VERSION "dbc-export 1 2025.20.8"

NS_ :

BS_:

BU_: ADSP APB APP APS APSB BB BMS CC CMP CMPD CP DAS DI DIF DIR DPB EPAS3P EPAS3S EPASTP EPASTS EPBL EPBR ESP EVSE FC GTW HCML HCMR HVP IBST ICR IDB LS OCS1P ODIN PARK PCS PLG PM PMF PMR PNCD PTC RADC RCM RCM2 RCM3 RCU SCCM SCM SCS SDCR TAS TCU TPMS TRCM UDS UI UIS UMC USM VC VCFRONT VCLEFT VCRIGHT VCSEC VEH

BO_ 2030 TRCM_alertMatrix: 8 TRCM
 SG_ TRCM_matrixIndex M : 0|4@1+ (1,0) [0|15] "" Vector__XXX
 SG_ TRCM_a003_SWAssertion m0 : 6|1@1+ (1,0) [0|1] "" Vector__XXX
 SG_ TRCM_a005_CANTXError m0 : 8|1@1+ (1,0) [0|1] "" Vector__XXX
 SG_ TRCM_a006_CANTX_cyclicError m0 : 9|1@1+ (1,0) [0|1] "" Vector__XXX
 SG_ TRCM_a007_chassisChecksumError m0 : 10|1@1+ (1,0) [0|1] "" Vector__XXX
 SG_ TRCM_a008_chassisCounterError m0 : 11|1@1+ (1,0) [0|1] "" Vector__XXX
 SG_ TRCM_a009_partyChecksumError m0 : 12|1@1+ (1,0) [0|1] "" Vector__XXX
 SG_ TRCM_a010_partyCounterError m0 : 13|1@1+ (1,0) [0|1] "" Vector__XXX
 SG_ TRCM_a012_asm5TemperatureOutside m0 : 15|1@1+ (1,0) [0|1] "" Vector__XXX
 SG_ TRCM_a013_AlertManagerFault m0 : 16|1@1+ (1,0) [0|1] "" Vector__XXX
 SG_ TRCM_a014_asm3TemperatureOutside m0 : 17|1@1+ (1,0) [0|1] "" Vector__XXX
 SG_ TRCM_a015_NVMMError m0 : 18|1@1+ (1,0) [0|1] "" Vector__XXX
 SG_ TRCM_a016_NVMMRecordError m0 : 19|1@1+ (1,0) [0|1] "" Vector__XXX
 SG_ TRCM_a017_asm5TemperatureOutside m0 : 20|1@1+ (1,0) [0|1] "" Vector__XXX
 SG_ TRCM_a018_asm3TemperatureOutside m0 : 21|1@1+ (1,0) [0|1] "" Vector__XXX
 SG_ TRCM_a019_Task500usError m0 : 22|1@1+ (1,0) [0|1] "" Vector__XXX
 SG_ TRCM_a020_asm3ComStatusError m0 : 23|1@1+ (1,0) [0|1] "" Vector__XXX
 SG_ TRCM_a021_TaskSchedulerError m0 : 24|1@1+ (1,0) [0|1] "" Vector__XXX
 SG_ TRCM_a022_TaskInitError m0 : 25|1@1+ (1,0) [0|1] "" Vector__XXX
 SG_ TRCM_a023_asm3ArsStatusXError m0 : 26|1@1+ (1,0) [0|1] "" Vector__XXX
 SG_ TRCM_a024_asm3AccStatusError m0 : 27|1@1+ (1,0) [0|1] "" Vector__XXX
 SG_ TRCM_a025_CHCANBusFaults m0 : 28|1@1+ (1,0) [0|1] "" Vector__XXX
 SG_ TRCM_a026_airbagAsicDiagnosticFa m0 : 29|1@1+ (1,0) [0|1] "" Vector__XXX
 SG_ TRCM_a027_airbagAsicDeploymentDi m0 : 30|1@1+ (1,0) [0|1] "" Vector__XXX
 SG_ TRCM_a030_ECULogUploadRequest m0 : 33|1@1+ (1,0) [0|1] "" Vector__XXX
 SG_ TRCM_a031_UDSActive m0 : 34|1@1+ (1,0) [0|1] "" Vector__XXX
 SG_ TRCM_a033_HercLogCreated m0 : 36|1@1+ (1,0) [0|1] "" Vector__XXX
 SG_ TRCM_a034_apClipTrigger m0 : 37|1@1+ (1,0) [0|1] "" Vector__XXX
 SG_ TRCM_a035_hvDisconnectCommanded m0 : 38|1@1+ (1,0) [0|1] "" Vector__XXX
 SG_ TRCM_a041_HighCPULoad m0 : 44|1@1+ (1,0) [0|1] "" Vector__XXX
 SG_ TRCM_a042_HighStackUsage m0 : 45|1@1+ (1,0) [0|1] "" Vector__XXX
 SG_ TRCM_a043_Task1msError m0 : 46|1@1+ (1,0) [0|1] "" Vector__XXX
 SG_ TRCM_a044_Task10msError m0 : 47|1@1+ (1,0) [0|1] "" Vector__XXX
 SG_ TRCM_a045_Task100msError m0 : 48|1@1+ (1,0) [0|1] "" Vector__XXX
 SG_ TRCM_a046_Task1000msError m0 : 49|1@1+ (1,0) [0|1] "" Vector__XXX
 SG_ TRCM_a057_HVP_MIA m0 : 60|1@1+ (1,0) [0|1] "" Vector__XXX
 SG_ TRCM_a058_inputRHighSyncDebug m0 : 61|1@1+ (1,0) [0|1] "" Vector__XXX
 SG_ TRCM_a059_inputResistanceHigh m0 : 62|1@1+ (1,0) [0|1] "" Vector__XXX
 SG_ TRCM_a060_engineeringBuild m0 : 63|1@1+ (1,0) [0|1] "" Vector__XXX
 SG_ TRCM_a061_XCPConnected m1 : 4|1@1+ (1,0) [0|1] "" Vector__XXX
 SG_ TRCM_a062_XCPWasConnected m1 : 5|1@1+ (1,0) [0|1] "" Vector__XXX
 SG_ TRCM_a063_SwitchFault m1 : 6|1@1+ (1,0) [0|1] "" Vector__XXX
 SG_ TRCM_a064_busSleepReqTimeout m1 : 7|1@1+ (1,0) [0|1] "" Vector__XXX
 SG_ TRCM_a065_vSafingFetUnderVoltage m1 : 8|1@1+ (1,0) [0|1] "" Vector__XXX
 SG_ TRCM_a066_vBusAUnderVoltage m1 : 9|1@1+ (1,0) [0|1] "" Vector__XXX
 SG_ TRCM_a067_vBusBUnderVoltage m1 : 10|1@1+ (1,0) [0|1] "" Vector__XXX
 SG_ TRCM_a068_vBusCUnderVoltage m1 : 11|1@1+ (1,0) [0|1] "" Vector__XXX
 SG_ TRCM_a069_swAppBoot m1 : 12|1@1+ (1,0) [0|1] "" Vector__XXX
 SG_ TRCM_a070_asm3StatusError m1 : 13|1@1+ (1,0) [0|1] "" Vector__XXX
 SG_ TRCM_a071_asm3DeviceFaulted m1 : 14|1@1+ (1,0) [0|1] "" Vector__XXX
 SG_ TRCM_a072_ais2120StatusError m1 : 15|1@1+ (1,0) [0|1] "" Vector__XXX
 SG_ TRCM_a073_ais2120DeviceFaulted m1 : 16|1@1+ (1,0) [0|1] "" Vector__XXX
 SG_ TRCM_a074_ais2120SelfTestXPositi m1 : 17|1@1+ (1,0) [0|1] "" Vector__XXX
 SG_ TRCM_a075_ais2120SelfTestXNegati m1 : 18|1@1+ (1,0) [0|1] "" Vector__XXX
 SG_ TRCM_a076_ais2120SelfTestYPositi m1 : 19|1@1+ (1,0) [0|1] "" Vector__XXX
 SG_ TRCM_a077_ais2120SelfTestYNegati m1 : 20|1@1+ (1,0) [0|1] "" Vector__XXX
 SG_ TRCM_a081_autarkyActive m1 : 24|1@1+ (1,0) [0|1] "" Vector__XXX
 SG_ TRCM_a082_VCRIGHT_IPC_MIA m1 : 25|1@1+ (1,0) [0|1] "" Vector__XXX
 SG_ TRCM_a083_VCLEFT_IPC_MIA m1 : 26|1@1+ (1,0) [0|1] "" Vector__XXX
 SG_ TRCM_a084_TPMS_MIA m1 : 27|1@1+ (1,0) [0|1] "" Vector__XXX
 SG_ TRCM_a085_CCCM_MIA m1 : 28|1@1+ (1,0) [0|1] "" Vector__XXX
 SG_ TRCM_a086_VCBATT_MIA m1 : 29|1@1+ (1,0) [0|1] "" Vector__XXX
 SG_ TRCM_a087_DIREL_MIA m1 : 30|1@1+ (1,0) [0|1] "" Vector__XXX
 SG_ TRCM_a088_DIRER_MIA m1 : 31|1@1+ (1,0) [0|1] "" Vector__XXX
 SG_ TRCM_a089_IBST_MIA m1 : 32|1@1+ (1,0) [0|1] "" Vector__XXX
 SG_ TRCM_a090_APS_MIA m1 : 33|1@1+ (1,0) [0|1] "" Vector__XXX
 SG_ TRCM_a091_CMPD_MIA m1 : 34|1@1+ (1,0) [0|1] "" Vector__XXX
 SG_ TRCM_a092_VCSEATD_MIA m1 : 35|1@1+ (1,0) [0|1] "" Vector__XXX
 SG_ TRCM_a093_VCSEATP_MIA m1 : 36|1@1+ (1,0) [0|1] "" Vector__XXX
 SG_ TRCM_a094_EPAS3P_MIA m1 : 37|1@1+ (1,0) [0|1] "" Vector__XXX
 SG_ TRCM_a095_CHG_MIA m1 : 38|1@1+ (1,0) [0|1] "" Vector__XXX
 SG_ TRCM_a096_OCS1P_MIA m1 : 39|1@1+ (1,0) [0|1] "" Vector__XXX
 SG_ TRCM_a097_CMP_MIA m1 : 40|1@1+ (1,0) [0|1] "" Vector__XXX
 SG_ TRCM_a098_DIR_MIA m1 : 41|1@1+ (1,0) [0|1] "" Vector__XXX
 SG_ TRCM_a099_PARK_MIA m1 : 42|1@1+ (1,0) [0|1] "" Vector__XXX
 SG_ TRCM_a100_CANbus_MIA m1 : 43|1@1+ (1,0) [0|1] "" Vector__XXX
 SG_ TRCM_a101_PM_MIA m1 : 44|1@1+ (1,0) [0|1] "" Vector__XXX
 SG_ TRCM_a102_PTC_MIA m1 : 45|1@1+ (1,0) [0|1] "" Vector__XXX
 SG_ TRCM_a103_CP_MIA m1 : 46|1@1+ (1,0) [0|1] "" Vector__XXX
 SG_ TRCM_a104_DAS_MIA m1 : 47|1@1+ (1,0) [0|1] "" Vector__XXX
 SG_ TRCM_a105_TAS_MIA m1 : 48|1@1+ (1,0) [0|1] "" Vector__XXX
 SG_ TRCM_a106_PCS_MIA m1 : 49|1@1+ (1,0) [0|1] "" Vector__XXX
 SG_ TRCM_a107_BMS_MIA m1 : 50|1@1+ (1,0) [0|1] "" Vector__XXX
 SG_ TRCM_a108_DIF_MIA m1 : 51|1@1+ (1,0) [0|1] "" Vector__XXX
 SG_ TRCM_a109_RCM_MIA m1 : 52|1@1+ (1,0) [0|1] "" Vector__XXX
 SG_ TRCM_a110_GTW_MIA m1 : 53|1@1+ (1,0) [0|1] "" Vector__XXX
 SG_ TRCM_a111_EPBR_MIA m1 : 54|1@1+ (1,0) [0|1] "" Vector__XXX
 SG_ TRCM_a112_EPBL_MIA m1 : 55|1@1+ (1,0) [0|1] "" Vector__XXX
 SG_ TRCM_a113_UI_MIA m1 : 56|1@1+ (1,0) [0|1] "" Vector__XXX
 SG_ TRCM_a114_ESP_MIA m1 : 57|1@1+ (1,0) [0|1] "" Vector__XXX
 SG_ TRCM_a115_VCSEC_MIA m1 : 58|1@1+ (1,0) [0|1] "" Vector__XXX
 SG_ TRCM_a116_VCRIGHT_MIA m1 : 59|1@1+ (1,0) [0|1] "" Vector__XXX
 SG_ TRCM_a117_VCLEFT_MIA m1 : 60|1@1+ (1,0) [0|1] "" Vector__XXX
 SG_ TRCM_a118_VCFRONT_MIA m1 : 61|1@1+ (1,0) [0|1] "" Vector__XXX
 SG_ TRCM_a119_SCCM_MIA m1 : 62|1@1+ (1,0) [0|1] "" Vector__XXX
 SG_ TRCM_a120_DI_DRIVE_MIA m1 : 63|1@1+ (1,0) [0|1] "" Vector__XXX
 SG_ TRCM_a121_glacierInitialStatusFa m2 : 4|1@1+ (1,0) [0|1] "" Vector__XXX
 SG_ TRCM_a122_glacierTraceabilityRea m2 : 5|1@1+ (1,0) [0|1] "" Vector__XXX
 SG_ TRCM_a123_glacierTraceabilityRea m2 : 6|1@1+ (1,0) [0|1] "" Vector__XXX
 SG_ TRCM_a124_glacierRegisterPattern m2 : 7|1@1+ (1,0) [0|1] "" Vector__XXX
 SG_ TRCM_a125_glacierFixedPatternSel m2 : 8|1@1+ (1,0) [0|1] "" Vector__XXX
 SG_ TRCM_a126_glacierSelfTestEFailur m2 : 9|1@1+ (1,0) [0|1] "" Vector__XXX
 SG_ TRCM_a127_glacierSelfTestFFailur m2 : 10|1@1+ (1,0) [0|1] "" Vector__XXX
 SG_ TRCM_a128_glacierAnalogSelfTestF m2 : 11|1@1+ (1,0) [0|1] "" Vector__XXX
 SG_ TRCM_a129_glacierOscillatorVerif m2 : 12|1@1+ (1,0) [0|1] "" Vector__XXX
 SG_ TRCM_a130_glacierFinalStatusFail m2 : 13|1@1+ (1,0) [0|1] "" Vector__XXX
 SG_ TRCM_a131_glacierOffsetVerificat m2 : 14|1@1+ (1,0) [0|1] "" Vector__XXX
 SG_ TRCM_a132_glacierNormalOperation m2 : 15|1@1+ (1,0) [0|1] "" Vector__XXX
 SG_ TRCM_a133_glacierDeviceReset m2 : 16|1@1+ (1,0) [0|1] "" Vector__XXX
 SG_ TRCM_a134_glacierDeviceFaulted m2 : 17|1@1+ (1,0) [0|1] "" Vector__XXX
 SG_ TRCM_a135_asm5StatusError m2 : 18|1@1+ (1,0) [0|1] "" Vector__XXX
 SG_ TRCM_a136_asm5DeviceFaulted m2 : 19|1@1+ (1,0) [0|1] "" Vector__XXX
 SG_ TRCM_a137_ext1AsicSnoopTestFaile m2 : 20|1@1+ (1,0) [0|1] "" Vector__XXX
 SG_ TRCM_a138_ext2AsicSnoopTestFaile m2 : 21|1@1+ (1,0) [0|1] "" Vector__XXX
 SG_ TRCM_a139_disarmed m2 : 22|1@1+ (1,0) [0|1] "" Vector__XXX
 SG_ TRCM_a140_frontRightAccelInitFai m2 : 23|1@1+ (1,0) [0|1] "" Vector__XXX
 SG_ TRCM_a141_frontRightAccelShortTo m2 : 24|1@1+ (1,0) [0|1] "" Vector__XXX
 SG_ TRCM_a142_frontRightAccelShortTo m2 : 25|1@1+ (1,0) [0|1] "" Vector__XXX
 SG_ TRCM_a143_frontRightAccelConfigE m2 : 26|1@1+ (1,0) [0|1] "" Vector__XXX
 SG_ TRCM_a144_frontRightAccelOpen m2 : 27|1@1+ (1,0) [0|1] "" Vector__XXX
 SG_ TRCM_a145_frontRightAccelCommErr m2 : 28|1@1+ (1,0) [0|1] "" Vector__XXX
 SG_ TRCM_a146_frontRightAccelSensorD m2 : 29|1@1+ (1,0) [0|1] "" Vector__XXX
 SG_ TRCM_a147_frontRightAccelSignalM m2 : 30|1@1+ (1,0) [0|1] "" Vector__XXX
 SG_ TRCM_a150_rightFrontDoorPressure m2 : 33|1@1+ (1,0) [0|1] "" Vector__XXX
 SG_ TRCM_a151_rightFrontDoorPressure m2 : 34|1@1+ (1,0) [0|1] "" Vector__XXX
 SG_ TRCM_a152_rightFrontDoorPressure m2 : 35|1@1+ (1,0) [0|1] "" Vector__XXX
 SG_ TRCM_a153_rightFrontDoorPressure m2 : 36|1@1+ (1,0) [0|1] "" Vector__XXX
 SG_ TRCM_a154_rightFrontDoorPressure m2 : 37|1@1+ (1,0) [0|1] "" Vector__XXX
 SG_ TRCM_a155_rightFrontDoorPressure m2 : 38|1@1+ (1,0) [0|1] "" Vector__XXX
 SG_ TRCM_a156_rightFrontDoorPressure m2 : 39|1@1+ (1,0) [0|1] "" Vector__XXX
 SG_ TRCM_a157_rightFrontDoorPressure m2 : 40|1@1+ (1,0) [0|1] "" Vector__XXX
 SG_ TRCM_a160_frontLeftAccelInitFail m2 : 43|1@1+ (1,0) [0|1] "" Vector__XXX
 SG_ TRCM_a161_frontLeftAccelShortToG m2 : 44|1@1+ (1,0) [0|1] "" Vector__XXX
 SG_ TRCM_a162_frontLeftAccelShortToB m2 : 45|1@1+ (1,0) [0|1] "" Vector__XXX
 SG_ TRCM_a163_frontLeftAccelConfigEr m2 : 46|1@1+ (1,0) [0|1] "" Vector__XXX
 SG_ TRCM_a164_frontLeftAccelOpen m2 : 47|1@1+ (1,0) [0|1] "" Vector__XXX
 SG_ TRCM_a165_frontLeftAccelCommErro m2 : 48|1@1+ (1,0) [0|1] "" Vector__XXX
 SG_ TRCM_a166_frontLeftAccelSensorDe m2 : 49|1@1+ (1,0) [0|1] "" Vector__XXX
 SG_ TRCM_a167_frontLeftAccelSignalMo m2 : 50|1@1+ (1,0) [0|1] "" Vector__XXX
 SG_ TRCM_a170_leftFrontDoorPressureI m2 : 53|1@1+ (1,0) [0|1] "" Vector__XXX
 SG_ TRCM_a171_leftFrontDoorPressureS m2 : 54|1@1+ (1,0) [0|1] "" Vector__XXX
 SG_ TRCM_a172_leftFrontDoorPressureS m2 : 55|1@1+ (1,0) [0|1] "" Vector__XXX
 SG_ TRCM_a173_leftFrontDoorPressureC m2 : 56|1@1+ (1,0) [0|1] "" Vector__XXX
 SG_ TRCM_a174_leftFrontDoorPressureO m2 : 57|1@1+ (1,0) [0|1] "" Vector__XXX
 SG_ TRCM_a175_leftFrontDoorPressureC m2 : 58|1@1+ (1,0) [0|1] "" Vector__XXX
 SG_ TRCM_a176_leftFrontDoorPressureS m2 : 59|1@1+ (1,0) [0|1] "" Vector__XXX
 SG_ TRCM_a177_leftFrontDoorPressureS m2 : 60|1@1+ (1,0) [0|1] "" Vector__XXX
 SG_ TRCM_a180_rightBPillarAccelInitF m2 : 63|1@1+ (1,0) [0|1] "" Vector__XXX
 SG_ TRCM_a181_rightBPillarAccelShort m3 : 4|1@1+ (1,0) [0|1] "" Vector__XXX
 SG_ TRCM_a182_rightBPillarAccelShort m3 : 5|1@1+ (1,0) [0|1] "" Vector__XXX
 SG_ TRCM_a183_rightBPillarAccelConfi m3 : 6|1@1+ (1,0) [0|1] "" Vector__XXX
 SG_ TRCM_a184_rightBPillarAccelOpen m3 : 7|1@1+ (1,0) [0|1] "" Vector__XXX
 SG_ TRCM_a185_rightBPillarAccelCommE m3 : 8|1@1+ (1,0) [0|1] "" Vector__XXX
 SG_ TRCM_a186_rightBPillarAccelSenso m3 : 9|1@1+ (1,0) [0|1] "" Vector__XXX
 SG_ TRCM_a187_rightBPillarAccelSigna m3 : 10|1@1+ (1,0) [0|1] "" Vector__XXX
 SG_ TRCM_a190_leftBPillarAccelInitFa m3 : 13|1@1+ (1,0) [0|1] "" Vector__XXX
 SG_ TRCM_a191_leftBPillarAccelShortT m3 : 14|1@1+ (1,0) [0|1] "" Vector__XXX
 SG_ TRCM_a192_leftBPillarAccelShortT m3 : 15|1@1+ (1,0) [0|1] "" Vector__XXX
 SG_ TRCM_a193_leftBPillarAccelConfig m3 : 16|1@1+ (1,0) [0|1] "" Vector__XXX
 SG_ TRCM_a194_leftBPillarAccelOpen m3 : 17|1@1+ (1,0) [0|1] "" Vector__XXX
 SG_ TRCM_a195_leftBPillarAccelCommEr m3 : 18|1@1+ (1,0) [0|1] "" Vector__XXX
 SG_ TRCM_a196_leftBPillarAccelSensor m3 : 19|1@1+ (1,0) [0|1] "" Vector__XXX
 SG_ TRCM_a197_leftBPillarAccelSignal m3 : 20|1@1+ (1,0) [0|1] "" Vector__XXX
 SG_ TRCM_a200_frontCenterAccelInitFa m3 : 23|1@1+ (1,0) [0|1] "" Vector__XXX
 SG_ TRCM_a201_frontCenterAccelShortT m3 : 24|1@1+ (1,0) [0|1] "" Vector__XXX
 SG_ TRCM_a202_frontCenterAccelShortT m3 : 25|1@1+ (1,0) [0|1] "" Vector__XXX
 SG_ TRCM_a203_frontCenterAccelConfig m3 : 26|1@1+ (1,0) [0|1] "" Vector__XXX
 SG_ TRCM_a204_frontCenterAccelOpen m3 : 27|1@1+ (1,0) [0|1] "" Vector__XXX
 SG_ TRCM_a205_frontCenterAccelCommEr m3 : 28|1@1+ (1,0) [0|1] "" Vector__XXX
 SG_ TRCM_a206_frontCenterAccelSensor m3 : 29|1@1+ (1,0) [0|1] "" Vector__XXX
 SG_ TRCM_a207_frontCenterAccelSignal m3 : 30|1@1+ (1,0) [0|1] "" Vector__XXX
 SG_ TRCM_a210_leftCPillarAccelInitFa m3 : 33|1@1+ (1,0) [0|1] "" Vector__XXX
 SG_ TRCM_a211_leftCPillarAccelShortT m3 : 34|1@1+ (1,0) [0|1] "" Vector__XXX
 SG_ TRCM_a212_leftCPillarAccelShortT m3 : 35|1@1+ (1,0) [0|1] "" Vector__XXX
 SG_ TRCM_a213_leftCPillarAccelConfig m3 : 36|1@1+ (1,0) [0|1] "" Vector__XXX
 SG_ TRCM_a214_leftCPillarAccelOpen m3 : 37|1@1+ (1,0) [0|1] "" Vector__XXX
 SG_ TRCM_a215_leftCPillarAccelCommEr m3 : 38|1@1+ (1,0) [0|1] "" Vector__XXX
 SG_ TRCM_a216_leftCPillarAccelSensor m3 : 39|1@1+ (1,0) [0|1] "" Vector__XXX
 SG_ TRCM_a217_leftCPillarAccelSignal m3 : 40|1@1+ (1,0) [0|1] "" Vector__XXX
 SG_ TRCM_a220_rightCPillarAccelInitF m3 : 43|1@1+ (1,0) [0|1] "" Vector__XXX
 SG_ TRCM_a221_rightCPillarAccelShort m3 : 44|1@1+ (1,0) [0|1] "" Vector__XXX
 SG_ TRCM_a222_rightCPillarAccelShort m3 : 45|1@1+ (1,0) [0|1] "" Vector__XXX
 SG_ TRCM_a223_rightCPillarAccelConfi m3 : 46|1@1+ (1,0) [0|1] "" Vector__XXX
 SG_ TRCM_a224_rightCPillarAccelOpen m3 : 47|1@1+ (1,0) [0|1] "" Vector__XXX
 SG_ TRCM_a225_rightCPillarAccelCommE m3 : 48|1@1+ (1,0) [0|1] "" Vector__XXX
 SG_ TRCM_a226_rightCPillarAccelSenso m3 : 49|1@1+ (1,0) [0|1] "" Vector__XXX
 SG_ TRCM_a227_rightCPillarAccelSigna m3 : 50|1@1+ (1,0) [0|1] "" Vector__XXX
 SG_ TRCM_a230_leftRearDoorPressureIn m3 : 53|1@1+ (1,0) [0|1] "" Vector__XXX
 SG_ TRCM_a231_leftRearDoorPressureSh m3 : 54|1@1+ (1,0) [0|1] "" Vector__XXX
 SG_ TRCM_a232_leftRearDoorPressureSh m3 : 55|1@1+ (1,0) [0|1] "" Vector__XXX
 SG_ TRCM_a233_leftRearDoorPressureCo m3 : 56|1@1+ (1,0) [0|1] "" Vector__XXX
 SG_ TRCM_a234_leftRearDoorPressureOp m3 : 57|1@1+ (1,0) [0|1] "" Vector__XXX
 SG_ TRCM_a235_leftRearDoorPressureCo m3 : 58|1@1+ (1,0) [0|1] "" Vector__XXX
 SG_ TRCM_a236_leftRearDoorPressureSe m3 : 59|1@1+ (1,0) [0|1] "" Vector__XXX
 SG_ TRCM_a237_leftRearDoorPressureSi m3 : 60|1@1+ (1,0) [0|1] "" Vector__XXX
 SG_ TRCM_a240_rightRearDoorPressureI m3 : 63|1@1+ (1,0) [0|1] "" Vector__XXX
 SG_ TRCM_a241_rightRearDoorPressureS m4 : 4|1@1+ (1,0) [0|1] "" Vector__XXX
 SG_ TRCM_a242_rightRearDoorPressureS m4 : 5|1@1+ (1,0) [0|1] "" Vector__XXX
 SG_ TRCM_a243_rightRearDoorPressureC m4 : 6|1@1+ (1,0) [0|1] "" Vector__XXX
 SG_ TRCM_a244_rightRearDoorPressureO m4 : 7|1@1+ (1,0) [0|1] "" Vector__XXX
 SG_ TRCM_a245_rightRearDoorPressureC m4 : 8|1@1+ (1,0) [0|1] "" Vector__XXX
 SG_ TRCM_a246_rightRearDoorPressureS m4 : 9|1@1+ (1,0) [0|1] "" Vector__XXX
 SG_ TRCM_a247_rightRearDoorPressureS m4 : 10|1@1+ (1,0) [0|1] "" Vector__XXX
 SG_ TRCM_a250_frontCenterAccelXInitF m4 : 13|1@1+ (1,0) [0|1] "" Vector__XXX
 SG_ TRCM_a251_frontCenterAccelXShort m4 : 14|1@1+ (1,0) [0|1] "" Vector__XXX
 SG_ TRCM_a252_frontCenterAccelXShort m4 : 15|1@1+ (1,0) [0|1] "" Vector__XXX
 SG_ TRCM_a253_frontCenterAccelXConfi m4 : 16|1@1+ (1,0) [0|1] "" Vector__XXX
 SG_ TRCM_a254_frontCenterAccelXOpen m4 : 17|1@1+ (1,0) [0|1] "" Vector__XXX
 SG_ TRCM_a255_frontCenterAccelXCommE m4 : 18|1@1+ (1,0) [0|1] "" Vector__XXX
 SG_ TRCM_a256_frontCenterAccelXSenso m4 : 19|1@1+ (1,0) [0|1] "" Vector__XXX
 SG_ TRCM_a257_frontCenterAccelXSigna m4 : 20|1@1+ (1,0) [0|1] "" Vector__XXX
 SG_ TRCM_a260_frontCenterAccelYInitF m4 : 23|1@1+ (1,0) [0|1] "" Vector__XXX
 SG_ TRCM_a261_frontCenterAccelYShort m4 : 24|1@1+ (1,0) [0|1] "" Vector__XXX
 SG_ TRCM_a262_frontCenterAccelYShort m4 : 25|1@1+ (1,0) [0|1] "" Vector__XXX
 SG_ TRCM_a263_frontCenterAccelYConfi m4 : 26|1@1+ (1,0) [0|1] "" Vector__XXX
 SG_ TRCM_a264_frontCenterAccelYOpen m4 : 27|1@1+ (1,0) [0|1] "" Vector__XXX
 SG_ TRCM_a265_frontCenterAccelYCommE m4 : 28|1@1+ (1,0) [0|1] "" Vector__XXX
 SG_ TRCM_a266_frontCenterAccelYSenso m4 : 29|1@1+ (1,0) [0|1] "" Vector__XXX
 SG_ TRCM_a267_frontCenterAccelYSigna m4 : 30|1@1+ (1,0) [0|1] "" Vector__XXX
 SG_ TRCM_a272_asm5ComStatusError m4 : 35|1@1+ (1,0) [0|1] "" Vector__XXX
 SG_ TRCM_a273_asm5ArsStatusXError m4 : 36|1@1+ (1,0) [0|1] "" Vector__XXX
 SG_ TRCM_a274_asm5ArsStatusZError m4 : 37|1@1+ (1,0) [0|1] "" Vector__XXX
 SG_ TRCM_a275_asm5AccStatusError m4 : 38|1@1+ (1,0) [0|1] "" Vector__XXX
 SG_ TRCM_a276_watchdogStatus m4 : 39|1@1+ (1,0) [0|1] "" Vector__XXX
 SG_ TRCM_a278_safingEngine0Armed m4 : 41|1@1+ (1,0) [0|1] "" Vector__XXX
 SG_ TRCM_a279_safingEngine1Armed m4 : 42|1@1+ (1,0) [0|1] "" Vector__XXX
 SG_ TRCM_a280_safingEngine2Armed m4 : 43|1@1+ (1,0) [0|1] "" Vector__XXX
 SG_ TRCM_a281_safingEngine3Armed m4 : 44|1@1+ (1,0) [0|1] "" Vector__XXX
 SG_ TRCM_a282_safingEngine4Armed m4 : 45|1@1+ (1,0) [0|1] "" Vector__XXX
 SG_ TRCM_a283_safingEngine5Armed m4 : 46|1@1+ (1,0) [0|1] "" Vector__XXX
 SG_ TRCM_a284_safingEngine6Armed m4 : 47|1@1+ (1,0) [0|1] "" Vector__XXX
 SG_ TRCM_a285_safingEngine7Armed m4 : 48|1@1+ (1,0) [0|1] "" Vector__XXX
 SG_ TRCM_a286_safingEngine8Armed m4 : 49|1@1+ (1,0) [0|1] "" Vector__XXX
 SG_ TRCM_a287_safingEngine9Armed m4 : 50|1@1+ (1,0) [0|1] "" Vector__XXX
 SG_ TRCM_a288_safingEngine10Armed m4 : 51|1@1+ (1,0) [0|1] "" Vector__XXX
 SG_ TRCM_a289_safingEngine11Armed m4 : 52|1@1+ (1,0) [0|1] "" Vector__XXX
 SG_ TRCM_a290_safingEngine12Armed m4 : 53|1@1+ (1,0) [0|1] "" Vector__XXX
 SG_ TRCM_a291_safingEngine13Armed m4 : 54|1@1+ (1,0) [0|1] "" Vector__XXX
 SG_ TRCM_a292_safingEngine14Armed m4 : 55|1@1+ (1,0) [0|1] "" Vector__XXX
 SG_ TRCM_a293_safingEngine15Armed m4 : 56|1@1+ (1,0) [0|1] "" Vector__XXX
 SG_ TRCM_a294_safingEngine16Armed m4 : 57|1@1+ (1,0) [0|1] "" Vector__XXX
 SG_ TRCM_a295_safingEngine17Armed m4 : 58|1@1+ (1,0) [0|1] "" Vector__XXX
 SG_ TRCM_a296_safingEngine18Armed m4 : 59|1@1+ (1,0) [0|1] "" Vector__XXX
 SG_ TRCM_a297_safingEngine19Armed m4 : 60|1@1+ (1,0) [0|1] "" Vector__XXX
 SG_ TRCM_a298_safingEngine20Armed m4 : 61|1@1+ (1,0) [0|1] "" Vector__XXX
 SG_ TRCM_a299_safingEngine21Armed m4 : 62|1@1+ (1,0) [0|1] "" Vector__XXX
 SG_ TRCM_a300_unarmedAB1FPDeployComm m4 : 63|1@1+ (1,0) [0|1] "" Vector__XXX
 SG_ TRCM_a301_unarmedAB1FDDeployComm m5 : 4|1@1+ (1,0) [0|1] "" Vector__XXX
 SG_ TRCM_a302_unarmedAV1FPDeployComm m5 : 5|1@1+ (1,0) [0|1] "" Vector__XXX
 SG_ TRCM_a303_unarmedFSABDeployComma m5 : 6|1@1+ (1,0) [0|1] "" Vector__XXX
 SG_ TRCM_a304_unarmedAB2FPDeployComm m5 : 7|1@1+ (1,0) [0|1] "" Vector__XXX
 SG_ TRCM_a305_unarmedAB2FDDeployComm m5 : 8|1@1+ (1,0) [0|1] "" Vector__XXX
 SG_ TRCM_a306_unarmedAV1FDDeployComm m5 : 9|1@1+ (1,0) [0|1] "" Vector__XXX
 SG_ TRCM_a307_unarmedLoop7DeployComm m5 : 10|1@1+ (1,0) [0|1] "" Vector__XXX
 SG_ TRCM_a308_unarmedKA1FPDeployComm m5 : 11|1@1+ (1,0) [0|1] "" Vector__XXX
 SG_ TRCM_a309_unarmedKA1FDDeployComm m5 : 12|1@1+ (1,0) [0|1] "" Vector__XXX
 SG_ TRCM_a310_unarmedALLFRDeployComm m5 : 13|1@1+ (1,0) [0|1] "" Vector__XXX
 SG_ TRCM_a311_unarmedALLFLDeployComm m5 : 14|1@1+ (1,0) [0|1] "" Vector__XXX
 SG_ TRCM_a312_unarmedBT2FRDeployComm m5 : 15|1@1+ (1,0) [0|1] "" Vector__XXX
 SG_ TRCM_a313_unarmedBT2FLDeployComm m5 : 16|1@1+ (1,0) [0|1] "" Vector__XXX
 SG_ TRCM_a314_unarmedSA1FLDeployComm m5 : 17|1@1+ (1,0) [0|1] "" Vector__XXX
 SG_ TRCM_a315_unarmedSA1FRDeployComm m5 : 18|1@1+ (1,0) [0|1] "" Vector__XXX
 SG_ TRCM_a316_unarmedBT1RRDeployComm m5 : 19|1@1+ (1,0) [0|1] "" Vector__XXX
 SG_ TRCM_a317_unarmedBT1RLDeployComm m5 : 20|1@1+ (1,0) [0|1] "" Vector__XXX
 SG_ TRCM_a318_unarmedBT1FRDeployComm m5 : 21|1@1+ (1,0) [0|1] "" Vector__XXX
 SG_ TRCM_a319_unarmedBT1FLDeployComm m5 : 22|1@1+ (1,0) [0|1] "" Vector__XXX
 SG_ TRCM_a320_unarmedLoop20DeployCom m5 : 23|1@1+ (1,0) [0|1] "" Vector__XXX
 SG_ TRCM_a321_unarmedLoop21DeployCom m5 : 24|1@1+ (1,0) [0|1] "" Vector__XXX
 SG_ TRCM_a322_unarmedIC1FRDeployComm m5 : 25|1@1+ (1,0) [0|1] "" Vector__XXX
 SG_ TRCM_a323_unarmedIC1FLDeployComm m5 : 26|1@1+ (1,0) [0|1] "" Vector__XXX
 SG_ TRCM_a324_unarmedLoop24DeployCom m5 : 27|1@1+ (1,0) [0|1] "" Vector__XXX
 SG_ TRCM_a325_unarmedLoop25DeployCom m5 : 28|1@1+ (1,0) [0|1] "" Vector__XXX
 SG_ TRCM_a326_unarmedLoop26DeployCom m5 : 29|1@1+ (1,0) [0|1] "" Vector__XXX
 SG_ TRCM_a327_unarmedLoop27DeployCom m5 : 30|1@1+ (1,0) [0|1] "" Vector__XXX
 SG_ TRCM_a328_unarmedLoop28DeployCom m5 : 31|1@1+ (1,0) [0|1] "" Vector__XXX
 SG_ TRCM_a329_unarmedLoop29DeployCom m5 : 32|1@1+ (1,0) [0|1] "" Vector__XXX
 SG_ TRCM_a330_unarmedLoop30DeployCom m5 : 33|1@1+ (1,0) [0|1] "" Vector__XXX
 SG_ TRCM_a331_unarmedLoop31DeployCom m5 : 34|1@1+ (1,0) [0|1] "" Vector__XXX
 SG_ TRCM_a332_AB1FPDeployment m5 : 35|1@1+ (1,0) [0|1] "" Vector__XXX
 SG_ TRCM_a333_AB1FDDeployment m5 : 36|1@1+ (1,0) [0|1] "" Vector__XXX
 SG_ TRCM_a334_AV1FPDeployment m5 : 37|1@1+ (1,0) [0|1] "" Vector__XXX
 SG_ TRCM_a335_Loop3Deployment m5 : 38|1@1+ (1,0) [0|1] "" Vector__XXX
 SG_ TRCM_a336_AB2FPDeployment m5 : 39|1@1+ (1,0) [0|1] "" Vector__XXX
 SG_ TRCM_a337_AB2FDDeployment m5 : 40|1@1+ (1,0) [0|1] "" Vector__XXX
 SG_ TRCM_a338_AV1FDDeployment m5 : 41|1@1+ (1,0) [0|1] "" Vector__XXX
 SG_ TRCM_a339_Loop7Deployment m5 : 42|1@1+ (1,0) [0|1] "" Vector__XXX
 SG_ TRCM_a340_KA1FPDeployment m5 : 43|1@1+ (1,0) [0|1] "" Vector__XXX
 SG_ TRCM_a341_KA1FDDeployment m5 : 44|1@1+ (1,0) [0|1] "" Vector__XXX
 SG_ TRCM_a342_ALLFRDeployment m5 : 45|1@1+ (1,0) [0|1] "" Vector__XXX
 SG_ TRCM_a343_ALLFLDeployment m5 : 46|1@1+ (1,0) [0|1] "" Vector__XXX
 SG_ TRCM_a344_BT2FRDeployment m5 : 47|1@1+ (1,0) [0|1] "" Vector__XXX
 SG_ TRCM_a345_BT2FLDeployment m5 : 48|1@1+ (1,0) [0|1] "" Vector__XXX
 SG_ TRCM_a346_SA1FLDeployment m5 : 49|1@1+ (1,0) [0|1] "" Vector__XXX
 SG_ TRCM_a347_SA1FRDeployment m5 : 50|1@1+ (1,0) [0|1] "" Vector__XXX
 SG_ TRCM_a348_BT1RRDeployment m5 : 51|1@1+ (1,0) [0|1] "" Vector__XXX
 SG_ TRCM_a349_BT1RLDeployment m5 : 52|1@1+ (1,0) [0|1] "" Vector__XXX
 SG_ TRCM_a350_BT1FRDeployment m5 : 53|1@1+ (1,0) [0|1] "" Vector__XXX
 SG_ TRCM_a351_BT1FLDeployment m5 : 54|1@1+ (1,0) [0|1] "" Vector__XXX
 SG_ TRCM_a352_Loop20Deployment m5 : 55|1@1+ (1,0) [0|1] "" Vector__XXX
 SG_ TRCM_a353_Loop21Deployment m5 : 56|1@1+ (1,0) [0|1] "" Vector__XXX
 SG_ TRCM_a354_IC1FRDeployment m5 : 57|1@1+ (1,0) [0|1] "" Vector__XXX
 SG_ TRCM_a355_IC1FLDeployment m5 : 58|1@1+ (1,0) [0|1] "" Vector__XXX
 SG_ TRCM_a356_Loop24Deployment m5 : 59|1@1+ (1,0) [0|1] "" Vector__XXX
 SG_ TRCM_a357_Loop25Deployment m5 : 60|1@1+ (1,0) [0|1] "" Vector__XXX
 SG_ TRCM_a358_Loop26Deployment m5 : 61|1@1+ (1,0) [0|1] "" Vector__XXX
 SG_ TRCM_a359_Loop27Deployment m5 : 62|1@1+ (1,0) [0|1] "" Vector__XXX
 SG_ TRCM_a360_Loop28Deployment m5 : 63|1@1+ (1,0) [0|1] "" Vector__XXX
 SG_ TRCM_a361_Loop29Deployment m6 : 4|1@1+ (1,0) [0|1] "" Vector__XXX
 SG_ TRCM_a362_Loop30Deployment m6 : 5|1@1+ (1,0) [0|1] "" Vector__XXX
 SG_ TRCM_a363_Loop31Deployment m6 : 6|1@1+ (1,0) [0|1] "" Vector__XXX
 SG_ TRCM_a364_safingEngine0NoValidDa m6 : 7|1@1+ (1,0) [0|1] "" Vector__XXX
 SG_ TRCM_a365_safingEngine1NoValidDa m6 : 8|1@1+ (1,0) [0|1] "" Vector__XXX
 SG_ TRCM_a366_safingEngine2NoValidDa m6 : 9|1@1+ (1,0) [0|1] "" Vector__XXX
 SG_ TRCM_a367_safingEngine3NoValidDa m6 : 10|1@1+ (1,0) [0|1] "" Vector__XXX
 SG_ TRCM_a368_safingEngine4NoValidDa m6 : 11|1@1+ (1,0) [0|1] "" Vector__XXX
 SG_ TRCM_a369_safingEngine5NoValidDa m6 : 12|1@1+ (1,0) [0|1] "" Vector__XXX
 SG_ TRCM_a370_safingEngine6NoValidDa m6 : 13|1@1+ (1,0) [0|1] "" Vector__XXX
 SG_ TRCM_a371_safingEngine7NoValidDa m6 : 14|1@1+ (1,0) [0|1] "" Vector__XXX
 SG_ TRCM_a372_safingEngine8NoValidDa m6 : 15|1@1+ (1,0) [0|1] "" Vector__XXX
 SG_ TRCM_a373_safingEngine9NoValidDa m6 : 16|1@1+ (1,0) [0|1] "" Vector__XXX
 SG_ TRCM_a374_safingEngine10NoValidD m6 : 17|1@1+ (1,0) [0|1] "" Vector__XXX
 SG_ TRCM_a375_safingEngine11NoValidD m6 : 18|1@1+ (1,0) [0|1] "" Vector__XXX
 SG_ TRCM_a376_safingEngine12NoValidD m6 : 19|1@1+ (1,0) [0|1] "" Vector__XXX
 SG_ TRCM_a377_safingEngine13NoValidD m6 : 20|1@1+ (1,0) [0|1] "" Vector__XXX
 SG_ TRCM_a378_safingEngine14NoValidD m6 : 21|1@1+ (1,0) [0|1] "" Vector__XXX
 SG_ TRCM_a379_safingEngine15NoValidD m6 : 22|1@1+ (1,0) [0|1] "" Vector__XXX
 SG_ TRCM_a380_safingEngine16NoValidD m6 : 23|1@1+ (1,0) [0|1] "" Vector__XXX
 SG_ TRCM_a381_safingEngine17NoValidD m6 : 24|1@1+ (1,0) [0|1] "" Vector__XXX
 SG_ TRCM_a382_safingEngine18NoValidD m6 : 25|1@1+ (1,0) [0|1] "" Vector__XXX
 SG_ TRCM_a383_safingEngine19NoValidD m6 : 26|1@1+ (1,0) [0|1] "" Vector__XXX
 SG_ TRCM_a384_safingEngine20NoValidD m6 : 27|1@1+ (1,0) [0|1] "" Vector__XXX
 SG_ TRCM_a385_safingEngine21NoValidD m6 : 28|1@1+ (1,0) [0|1] "" Vector__XXX
 SG_ TRCM_a387_primaryAsicResetSource m6 : 30|1@1+ (1,0) [0|1] "" Vector__XXX
 SG_ TRCM_a388_cpuLoadHigh m6 : 31|1@1+ (1,0) [0|1] "" Vector__XXX
 SG_ TRCM_a389_asicPwrStatusError m6 : 32|1@1+ (1,0) [0|1] "" Vector__XXX
 SG_ TRCM_a390_systemAsicClockOrOpera m6 : 33|1@1+ (1,0) [0|1] "" Vector__XXX
 SG_ TRCM_a391_extAsic1ClockOrOperati m6 : 34|1@1+ (1,0) [0|1] "" Vector__XXX
 SG_ TRCM_a392_extAsic2ClockOrOperati m6 : 35|1@1+ (1,0) [0|1] "" Vector__XXX
 SG_ TRCM_a393_depAdcConvertRatioErro m6 : 36|1@1+ (1,0) [0|1] "" Vector__XXX
 SG_ TRCM_a394_gspiGlobalStatusWordEr m6 : 37|1@1+ (1,0) [0|1] "" Vector__XXX
 SG_ TRCM_a395_imuCalibrationNotDone m6 : 38|1@1+ (1,0) [0|1] "" Vector__XXX
 SG_ TRCM_a396_spiCommunicationProgra m6 : 39|1@1+ (1,0) [0|1] "" Vector__XXX
 SG_ TRCM_a397_safingMonitorError m6 : 40|1@1+ (1,0) [0|1] "" Vector__XXX
 SG_ TRCM_a398_asicNvmReprogrammed m6 : 41|1@1+ (1,0) [0|1] "" Vector__XXX
 SG_ TRCM_a400_AB1FPShortToGround m6 : 43|1@1+ (1,0) [0|1] "" Vector__XXX
 SG_ TRCM_a401_AB1FPShortToBattery m6 : 44|1@1+ (1,0) [0|1] "" Vector__XXX
 SG_ TRCM_a402_AB1FPOpen m6 : 45|1@1+ (1,0) [0|1] "" Vector__XXX
 SG_ TRCM_a403_AB1FPShortToSelf m6 : 46|1@1+ (1,0) [0|1] "" Vector__XXX
 SG_ TRCM_a404_AB1FPCrossCoupled m6 : 47|1@1+ (1,0) [0|1] "" Vector__XXX
 SG_ TRCM_a405_AB1FPConfigError m6 : 48|1@1+ (1,0) [0|1] "" Vector__XXX
 SG_ TRCM_a406_AB1FDShortToGround m6 : 49|1@1+ (1,0) [0|1] "" Vector__XXX
 SG_ TRCM_a407_AB1FDShortToBattery m6 : 50|1@1+ (1,0) [0|1] "" Vector__XXX
 SG_ TRCM_a408_AB1FDOpen m6 : 51|1@1+ (1,0) [0|1] "" Vector__XXX
 SG_ TRCM_a409_AB1FDShortToSelf m6 : 52|1@1+ (1,0) [0|1] "" Vector__XXX
 SG_ TRCM_a410_AB1FDCrossCoupled m6 : 53|1@1+ (1,0) [0|1] "" Vector__XXX
 SG_ TRCM_a411_AB1FDConfigError m6 : 54|1@1+ (1,0) [0|1] "" Vector__XXX
 SG_ TRCM_a412_PAVShortToGround m6 : 55|1@1+ (1,0) [0|1] "" Vector__XXX
 SG_ TRCM_a413_PAVShortToBattery m6 : 56|1@1+ (1,0) [0|1] "" Vector__XXX
 SG_ TRCM_a414_PAVOpen m6 : 57|1@1+ (1,0) [0|1] "" Vector__XXX
 SG_ TRCM_a415_PAVShortToSelf m6 : 58|1@1+ (1,0) [0|1] "" Vector__XXX
 SG_ TRCM_a416_PAVCrossCoupled m6 : 59|1@1+ (1,0) [0|1] "" Vector__XXX
 SG_ TRCM_a417_PAVConfigError m6 : 60|1@1+ (1,0) [0|1] "" Vector__XXX
 SG_ TRCM_a418_AB2FPShortToGround m6 : 61|1@1+ (1,0) [0|1] "" Vector__XXX
 SG_ TRCM_a419_AB2FPShortToBattery m6 : 62|1@1+ (1,0) [0|1] "" Vector__XXX
 SG_ TRCM_a420_AB2FPOpen m6 : 63|1@1+ (1,0) [0|1] "" Vector__XXX
 SG_ TRCM_a421_AB2FPShortToSelf m7 : 4|1@1+ (1,0) [0|1] "" Vector__XXX
 SG_ TRCM_a422_AB2FPCrossCoupled m7 : 5|1@1+ (1,0) [0|1] "" Vector__XXX
 SG_ TRCM_a423_AB2FPConfigError m7 : 6|1@1+ (1,0) [0|1] "" Vector__XXX
 SG_ TRCM_a424_AB2FDShortToGround m7 : 7|1@1+ (1,0) [0|1] "" Vector__XXX
 SG_ TRCM_a425_AB2FDShortToBattery m7 : 8|1@1+ (1,0) [0|1] "" Vector__XXX
 SG_ TRCM_a426_AB2FDOpen m7 : 9|1@1+ (1,0) [0|1] "" Vector__XXX
 SG_ TRCM_a427_AB2FDShortToSelf m7 : 10|1@1+ (1,0) [0|1] "" Vector__XXX
 SG_ TRCM_a428_AB2FDCrossCoupled m7 : 11|1@1+ (1,0) [0|1] "" Vector__XXX
 SG_ TRCM_a429_AB2FDConfigError m7 : 12|1@1+ (1,0) [0|1] "" Vector__XXX
 SG_ TRCM_a430_DAVShortToGround m7 : 13|1@1+ (1,0) [0|1] "" Vector__XXX
 SG_ TRCM_a431_DAVShortToBattery m7 : 14|1@1+ (1,0) [0|1] "" Vector__XXX
 SG_ TRCM_a432_DAVOpen m7 : 15|1@1+ (1,0) [0|1] "" Vector__XXX
 SG_ TRCM_a433_DAVShortToSelf m7 : 16|1@1+ (1,0) [0|1] "" Vector__XXX
 SG_ TRCM_a434_DAVCrossCoupled m7 : 17|1@1+ (1,0) [0|1] "" Vector__XXX
 SG_ TRCM_a435_DAVConfigError m7 : 18|1@1+ (1,0) [0|1] "" Vector__XXX
 SG_ TRCM_a436_IKBFPShortToGround m7 : 19|1@1+ (1,0) [0|1] "" Vector__XXX
 SG_ TRCM_a437_IKBFPShortToBattery m7 : 20|1@1+ (1,0) [0|1] "" Vector__XXX
 SG_ TRCM_a438_IKBFPOpen m7 : 21|1@1+ (1,0) [0|1] "" Vector__XXX
 SG_ TRCM_a439_IKBFPShortToSelf m7 : 22|1@1+ (1,0) [0|1] "" Vector__XXX
 SG_ TRCM_a440_IKBFPCrossCoupled m7 : 23|1@1+ (1,0) [0|1] "" Vector__XXX
 SG_ TRCM_a441_IKBFPConfigError m7 : 24|1@1+ (1,0) [0|1] "" Vector__XXX
 SG_ TRCM_a442_IKBFDShortToGround m7 : 25|1@1+ (1,0) [0|1] "" Vector__XXX
 SG_ TRCM_a443_IKBFDShortToBattery m7 : 26|1@1+ (1,0) [0|1] "" Vector__XXX
 SG_ TRCM_a444_IKBFDOpen m7 : 27|1@1+ (1,0) [0|1] "" Vector__XXX
 SG_ TRCM_a445_IKBFDShortToSelf m7 : 28|1@1+ (1,0) [0|1] "" Vector__XXX
 SG_ TRCM_a446_IKBFDCrossCoupled m7 : 29|1@1+ (1,0) [0|1] "" Vector__XXX
 SG_ TRCM_a447_IKBFDConfigError m7 : 30|1@1+ (1,0) [0|1] "" Vector__XXX
 SG_ TRCM_a448_PLLShortToGround m7 : 31|1@1+ (1,0) [0|1] "" Vector__XXX
 SG_ TRCM_a449_PLLShortToBattery m7 : 32|1@1+ (1,0) [0|1] "" Vector__XXX
 SG_ TRCM_a450_PLLOpen m7 : 33|1@1+ (1,0) [0|1] "" Vector__XXX
 SG_ TRCM_a451_PLLShortToSelf m7 : 34|1@1+ (1,0) [0|1] "" Vector__XXX
 SG_ TRCM_a452_PLLCrossCoupled m7 : 35|1@1+ (1,0) [0|1] "" Vector__XXX
 SG_ TRCM_a453_PLLConfigError m7 : 36|1@1+ (1,0) [0|1] "" Vector__XXX
 SG_ TRCM_a454_DLLShortToGround m7 : 37|1@1+ (1,0) [0|1] "" Vector__XXX
 SG_ TRCM_a455_DLLShortToBattery m7 : 38|1@1+ (1,0) [0|1] "" Vector__XXX
 SG_ TRCM_a456_DLLOpen m7 : 39|1@1+ (1,0) [0|1] "" Vector__XXX
 SG_ TRCM_a457_DLLShortToSelf m7 : 40|1@1+ (1,0) [0|1] "" Vector__XXX
 SG_ TRCM_a458_DLLCrossCoupled m7 : 41|1@1+ (1,0) [0|1] "" Vector__XXX
 SG_ TRCM_a459_DLLConfigError m7 : 42|1@1+ (1,0) [0|1] "" Vector__XXX
 SG_ TRCM_a460_BTRP_RetractorShortToG m7 : 43|1@1+ (1,0) [0|1] "" Vector__XXX
 SG_ TRCM_a461_BTRP_RetractorShortToB m7 : 44|1@1+ (1,0) [0|1] "" Vector__XXX
 SG_ TRCM_a462_BTRP_RetractorOpen m7 : 45|1@1+ (1,0) [0|1] "" Vector__XXX
 SG_ TRCM_a463_BTRP_RetractorShortToS m7 : 46|1@1+ (1,0) [0|1] "" Vector__XXX
 SG_ TRCM_a464_BTRP_RetractorCrossCou m7 : 47|1@1+ (1,0) [0|1] "" Vector__XXX
 SG_ TRCM_a465_BTRP_RetractorConfigEr m7 : 48|1@1+ (1,0) [0|1] "" Vector__XXX
 SG_ TRCM_a466_BTRD_RetractorShortToG m7 : 49|1@1+ (1,0) [0|1] "" Vector__XXX
 SG_ TRCM_a467_BTRD_RetractorShortToB m7 : 50|1@1+ (1,0) [0|1] "" Vector__XXX
 SG_ TRCM_a468_BTRD_RetractorOpen m7 : 51|1@1+ (1,0) [0|1] "" Vector__XXX
 SG_ TRCM_a469_BTRD_RetractorShortToS m7 : 52|1@1+ (1,0) [0|1] "" Vector__XXX
 SG_ TRCM_a470_BTRD_RetractorCrossCou m7 : 53|1@1+ (1,0) [0|1] "" Vector__XXX
 SG_ TRCM_a471_BTRD_RetractorConfigEr m7 : 54|1@1+ (1,0) [0|1] "" Vector__XXX
 SG_ TRCM_a472_SA1FLShortToGround m7 : 55|1@1+ (1,0) [0|1] "" Vector__XXX
 SG_ TRCM_a473_SA1FLShortToBattery m7 : 56|1@1+ (1,0) [0|1] "" Vector__XXX
 SG_ TRCM_a474_SA1FLOpen m7 : 57|1@1+ (1,0) [0|1] "" Vector__XXX
 SG_ TRCM_a475_SA1FLShortToSelf m7 : 58|1@1+ (1,0) [0|1] "" Vector__XXX
 SG_ TRCM_a476_SA1FLCrossCoupled m7 : 59|1@1+ (1,0) [0|1] "" Vector__XXX
 SG_ TRCM_a477_SA1FLConfigError m7 : 60|1@1+ (1,0) [0|1] "" Vector__XXX
 SG_ TRCM_a478_SA1FRShortToGround m7 : 61|1@1+ (1,0) [0|1] "" Vector__XXX
 SG_ TRCM_a479_SA1FRShortToBattery m7 : 62|1@1+ (1,0) [0|1] "" Vector__XXX
 SG_ TRCM_a480_SA1FROpen m7 : 63|1@1+ (1,0) [0|1] "" Vector__XXX
 SG_ TRCM_a481_SA1FRShortToSelf m8 : 4|1@1+ (1,0) [0|1] "" Vector__XXX
 SG_ TRCM_a482_SA1FRCrossCoupled m8 : 5|1@1+ (1,0) [0|1] "" Vector__XXX
 SG_ TRCM_a483_SA1FRConfigError m8 : 6|1@1+ (1,0) [0|1] "" Vector__XXX
 SG_ TRCM_a484_BTRRShortToGround m8 : 7|1@1+ (1,0) [0|1] "" Vector__XXX
 SG_ TRCM_a485_BTRRShortToBattery m8 : 8|1@1+ (1,0) [0|1] "" Vector__XXX
 SG_ TRCM_a486_BTRROpen m8 : 9|1@1+ (1,0) [0|1] "" Vector__XXX
 SG_ TRCM_a487_BTRRShortToSelf m8 : 10|1@1+ (1,0) [0|1] "" Vector__XXX
 SG_ TRCM_a488_BTRRCrossCoupled m8 : 11|1@1+ (1,0) [0|1] "" Vector__XXX
 SG_ TRCM_a489_BTRRConfigError m8 : 12|1@1+ (1,0) [0|1] "" Vector__XXX
 SG_ TRCM_a490_BTRLShortToGround m8 : 13|1@1+ (1,0) [0|1] "" Vector__XXX
 SG_ TRCM_a491_BTRLShortToBattery m8 : 14|1@1+ (1,0) [0|1] "" Vector__XXX
 SG_ TRCM_a492_BTRLOpen m8 : 15|1@1+ (1,0) [0|1] "" Vector__XXX
 SG_ TRCM_a493_BTRLShortToSelf m8 : 16|1@1+ (1,0) [0|1] "" Vector__XXX
 SG_ TRCM_a494_BTRLCrossCoupled m8 : 17|1@1+ (1,0) [0|1] "" Vector__XXX
 SG_ TRCM_a495_BTRLConfigError m8 : 18|1@1+ (1,0) [0|1] "" Vector__XXX
 SG_ TRCM_a496_BTRP_AnchorShortToGrou m8 : 19|1@1+ (1,0) [0|1] "" Vector__XXX
 SG_ TRCM_a497_BTRP_AnchorShortToBatt m8 : 20|1@1+ (1,0) [0|1] "" Vector__XXX
 SG_ TRCM_a498_BTRP_AnchorOpen m8 : 21|1@1+ (1,0) [0|1] "" Vector__XXX
 SG_ TRCM_a499_BTRP_AnchorShortToSelf m8 : 22|1@1+ (1,0) [0|1] "" Vector__XXX
 SG_ TRCM_a500_BTRP_AnchorCrossCouple m8 : 23|1@1+ (1,0) [0|1] "" Vector__XXX
 SG_ TRCM_a501_BTRP_AnchorConfigError m8 : 24|1@1+ (1,0) [0|1] "" Vector__XXX
 SG_ TRCM_a502_BTRD_AnchorShortToGrou m8 : 25|1@1+ (1,0) [0|1] "" Vector__XXX
 SG_ TRCM_a503_BTRD_AnchorShortToBatt m8 : 26|1@1+ (1,0) [0|1] "" Vector__XXX
 SG_ TRCM_a504_BTRD_AnchorOpen m8 : 27|1@1+ (1,0) [0|1] "" Vector__XXX
 SG_ TRCM_a505_BTRD_AnchorShortToSelf m8 : 28|1@1+ (1,0) [0|1] "" Vector__XXX
 SG_ TRCM_a506_BTRD_AnchorCrossCouple m8 : 29|1@1+ (1,0) [0|1] "" Vector__XXX
 SG_ TRCM_a507_BTRD_AnchorConfigError m8 : 30|1@1+ (1,0) [0|1] "" Vector__XXX
 SG_ TRCM_a508_IC1FRShortToGround m8 : 31|1@1+ (1,0) [0|1] "" Vector__XXX
 SG_ TRCM_a509_IC1FRShortToBattery m8 : 32|1@1+ (1,0) [0|1] "" Vector__XXX
 SG_ TRCM_a510_IC1FROpen m8 : 33|1@1+ (1,0) [0|1] "" Vector__XXX
 SG_ TRCM_a511_IC1FRShortToSelf m8 : 34|1@1+ (1,0) [0|1] "" Vector__XXX
 SG_ TRCM_a512_IC1FRCrossCoupled m8 : 35|1@1+ (1,0) [0|1] "" Vector__XXX
 SG_ TRCM_a513_IC1FRConfigError m8 : 36|1@1+ (1,0) [0|1] "" Vector__XXX
 SG_ TRCM_a514_IC1FLShortToGround m8 : 37|1@1+ (1,0) [0|1] "" Vector__XXX
 SG_ TRCM_a515_IC1FLShortToBattery m8 : 38|1@1+ (1,0) [0|1] "" Vector__XXX
 SG_ TRCM_a516_IC1FLOpen m8 : 39|1@1+ (1,0) [0|1] "" Vector__XXX
 SG_ TRCM_a517_IC1FLShortToSelf m8 : 40|1@1+ (1,0) [0|1] "" Vector__XXX
 SG_ TRCM_a518_IC1FLCrossCoupled m8 : 41|1@1+ (1,0) [0|1] "" Vector__XXX
 SG_ TRCM_a519_IC1FLConfigError m8 : 42|1@1+ (1,0) [0|1] "" Vector__XXX
 SG_ TRCM_a520_FSABShortToGround m8 : 43|1@1+ (1,0) [0|1] "" Vector__XXX
 SG_ TRCM_a521_FSABShortToBattery m8 : 44|1@1+ (1,0) [0|1] "" Vector__XXX
 SG_ TRCM_a522_FSABOpen m8 : 45|1@1+ (1,0) [0|1] "" Vector__XXX
 SG_ TRCM_a523_FSABShortToSelf m8 : 46|1@1+ (1,0) [0|1] "" Vector__XXX
 SG_ TRCM_a524_FSABCrossCoupled m8 : 47|1@1+ (1,0) [0|1] "" Vector__XXX
 SG_ TRCM_a525_FSABConfigError m8 : 48|1@1+ (1,0) [0|1] "" Vector__XXX
 SG_ TRCM_a544_erCapDiagnosticsFailed m9 : 7|1@1+ (1,0) [0|1] "" Vector__XXX
 SG_ TRCM_a545_erCapBelowAutarkyThres m9 : 8|1@1+ (1,0) [0|1] "" Vector__XXX
 SG_ TRCM_a546_sensorValuesFaultedByS m9 : 9|1@1+ (1,0) [0|1] "" Vector__XXX
 SG_ TRCM_a550_AlgoWake_RCM_WAKE_FRON m9 : 13|1@1+ (1,0) [0|1] "" Vector__XXX
 SG_ TRCM_a551_AlgoWake_RCM_WAKE_REAR m9 : 14|1@1+ (1,0) [0|1] "" Vector__XXX
 SG_ TRCM_a552_AlgoWake_RCM_WAKE_LEFT m9 : 15|1@1+ (1,0) [0|1] "" Vector__XXX
 SG_ TRCM_a553_AlgoWake_RCM_WAKE_RIGH m9 : 16|1@1+ (1,0) [0|1] "" Vector__XXX
 SG_ TRCM_a554_AlgoWake_PAS_LH_PLAUSI m9 : 17|1@1+ (1,0) [0|1] "" Vector__XXX
 SG_ TRCM_a555_AlgoWake_PAS_LH_PLAUSI m9 : 18|1@1+ (1,0) [0|1] "" Vector__XXX
 SG_ TRCM_a556_AlgoWake_PAS_LH_PLAUSI m9 : 19|1@1+ (1,0) [0|1] "" Vector__XXX
 SG_ TRCM_a557_AlgoWake_PAS_RH_PLAUSI m9 : 20|1@1+ (1,0) [0|1] "" Vector__XXX
 SG_ TRCM_a558_AlgoWake_PAS_RH_PLAUSI m9 : 21|1@1+ (1,0) [0|1] "" Vector__XXX
 SG_ TRCM_a559_AlgoWake_PAS_RH_PLAUSI m9 : 22|1@1+ (1,0) [0|1] "" Vector__XXX
 SG_ TRCM_a560_AlgoWake_RCM_WAKE_ROLL m9 : 23|1@1+ (1,0) [0|1] "" Vector__XXX
 SG_ TRCM_a561_AlgoWake_RCM_WAKE_ROLL m9 : 24|1@1+ (1,0) [0|1] "" Vector__XXX
 SG_ TRCM_a562_AlgoWake_RCM_AWAKE_FRO m9 : 25|1@1+ (1,0) [0|1] "" Vector__XXX
 SG_ TRCM_a563_AlgoWake_RCM_AWAKE_REA m9 : 26|1@1+ (1,0) [0|1] "" Vector__XXX
 SG_ TRCM_a564_AlgoWake_RCM_AWAKE_LEF m9 : 27|1@1+ (1,0) [0|1] "" Vector__XXX
 SG_ TRCM_a565_AlgoWake_RCM_AWAKE_RIG m9 : 28|1@1+ (1,0) [0|1] "" Vector__XXX
 SG_ TRCM_a566_AlgoWake_RCM_AWAKE_ROL m9 : 29|1@1+ (1,0) [0|1] "" Vector__XXX
 SG_ TRCM_a567_AlgoWake_RCM_AWAKE_X m9 : 30|1@1+ (1,0) [0|1] "" Vector__XXX
 SG_ TRCM_a568_AlgoWake_RCM_AWAKE_Y m9 : 31|1@1+ (1,0) [0|1] "" Vector__XXX
 SG_ TRCM_a569_AlgoWake_IMPACT_FINISH m9 : 32|1@1+ (1,0) [0|1] "" Vector__XXX
 SG_ TRCM_a570_AlgoWake_IMPACT_FINISH m9 : 33|1@1+ (1,0) [0|1] "" Vector__XXX
 SG_ TRCM_a571_AlgoWake_IMPACT_FINISH m9 : 34|1@1+ (1,0) [0|1] "" Vector__XXX
 SG_ TRCM_a572_AlgoWake_IMPACT_FINISH m9 : 35|1@1+ (1,0) [0|1] "" Vector__XXX
 SG_ TRCM_a573_AlgoWake_IMPACT_FINISH m9 : 36|1@1+ (1,0) [0|1] "" Vector__XXX
 SG_ TRCM_a574_AlgoWake_IMPACT_FINISH m9 : 37|1@1+ (1,0) [0|1] "" Vector__XXX
 SG_ TRCM_a575_AlgoWake_IMPACT_FINISH m9 : 38|1@1+ (1,0) [0|1] "" Vector__XXX
 SG_ TRCM_a576_AlgoWake_IMPACT_FINISH m9 : 39|1@1+ (1,0) [0|1] "" Vector__XXX
 SG_ TRCM_a577_AlgoWake_IMPACT_FINISH m9 : 40|1@1+ (1,0) [0|1] "" Vector__XXX
 SG_ TRCM_a578_AlgoWake_IMPACT_FINISH m9 : 41|1@1+ (1,0) [0|1] "" Vector__XXX
 SG_ TRCM_a579_AlgoWake_RCM_ENABLED_X m9 : 42|1@1+ (1,0) [0|1] "" Vector__XXX
 SG_ TRCM_a580_AlgoWake_RCM_ENABLED_Y m9 : 43|1@1+ (1,0) [0|1] "" Vector__XXX
 SG_ TRCM_a581_AlgoWake_RCM_ENABLED_R m9 : 44|1@1+ (1,0) [0|1] "" Vector__XXX
 SG_ TRCM_a582_AlgoWake_RCM_AWAKE m9 : 45|1@1+ (1,0) [0|1] "" Vector__XXX
 SG_ TRCM_a588_yawRateOffsetPosLimit m9 : 51|1@1+ (1,0) [0|1] "" Vector__XXX
 SG_ TRCM_a589_yawRateOffsetNegLimit m9 : 52|1@1+ (1,0) [0|1] "" Vector__XXX
 SG_ TRCM_a590_pitchRateOffsetPosLimi m9 : 53|1@1+ (1,0) [0|1] "" Vector__XXX
 SG_ TRCM_a591_pitchRateOffsetNegLimi m9 : 54|1@1+ (1,0) [0|1] "" Vector__XXX
 SG_ TRCM_a592_rollRateOffsetPosLimit m9 : 55|1@1+ (1,0) [0|1] "" Vector__XXX
 SG_ TRCM_a593_rollRateOffsetNegLimit m9 : 56|1@1+ (1,0) [0|1] "" Vector__XXX
 SG_ TRCM_a594_longitudinalAccelOffse m9 : 57|1@1+ (1,0) [0|1] "" Vector__XXX
 SG_ TRCM_a595_longitudinalAccelOffse m9 : 58|1@1+ (1,0) [0|1] "" Vector__XXX
 SG_ TRCM_a596_lateralAccelOffsetPosL m9 : 59|1@1+ (1,0) [0|1] "" Vector__XXX
 SG_ TRCM_a597_lateralAccelOffsetNegL m9 : 60|1@1+ (1,0) [0|1] "" Vector__XXX
 SG_ TRCM_a598_verticalAccelOffsetPos m9 : 61|1@1+ (1,0) [0|1] "" Vector__XXX
 SG_ TRCM_a599_verticalAccelOffsetNeg m9 : 62|1@1+ (1,0) [0|1] "" Vector__XXX
 SG_ TRCM_a600_airbagAsicStartupFailu m9 : 63|1@1+ (1,0) [0|1] "" Vector__XXX
 SG_ TRCM_a601_loop0AsicStartupDiagno m10 : 4|1@1+ (1,0) [0|1] "" Vector__XXX
 SG_ TRCM_a602_loop1AsicStartupDiagno m10 : 5|1@1+ (1,0) [0|1] "" Vector__XXX
 SG_ TRCM_a603_loop2AsicStartupDiagno m10 : 6|1@1+ (1,0) [0|1] "" Vector__XXX
 SG_ TRCM_a604_loop3AsicStartupDiagno m10 : 7|1@1+ (1,0) [0|1] "" Vector__XXX
 SG_ TRCM_a605_loop4AsicStartupDiagno m10 : 8|1@1+ (1,0) [0|1] "" Vector__XXX
 SG_ TRCM_a606_loop5AsicStartupDiagno m10 : 9|1@1+ (1,0) [0|1] "" Vector__XXX
 SG_ TRCM_a607_loop6AsicStartupDiagno m10 : 10|1@1+ (1,0) [0|1] "" Vector__XXX
 SG_ TRCM_a608_loop7AsicStartupDiagno m10 : 11|1@1+ (1,0) [0|1] "" Vector__XXX
 SG_ TRCM_a609_loop8AsicStartupDiagno m10 : 12|1@1+ (1,0) [0|1] "" Vector__XXX
 SG_ TRCM_a610_loop9AsicStartupDiagno m10 : 13|1@1+ (1,0) [0|1] "" Vector__XXX
 SG_ TRCM_a611_loop10AsicStartupDiagn m10 : 14|1@1+ (1,0) [0|1] "" Vector__XXX
 SG_ TRCM_a612_loop11AsicStartupDiagn m10 : 15|1@1+ (1,0) [0|1] "" Vector__XXX
 SG_ TRCM_a613_loop12AsicStartupDiagn m10 : 16|1@1+ (1,0) [0|1] "" Vector__XXX
 SG_ TRCM_a614_loop13AsicStartupDiagn m10 : 17|1@1+ (1,0) [0|1] "" Vector__XXX
 SG_ TRCM_a615_loop14AsicStartupDiagn m10 : 18|1@1+ (1,0) [0|1] "" Vector__XXX
 SG_ TRCM_a616_loop15AsicStartupDiagn m10 : 19|1@1+ (1,0) [0|1] "" Vector__XXX
 SG_ TRCM_a617_loop16AsicStartupDiagn m10 : 20|1@1+ (1,0) [0|1] "" Vector__XXX
 SG_ TRCM_a618_loop17AsicStartupDiagn m10 : 21|1@1+ (1,0) [0|1] "" Vector__XXX
 SG_ TRCM_a619_loop18AsicStartupDiagn m10 : 22|1@1+ (1,0) [0|1] "" Vector__XXX
 SG_ TRCM_a620_loop19AsicStartupDiagn m10 : 23|1@1+ (1,0) [0|1] "" Vector__XXX
 SG_ TRCM_a621_loop20AsicStartupDiagn m10 : 24|1@1+ (1,0) [0|1] "" Vector__XXX
 SG_ TRCM_a622_loop21AsicStartupDiagn m10 : 25|1@1+ (1,0) [0|1] "" Vector__XXX
 SG_ TRCM_a623_loop22AsicStartupDiagn m10 : 26|1@1+ (1,0) [0|1] "" Vector__XXX
 SG_ TRCM_a624_loop23AsicStartupDiagn m10 : 27|1@1+ (1,0) [0|1] "" Vector__XXX
 SG_ TRCM_a625_loop24AsicStartupDiagn m10 : 28|1@1+ (1,0) [0|1] "" Vector__XXX
 SG_ TRCM_a626_loop25AsicStartupDiagn m10 : 29|1@1+ (1,0) [0|1] "" Vector__XXX
 SG_ TRCM_a627_loop26AsicStartupDiagn m10 : 30|1@1+ (1,0) [0|1] "" Vector__XXX
 SG_ TRCM_a628_loop27AsicStartupDiagn m10 : 31|1@1+ (1,0) [0|1] "" Vector__XXX
 SG_ TRCM_a629_loop28AsicStartupDiagn m10 : 32|1@1+ (1,0) [0|1] "" Vector__XXX
 SG_ TRCM_a630_loop29AsicStartupDiagn m10 : 33|1@1+ (1,0) [0|1] "" Vector__XXX
 SG_ TRCM_a631_loop30AsicStartupDiagn m10 : 34|1@1+ (1,0) [0|1] "" Vector__XXX
 SG_ TRCM_a632_loop31AsicStartupDiagn m10 : 35|1@1+ (1,0) [0|1] "" Vector__XXX

BO_ 1641 UDS_KOSTIAsccmRequest: 8 UDS
 SG_ UDS_KOSTIAsccmRequestData : 7|64@0+ (1,0) [0|1.84467440737e+19] "" Vector__XXX

BO_ 1538 UDS_bmsRequest: 8 UDS
 SG_ UDS_bmsRequestData : 7|64@0+ (1,0) [0|1.84467440737e+19] "" Vector__XXX

BO_ 1579 UDS_ccRequest: 8 UDS
 SG_ UDS_ccRequestData : 7|64@0+ (1,0) [0|1.84467440737e+19] "" Vector__XXX

BO_ 1539 UDS_cmpRequest: 8 UDS
 SG_ UDS_cmpRequestData : 7|64@0+ (1,0) [0|1.84467440737e+19] "" Vector__XXX

BO_ 1543 UDS_cmpdRequest: 8 UDS
 SG_ UDS_cmpdRequestData : 7|64@0+ (1,0) [0|1.84467440737e+19] "" Vector__XXX

BO_ 1550 UDS_cpRequest: 8 UDS
 SG_ UDS_cpRequestData : 7|64@0+ (1,0) [0|1.84467440737e+19] "" Vector__XXX

BO_ 1609 UDS_dasRequest: 8 UDS
 SG_ UDS_dasRequestData : 7|64@0+ (1,0) [0|1.84467440737e+19] "" Vector__XXX

BO_ 1589 UDS_diRequest: 8 UDS
 SG_ UDS_diRequestData : 7|64@0+ (1,0) [0|1.84467440737e+19] "" Vector__XXX

BO_ 1541 UDS_difRequest: 8 UDS
 SG_ UDS_difRequestData : 7|64@0+ (1,0) [0|1.84467440737e+19] "" Vector__XXX

BO_ 1542 UDS_dirRequest: 8 UDS
 SG_ UDS_dirRequestData : 7|64@0+ (1,0) [0|1.84467440737e+19] "" Vector__XXX

BO_ 1584 UDS_epas3pRequest: 8 UDS
 SG_ UDS_epas3pRequestData : 7|64@0+ (1,0) [0|1.84467440737e+19] "" Vector__XXX

BO_ 1840 UDS_epas3sRequest: 8 UDS
 SG_ UDS_epas3sRequestData : 7|64@0+ (1,0) [0|1.84467440737e+19] "" Vector__XXX

BO_ 1572 UDS_epblRequest: 8 UDS
 SG_ UDS_epblRequestData_H : 7|32@0+ (1,0) [0|4294967295] "" Vector__XXX
 SG_ UDS_epblRequestData_L : 39|32@0+ (1,0) [0|4294967295] "" Vector__XXX

BO_ 1574 UDS_epbrRequest: 8 UDS
 SG_ UDS_epbrRequestData_H : 7|32@0+ (1,0) [0|4294967295] "" Vector__XXX
 SG_ UDS_epbrRequestData_L : 39|32@0+ (1,0) [0|4294967295] "" Vector__XXX

BO_ 1605 UDS_espRequest: 8 UDS
 SG_ UDS_espRequestData : 7|64@0+ (1,0) [0|1.84467440737e+19] "" Vector__XXX

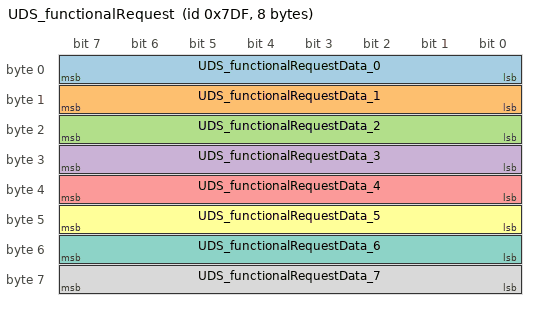
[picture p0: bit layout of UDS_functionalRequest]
BO_ 2015 UDS_functionalRequest: 8 UDS
 SG_ UDS_functionalRequestData_0 : 7|8@0+ (1,0) [0|255] "" Vector__XXX
 SG_ UDS_functionalRequestData_1 : 15|8@0+ (1,0) [0|255] "" Vector__XXX
 SG_ UDS_functionalRequestData_2 : 23|8@0+ (1,0) [0|255] "" Vector__XXX
 SG_ UDS_functionalRequestData_3 : 31|8@0+ (1,0) [0|255] "" Vector__XXX
 SG_ UDS_functionalRequestData_4 : 39|8@0+ (1,0) [0|255] "" Vector__XXX
 SG_ UDS_functionalRequestData_5 : 47|8@0+ (1,0) [0|255] "" Vector__XXX
 SG_ UDS_functionalRequestData_6 : 55|8@0+ (1,0) [0|255] "" Vector__XXX
 SG_ UDS_functionalRequestData_7 : 63|8@0+ (1,0) [0|255] "" Vector__XXX

BO_ 2014 UDS_functionalRequest_CH: 8 UDS
 SG_ UDS_functionalRequestDataCH : 7|64@0+ (1,0) [0|1.84467440737e+19] "" Vector__XXX

BO_ 1552 UDS_hvpRequest: 8 UDS
 SG_ UDS_hvpRequestData : 7|64@0+ (1,0) [0|1.84467440737e+19] "" Vector__XXX

BO_ 1613 UDS_ibstRequest: 8 UDS
 SG_ UDS_ibstRequestData : 7|64@0+ (1,0) [0|1.84467440737e+19] "" Vector__XXX

BO_ 1560 UDS_icrRequest: 8 UDS
 SG_ UDS_icrRequestData : 7|64@0+ (1,0) [0|1.84467440737e+19] "" Vector__XXX

BO_ 1603 UDS_ocs1pRequest: 8 UDS
 SG_ UDS_ocs1pRequestData : 7|64@0+ (1,0) [0|1.84467440737e+19] "" Vector__XXX

BO_ 1614 UDS_parkRequest: 8 UDS
 SG_ UDS_parkRequestData : 7|64@0+ (1,0) [0|1.84467440737e+19] "" Vector__XXX

BO_ 1576 UDS_pcsRequest: 8 UDS
 SG_ UDS_pcsRequestData : 7|64@0+ (1,0) [0|1.84467440737e+19] "" Vector__XXX

BO_ 1634 UDS_plgRequest: 8 UDS
 SG_ UDS_plgRequestData : 7|64@0+ (1,0) [0|1.84467440737e+19] "" Vector__XXX

BO_ 1568 UDS_pmRequest: 8 UDS
 SG_ UDS_pmRequestData : 7|64@0+ (1,0) [0|1.84467440737e+19] "" Vector__XXX

BO_ 1604 UDS_pmfRequest: 8 UDS
 SG_ UDS_pmfRequestData : 7|64@0+ (1,0) [0|1.84467440737e+19] "" Vector__XXX

BO_ 1540 UDS_pmrRequest: 8 UDS
 SG_ UDS_pmrRequestData : 7|64@0+ (1,0) [0|1.84467440737e+19] "" Vector__XXX

BO_ 1734 UDS_ptcRequest: 8 UDS
 SG_ UDS_ptcRequestData : 7|64@0+ (1,0) [0|1.84467440737e+19] "" Vector__XXX

BO_ 1649 UDS_radcRequest: 8 UDS
 SG_ UDS_radcRequestData : 7|64@0+ (1,0) [0|1.84467440737e+19] "" Vector__XXX

BO_ 1601 UDS_rcmRequest: 8 UDS
 SG_ UDS_rcmRequestData : 7|64@0+ (1,0) [0|1.84467440737e+19] "" Vector__XXX

BO_ 1664 UDS_sccmRequest: 8 UDS
 SG_ UDS_sccmRequestData : 7|64@0+ (1,0) [0|1.84467440737e+19] "" Vector__XXX

BO_ 1723 UDS_sdcrRequest: 8 UDS
 SG_ UDS_sdcrRequestData : 7|64@0+ (1,0) [0|1.84467440737e+19] "" Vector__XXX

BO_ 1611 UDS_tasRequest: 8 UDS
 SG_ UDS_tasRequestData : 7|64@0+ (1,0) [0|1.84467440737e+19] "" Vector__XXX

BO_ 1551 UDS_thcRequest: 8 UDS
 SG_ UDS_thcRequestData_H : 7|32@0+ (1,0) [0|4294967295] "" Vector__XXX
 SG_ UDS_thcRequestData_L : 39|32@0+ (1,0) [0|4294967295] "" Vector__XXX

BO_ 1615 UDS_tpmsRequest: 8 UDS
 SG_ UDS_tpmsRequestData : 7|64@0+ (1,0) [0|1.84467440737e+19] "" Vector__XXX

BO_ 1578 UDS_vcbatt1Request: 8 UDS
 SG_ UDS_vcbatt1RequestData : 7|64@0+ (1,0) [0|1.84467440737e+19] "" Vector__XXX

BO_ 1588 UDS_vcbatt2Request: 8 UDS
 SG_ UDS_vcbatt2RequestData : 7|64@0+ (1,0) [0|1.84467440737e+19] "" Vector__XXX

BO_ 1636 UDS_vcbattRequest: 8 UDS
 SG_ UDS_vcbattRequestData : 7|64@0+ (1,0) [0|1.84467440737e+19] "" Vector__XXX

BO_ 1580 UDS_vcfront1Request: 8 UDS
 SG_ UDS_vcfront1RequestData : 7|64@0+ (1,0) [0|1.84467440737e+19] "" Vector__XXX

BO_ 1582 UDS_vcfront2Request: 8 UDS
 SG_ UDS_vcfront2RequestData : 7|64@0+ (1,0) [0|1.84467440737e+19] "" Vector__XXX

BO_ 1536 UDS_vcfrontRequest: 8 UDS
 SG_ UDS_vcfrontRequestData : 7|64@0+ (1,0) [0|1.84467440737e+19] "" Vector__XXX

BO_ 1570 UDS_vcleftRequest: 8 UDS
 SG_ UDS_vcleftRequestData_H : 7|32@0+ (1,0) [0|4294967295] "" Vector__XXX
 SG_ UDS_vcleftRequestData_L : 39|32@0+ (1,0) [0|4294967295] "" Vector__XXX

BO_ 1544 UDS_vcrightRequest: 8 UDS
 SG_ UDS_vcrightRequestData_H : 7|32@0+ (1,0) [0|4294967295] "" Vector__XXX
 SG_ UDS_vcrightRequestData_L : 39|32@0+ (1,0) [0|4294967295] "" Vector__XXX

BO_ 1546 UDS_vcsecRequest: 8 UDS
 SG_ UDS_vcsecRequestData : 7|64@0+ (1,0) [0|1.84467440737e+19] "" Vector__XXX

BO_TX_BU_ 2030 : TRCM;
BO_TX_BU_ 1641 : UDS;
BO_TX_BU_ 1538 : UDS;
BO_TX_BU_ 1579 : UDS;
BO_TX_BU_ 1539 : UDS;
BO_TX_BU_ 1543 : UDS;
BO_TX_BU_ 1550 : UDS;
BO_TX_BU_ 1609 : UDS;
BO_TX_BU_ 1589 : UDS;
BO_TX_BU_ 1541 : UDS;
BO_TX_BU_ 1542 : UDS;
BO_TX_BU_ 1584 : UDS;
BO_TX_BU_ 1840 : UDS;
BO_TX_BU_ 1572 : UDS;
BO_TX_BU_ 1574 : UDS;
BO_TX_BU_ 1605 : UDS;
BO_TX_BU_ 2015 : UDS;
BO_TX_BU_ 2014 : UDS;
BO_TX_BU_ 1552 : UDS;
BO_TX_BU_ 1613 : UDS;
BO_TX_BU_ 1560 : UDS;
BO_TX_BU_ 1603 : UDS;
BO_TX_BU_ 1614 : UDS;
BO_TX_BU_ 1576 : UDS;
BO_TX_BU_ 1634 : UDS;
BO_TX_BU_ 1568 : UDS;
BO_TX_BU_ 1604 : UDS;
BO_TX_BU_ 1540 : UDS;
BO_TX_BU_ 1734 : UDS;
BO_TX_BU_ 1649 : UDS;
BO_TX_BU_ 1601 : UDS;
BO_TX_BU_ 1664 : UDS;
BO_TX_BU_ 1723 : UDS;
BO_TX_BU_ 1611 : UDS;
BO_TX_BU_ 1551 : UDS;
BO_TX_BU_ 1615 : UDS;
BO_TX_BU_ 1578 : UDS;
BO_TX_BU_ 1588 : UDS;
BO_TX_BU_ 1636 : UDS;
BO_TX_BU_ 1580 : UDS;
BO_TX_BU_ 1582 : UDS;
BO_TX_BU_ 1536 : UDS;
BO_TX_BU_ 1570 : UDS;
BO_TX_BU_ 1544 : UDS;
BO_TX_BU_ 1546 : UDS;
CM_ BO_ 2030 "TRCM ECU message: alert matrix";
CM_ SG_ 2030 TRCM_matrixIndex "TRCM ECU: matrix index";
CM_ SG_ 2030 TRCM_a003_SWAssertion "TRCM ECU: a003 SW assertion";
CM_ SG_ 2030 TRCM_a005_CANTXError "TRCM ECU: a005 CANTX error";
CM_ SG_ 2030 TRCM_a006_CANTX_cyclicError "TRCM ECU: a006 CANTX cyclic error";
CM_ SG_ 2030 TRCM_a007_chassisChecksumError "TRCM ECU: a007 chassis checksum error";
CM_ SG_ 2030 TRCM_a008_chassisCounterError "TRCM ECU: a008 chassis counter error";
CM_ SG_ 2030 TRCM_a009_partyChecksumError "TRCM ECU: a009 party checksum error";
CM_ SG_ 2030 TRCM_a010_partyCounterError "TRCM ECU: a010 party counter error";
CM_ SG_ 2030 TRCM_a012_asm5TemperatureOutside "TRCM ECU: a012 asm5 temperature outside signal range";
CM_ SG_ 2030 TRCM_a013_AlertManagerFault "TRCM ECU: a013 alert manager fault";
CM_ SG_ 2030 TRCM_a014_asm3TemperatureOutside "TRCM ECU: a014 asm3 temperature outside signal range";
CM_ SG_ 2030 TRCM_a015_NVMMError "TRCM ECU: a015 NVMM error";
CM_ SG_ 2030 TRCM_a016_NVMMRecordError "TRCM ECU: a016 NVMM record error";
CM_ SG_ 2030 TRCM_a017_asm5TemperatureOutside "TRCM ECU: a017 asm5 temperature outside operating range";
CM_ SG_ 2030 TRCM_a018_asm3TemperatureOutside "TRCM ECU: a018 asm3 temperature outside operating range";
CM_ SG_ 2030 TRCM_a019_Task500usError "TRCM ECU: a019 task500us error";
CM_ SG_ 2030 TRCM_a020_asm3ComStatusError "TRCM ECU: a020 asm3 com status error";
CM_ SG_ 2030 TRCM_a021_TaskSchedulerError "TRCM ECU: a021 task scheduler error";
CM_ SG_ 2030 TRCM_a022_TaskInitError "TRCM ECU: a022 task init error";
CM_ SG_ 2030 TRCM_a023_asm3ArsStatusXError "TRCM ECU: a023 asm3 ars status x error";
CM_ SG_ 2030 TRCM_a024_asm3AccStatusError "TRCM ECU: a024 asm3 acc status error";
CM_ SG_ 2030 TRCM_a025_CHCANBusFaults "TRCM ECU: a025 CHCAN bus faults";
CM_ SG_ 2030 TRCM_a026_airbagAsicDiagnosticFa "TRCM ECU: a026 airbag asic diagnostic fault";
CM_ SG_ 2030 TRCM_a027_airbagAsicDeploymentDi "TRCM ECU: a027 airbag asic deployment diagnostic fault";
CM_ SG_ 2030 TRCM_a030_ECULogUploadRequest "TRCM ECU: a030 ECU log upload request";
CM_ SG_ 2030 TRCM_a031_UDSActive "TRCM ECU: a031 UDS active";
CM_ SG_ 2030 TRCM_a033_HercLogCreated "TRCM ECU: a033 herc log created";
CM_ SG_ 2030 TRCM_a034_apClipTrigger "TRCM ECU: a034 ap clip trigger";
CM_ SG_ 2030 TRCM_a035_hvDisconnectCommanded "TRCM ECU: a035 hv disconnect commanded";
CM_ SG_ 2030 TRCM_a041_HighCPULoad "TRCM ECU: a041 high CPU load";
CM_ SG_ 2030 TRCM_a042_HighStackUsage "TRCM ECU: a042 high stack usage";
CM_ SG_ 2030 TRCM_a043_Task1msError "TRCM ECU: a043 task1ms error";
CM_ SG_ 2030 TRCM_a044_Task10msError "TRCM ECU: a044 task10ms error";
CM_ SG_ 2030 TRCM_a045_Task100msError "TRCM ECU: a045 task100ms error";
CM_ SG_ 2030 TRCM_a046_Task1000msError "TRCM ECU: a046 task1000ms error";
CM_ SG_ 2030 TRCM_a057_HVP_MIA "TRCM ECU: a057 HVP MIA";
CM_ SG_ 2030 TRCM_a058_inputRHighSyncDebug "TRCM ECU: a058 input r high sync debug";
CM_ SG_ 2030 TRCM_a059_inputResistanceHigh "TRCM ECU: a059 input resistance high";
CM_ SG_ 2030 TRCM_a060_engineeringBuild "TRCM ECU: a060 engineering build";
CM_ SG_ 2030 TRCM_a061_XCPConnected "TRCM ECU: a061 XCP connected";
CM_ SG_ 2030 TRCM_a062_XCPWasConnected "TRCM ECU: a062 XCP was connected";
CM_ SG_ 2030 TRCM_a063_SwitchFault "TRCM ECU: a063 switch fault";
CM_ SG_ 2030 TRCM_a064_busSleepReqTimeout "TRCM ECU: a064 bus sleep req timeout";
CM_ SG_ 2030 TRCM_a065_vSafingFetUnderVoltage "TRCM ECU: a065 v safing fet under voltage";
CM_ SG_ 2030 TRCM_a066_vBusAUnderVoltage "TRCM ECU: a066 v bus a under voltage";
CM_ SG_ 2030 TRCM_a067_vBusBUnderVoltage "TRCM ECU: a067 v bus b under voltage";
CM_ SG_ 2030 TRCM_a068_vBusCUnderVoltage "TRCM ECU: a068 v bus c under voltage";
CM_ SG_ 2030 TRCM_a069_swAppBoot "TRCM ECU: a069 sw app boot";
CM_ SG_ 2030 TRCM_a070_asm3StatusError "TRCM ECU: a070 asm3 status error";
CM_ SG_ 2030 TRCM_a071_asm3DeviceFaulted "TRCM ECU: a071 asm3 device faulted";
CM_ SG_ 2030 TRCM_a072_ais2120StatusError "TRCM ECU: a072 ais2120 status error";
CM_ SG_ 2030 TRCM_a073_ais2120DeviceFaulted "TRCM ECU: a073 ais2120 device faulted";
CM_ SG_ 2030 TRCM_a074_ais2120SelfTestXPositi "TRCM ECU: a074 ais2120 self test x positive failed";
CM_ SG_ 2030 TRCM_a075_ais2120SelfTestXNegati "TRCM ECU: a075 ais2120 self test x negative failed";
CM_ SG_ 2030 TRCM_a076_ais2120SelfTestYPositi "TRCM ECU: a076 ais2120 self test y positive failed";
CM_ SG_ 2030 TRCM_a077_ais2120SelfTestYNegati "TRCM ECU: a077 ais2120 self test y negative failed";
CM_ SG_ 2030 TRCM_a081_autarkyActive "TRCM ECU: a081 autarky active";
CM_ SG_ 2030 TRCM_a082_VCRIGHT_IPC_MIA "TRCM ECU: a082 VCRIGHT IPC MIA";
CM_ SG_ 2030 TRCM_a083_VCLEFT_IPC_MIA "TRCM ECU: a083 VCLEFT IPC MIA";
CM_ SG_ 2030 TRCM_a084_TPMS_MIA "TRCM ECU: a084 TPMS MIA";
CM_ SG_ 2030 TRCM_a085_CCCM_MIA "TRCM ECU: a085 CCCM MIA";
CM_ SG_ 2030 TRCM_a086_VCBATT_MIA "TRCM ECU: a086 VCBATT MIA";
CM_ SG_ 2030 TRCM_a087_DIREL_MIA "TRCM ECU: a087 DIREL MIA";
CM_ SG_ 2030 TRCM_a088_DIRER_MIA "TRCM ECU: a088 DIRER MIA";
CM_ SG_ 2030 TRCM_a089_IBST_MIA "TRCM ECU: a089 IBST MIA";
CM_ SG_ 2030 TRCM_a090_APS_MIA "TRCM ECU: a090 APS MIA";
CM_ SG_ 2030 TRCM_a091_CMPD_MIA "TRCM ECU: a091 CMPD MIA";
CM_ SG_ 2030 TRCM_a092_VCSEATD_MIA "TRCM ECU: a092 VCSEATD MIA";
CM_ SG_ 2030 TRCM_a093_VCSEATP_MIA "TRCM ECU: a093 VCSEATP MIA";
CM_ SG_ 2030 TRCM_a094_EPAS3P_MIA "TRCM ECU: a094 EPAS3 p MIA";
CM_ SG_ 2030 TRCM_a095_CHG_MIA "TRCM ECU: a095 CHG MIA";
CM_ SG_ 2030 TRCM_a096_OCS1P_MIA "TRCM ECU: a096 OCS1 p MIA";
CM_ SG_ 2030 TRCM_a097_CMP_MIA "TRCM ECU: a097 CMP MIA";
CM_ SG_ 2030 TRCM_a098_DIR_MIA "TRCM ECU: a098 DIR MIA";
CM_ SG_ 2030 TRCM_a099_PARK_MIA "TRCM ECU: a099 PARK MIA";
CM_ SG_ 2030 TRCM_a100_CANbus_MIA "TRCM ECU: a100 CA nbus MIA";
CM_ SG_ 2030 TRCM_a101_PM_MIA "TRCM ECU: a101 PM MIA";
CM_ SG_ 2030 TRCM_a102_PTC_MIA "TRCM ECU: a102 PTC MIA";
CM_ SG_ 2030 TRCM_a103_CP_MIA "TRCM ECU: a103 CP MIA";
CM_ SG_ 2030 TRCM_a104_DAS_MIA "TRCM ECU: a104 DAS MIA";
CM_ SG_ 2030 TRCM_a105_TAS_MIA "TRCM ECU: a105 TAS MIA";
CM_ SG_ 2030 TRCM_a106_PCS_MIA "TRCM ECU: a106 PCS MIA";
CM_ SG_ 2030 TRCM_a107_BMS_MIA "TRCM ECU: a107 BMS MIA";
CM_ SG_ 2030 TRCM_a108_DIF_MIA "TRCM ECU: a108 DIF MIA";
CM_ SG_ 2030 TRCM_a109_RCM_MIA "TRCM ECU: a109 RCM MIA";
CM_ SG_ 2030 TRCM_a110_GTW_MIA "TRCM ECU: a110 GTW MIA";
CM_ SG_ 2030 TRCM_a111_EPBR_MIA "TRCM ECU: a111 EPBR MIA";
CM_ SG_ 2030 TRCM_a112_EPBL_MIA "TRCM ECU: a112 EPBL MIA";
CM_ SG_ 2030 TRCM_a113_UI_MIA "TRCM ECU: a113 UI MIA";
CM_ SG_ 2030 TRCM_a114_ESP_MIA "TRCM ECU: a114 ESP MIA";
CM_ SG_ 2030 TRCM_a115_VCSEC_MIA "TRCM ECU: a115 VCSEC MIA";
CM_ SG_ 2030 TRCM_a116_VCRIGHT_MIA "TRCM ECU: a116 VCRIGHT MIA";
CM_ SG_ 2030 TRCM_a117_VCLEFT_MIA "TRCM ECU: a117 VCLEFT MIA";
CM_ SG_ 2030 TRCM_a118_VCFRONT_MIA "TRCM ECU: a118 VCFRONT MIA";
CM_ SG_ 2030 TRCM_a119_SCCM_MIA "TRCM ECU: a119 SCCM MIA";
CM_ SG_ 2030 TRCM_a120_DI_DRIVE_MIA "TRCM ECU: a120 DI DRIVE MIA";
CM_ SG_ 2030 TRCM_a121_glacierInitialStatusFa "TRCM ECU: a121 glacier initial status failure";
CM_ SG_ 2030 TRCM_a122_glacierTraceabilityRea "TRCM ECU: a122 glacier traceability readout A0 A0 failure";
CM_ SG_ 2030 TRCM_a123_glacierTraceabilityRea "TRCM ECU: a123 glacier traceability readout B0 B0 failure";
CM_ SG_ 2030 TRCM_a124_glacierRegisterPattern "TRCM ECU: a124 glacier register pattern write failure";
CM_ SG_ 2030 TRCM_a125_glacierFixedPatternSel "TRCM ECU: a125 glacier fixed pattern self test failure";
CM_ SG_ 2030 TRCM_a126_glacierSelfTestEFailur "TRCM ECU: a126 glacier self test e failure";
CM_ SG_ 2030 TRCM_a127_glacierSelfTestFFailur "TRCM ECU: a127 glacier self test f failure";
CM_ SG_ 2030 TRCM_a128_glacierAnalogSelfTestF "TRCM ECU: a128 glacier analog self test failure";
CM_ SG_ 2030 TRCM_a129_glacierOscillatorVerif "TRCM ECU: a129 glacier oscillator verification failure";
CM_ SG_ 2030 TRCM_a130_glacierFinalStatusFail "TRCM ECU: a130 glacier final status failure";
CM_ SG_ 2030 TRCM_a131_glacierOffsetVerificat "TRCM ECU: a131 glacier offset verification failure";
CM_ SG_ 2030 TRCM_a132_glacierNormalOperation "TRCM ECU: a132 glacier normal operation failure";
CM_ SG_ 2030 TRCM_a133_glacierDeviceReset "TRCM ECU: a133 glacier device reset";
CM_ SG_ 2030 TRCM_a134_glacierDeviceFaulted "TRCM ECU: a134 glacier device faulted";
CM_ SG_ 2030 TRCM_a135_asm5StatusError "TRCM ECU: a135 asm5 status error";
CM_ SG_ 2030 TRCM_a136_asm5DeviceFaulted "TRCM ECU: a136 asm5 device faulted";
CM_ SG_ 2030 TRCM_a137_ext1AsicSnoopTestFaile "TRCM ECU: a137 ext1 asic snoop test failed";
CM_ SG_ 2030 TRCM_a138_ext2AsicSnoopTestFaile "TRCM ECU: a138 ext2 asic snoop test failed";
CM_ SG_ 2030 TRCM_a139_disarmed "TRCM ECU: a139 disarmed";
CM_ SG_ 2030 TRCM_a140_frontRightAccelInitFai "TRCM ECU: a140 front right accel init failure";
CM_ SG_ 2030 TRCM_a141_frontRightAccelShortTo "TRCM ECU: a141 front right accel short to ground";
CM_ SG_ 2030 TRCM_a142_frontRightAccelShortTo "TRCM ECU: a142 front right accel short to battery";
CM_ SG_ 2030 TRCM_a143_frontRightAccelConfigE "TRCM ECU: a143 front right accel config error";
CM_ SG_ 2030 TRCM_a144_frontRightAccelOpen "TRCM ECU: a144 front right accel open";
CM_ SG_ 2030 TRCM_a145_frontRightAccelCommErr "TRCM ECU: a145 front right accel comm error";
CM_ SG_ 2030 TRCM_a146_frontRightAccelSensorD "TRCM ECU: a146 front right accel sensor defect";
CM_ SG_ 2030 TRCM_a147_frontRightAccelSignalM "TRCM ECU: a147 front right accel signal monitor";
CM_ SG_ 2030 TRCM_a150_rightFrontDoorPressure "TRCM ECU: a150 right front door pressure init failure";
CM_ SG_ 2030 TRCM_a151_rightFrontDoorPressure "TRCM ECU: a151 right front door pressure short to ground";
CM_ SG_ 2030 TRCM_a152_rightFrontDoorPressure "TRCM ECU: a152 right front door pressure short to battery";
CM_ SG_ 2030 TRCM_a153_rightFrontDoorPressure "TRCM ECU: a153 right front door pressure config error";
CM_ SG_ 2030 TRCM_a154_rightFrontDoorPressure "TRCM ECU: a154 right front door pressure open";
CM_ SG_ 2030 TRCM_a155_rightFrontDoorPressure "TRCM ECU: a155 right front door pressure comm error";
CM_ SG_ 2030 TRCM_a156_rightFrontDoorPressure "TRCM ECU: a156 right front door pressure sensor defect";
CM_ SG_ 2030 TRCM_a157_rightFrontDoorPressure "TRCM ECU: a157 right front door pressure signal monitor";
CM_ SG_ 2030 TRCM_a160_frontLeftAccelInitFail "TRCM ECU: a160 front left accel init failure";
CM_ SG_ 2030 TRCM_a161_frontLeftAccelShortToG "TRCM ECU: a161 front left accel short to ground";
CM_ SG_ 2030 TRCM_a162_frontLeftAccelShortToB "TRCM ECU: a162 front left accel short to battery";
CM_ SG_ 2030 TRCM_a163_frontLeftAccelConfigEr "TRCM ECU: a163 front left accel config error";
CM_ SG_ 2030 TRCM_a164_frontLeftAccelOpen "TRCM ECU: a164 front left accel open";
CM_ SG_ 2030 TRCM_a165_frontLeftAccelCommErro "TRCM ECU: a165 front left accel comm error";
CM_ SG_ 2030 TRCM_a166_frontLeftAccelSensorDe "TRCM ECU: a166 front left accel sensor defect";
CM_ SG_ 2030 TRCM_a167_frontLeftAccelSignalMo "TRCM ECU: a167 front left accel signal monitor";
CM_ SG_ 2030 TRCM_a170_leftFrontDoorPressureI "TRCM ECU: a170 left front door pressure init failure";
CM_ SG_ 2030 TRCM_a171_leftFrontDoorPressureS "TRCM ECU: a171 left front door pressure short to ground";
CM_ SG_ 2030 TRCM_a172_leftFrontDoorPressureS "TRCM ECU: a172 left front door pressure short to battery";
CM_ SG_ 2030 TRCM_a173_leftFrontDoorPressureC "TRCM ECU: a173 left front door pressure config error";
CM_ SG_ 2030 TRCM_a174_leftFrontDoorPressureO "TRCM ECU: a174 left front door pressure open";
CM_ SG_ 2030 TRCM_a175_leftFrontDoorPressureC "TRCM ECU: a175 left front door pressure comm error";
CM_ SG_ 2030 TRCM_a176_leftFrontDoorPressureS "TRCM ECU: a176 left front door pressure sensor defect";
CM_ SG_ 2030 TRCM_a177_leftFrontDoorPressureS "TRCM ECU: a177 left front door pressure signal monitor";
CM_ SG_ 2030 TRCM_a180_rightBPillarAccelInitF "TRCM ECU: a180 right b pillar accel init failure";
CM_ SG_ 2030 TRCM_a181_rightBPillarAccelShort "TRCM ECU: a181 right b pillar accel short to ground";
CM_ SG_ 2030 TRCM_a182_rightBPillarAccelShort "TRCM ECU: a182 right b pillar accel short to battery";
CM_ SG_ 2030 TRCM_a183_rightBPillarAccelConfi "TRCM ECU: a183 right b pillar accel config error";
CM_ SG_ 2030 TRCM_a184_rightBPillarAccelOpen "TRCM ECU: a184 right b pillar accel open";
CM_ SG_ 2030 TRCM_a185_rightBPillarAccelCommE "TRCM ECU: a185 right b pillar accel comm error";
CM_ SG_ 2030 TRCM_a186_rightBPillarAccelSenso "TRCM ECU: a186 right b pillar accel sensor defect";
CM_ SG_ 2030 TRCM_a187_rightBPillarAccelSigna "TRCM ECU: a187 right b pillar accel signal monitor";
CM_ SG_ 2030 TRCM_a190_leftBPillarAccelInitFa "TRCM ECU: a190 left b pillar accel init failure";
CM_ SG_ 2030 TRCM_a191_leftBPillarAccelShortT "TRCM ECU: a191 left b pillar accel short to ground";
CM_ SG_ 2030 TRCM_a192_leftBPillarAccelShortT "TRCM ECU: a192 left b pillar accel short to battery";
CM_ SG_ 2030 TRCM_a193_leftBPillarAccelConfig "TRCM ECU: a193 left b pillar accel config error";
CM_ SG_ 2030 TRCM_a194_leftBPillarAccelOpen "TRCM ECU: a194 left b pillar accel open";
CM_ SG_ 2030 TRCM_a195_leftBPillarAccelCommEr "TRCM ECU: a195 left b pillar accel comm error";
CM_ SG_ 2030 TRCM_a196_leftBPillarAccelSensor "TRCM ECU: a196 left b pillar accel sensor defect";
CM_ SG_ 2030 TRCM_a197_leftBPillarAccelSignal "TRCM ECU: a197 left b pillar accel signal monitor";
CM_ SG_ 2030 TRCM_a200_frontCenterAccelInitFa "TRCM ECU: a200 front center accel init failure";
CM_ SG_ 2030 TRCM_a201_frontCenterAccelShortT "TRCM ECU: a201 front center accel short to ground";
CM_ SG_ 2030 TRCM_a202_frontCenterAccelShortT "TRCM ECU: a202 front center accel short to battery";
CM_ SG_ 2030 TRCM_a203_frontCenterAccelConfig "TRCM ECU: a203 front center accel config error";
CM_ SG_ 2030 TRCM_a204_frontCenterAccelOpen "TRCM ECU: a204 front center accel open";
CM_ SG_ 2030 TRCM_a205_frontCenterAccelCommEr "TRCM ECU: a205 front center accel comm error";
CM_ SG_ 2030 TRCM_a206_frontCenterAccelSensor "TRCM ECU: a206 front center accel sensor defect";
CM_ SG_ 2030 TRCM_a207_frontCenterAccelSignal "TRCM ECU: a207 front center accel signal monitor";
CM_ SG_ 2030 TRCM_a210_leftCPillarAccelInitFa "TRCM ECU: a210 left c pillar accel init failure";
CM_ SG_ 2030 TRCM_a211_leftCPillarAccelShortT "TRCM ECU: a211 left c pillar accel short to ground";
CM_ SG_ 2030 TRCM_a212_leftCPillarAccelShortT "TRCM ECU: a212 left c pillar accel short to battery";
CM_ SG_ 2030 TRCM_a213_leftCPillarAccelConfig "TRCM ECU: a213 left c pillar accel config error";
CM_ SG_ 2030 TRCM_a214_leftCPillarAccelOpen "TRCM ECU: a214 left c pillar accel open";
CM_ SG_ 2030 TRCM_a215_leftCPillarAccelCommEr "TRCM ECU: a215 left c pillar accel comm error";
CM_ SG_ 2030 TRCM_a216_leftCPillarAccelSensor "TRCM ECU: a216 left c pillar accel sensor defect";
CM_ SG_ 2030 TRCM_a217_leftCPillarAccelSignal "TRCM ECU: a217 left c pillar accel signal monitor";
CM_ SG_ 2030 TRCM_a220_rightCPillarAccelInitF "TRCM ECU: a220 right c pillar accel init failure";
CM_ SG_ 2030 TRCM_a221_rightCPillarAccelShort "TRCM ECU: a221 right c pillar accel short to ground";
CM_ SG_ 2030 TRCM_a222_rightCPillarAccelShort "TRCM ECU: a222 right c pillar accel short to battery";
CM_ SG_ 2030 TRCM_a223_rightCPillarAccelConfi "TRCM ECU: a223 right c pillar accel config error";
CM_ SG_ 2030 TRCM_a224_rightCPillarAccelOpen "TRCM ECU: a224 right c pillar accel open";
CM_ SG_ 2030 TRCM_a225_rightCPillarAccelCommE "TRCM ECU: a225 right c pillar accel comm error";
CM_ SG_ 2030 TRCM_a226_rightCPillarAccelSenso "TRCM ECU: a226 right c pillar accel sensor defect";
CM_ SG_ 2030 TRCM_a227_rightCPillarAccelSigna "TRCM ECU: a227 right c pillar accel signal monitor";
CM_ SG_ 2030 TRCM_a230_leftRearDoorPressureIn "TRCM ECU: a230 left rear door pressure init failure";
CM_ SG_ 2030 TRCM_a231_leftRearDoorPressureSh "TRCM ECU: a231 left rear door pressure short to ground";
CM_ SG_ 2030 TRCM_a232_leftRearDoorPressureSh "TRCM ECU: a232 left rear door pressure short to battery";
CM_ SG_ 2030 TRCM_a233_leftRearDoorPressureCo "TRCM ECU: a233 left rear door pressure config error";
CM_ SG_ 2030 TRCM_a234_leftRearDoorPressureOp "TRCM ECU: a234 left rear door pressure open";
CM_ SG_ 2030 TRCM_a235_leftRearDoorPressureCo "TRCM ECU: a235 left rear door pressure comm error";
CM_ SG_ 2030 TRCM_a236_leftRearDoorPressureSe "TRCM ECU: a236 left rear door pressure sensor defect";
CM_ SG_ 2030 TRCM_a237_leftRearDoorPressureSi "TRCM ECU: a237 left rear door pressure signal monitor";
CM_ SG_ 2030 TRCM_a240_rightRearDoorPressureI "TRCM ECU: a240 right rear door pressure init failure";
CM_ SG_ 2030 TRCM_a241_rightRearDoorPressureS "TRCM ECU: a241 right rear door pressure short to ground";
CM_ SG_ 2030 TRCM_a242_rightRearDoorPressureS "TRCM ECU: a242 right rear door pressure short to battery";
CM_ SG_ 2030 TRCM_a243_rightRearDoorPressureC "TRCM ECU: a243 right rear door pressure config error";
CM_ SG_ 2030 TRCM_a244_rightRearDoorPressureO "TRCM ECU: a244 right rear door pressure open";
CM_ SG_ 2030 TRCM_a245_rightRearDoorPressureC "TRCM ECU: a245 right rear door pressure comm error";
CM_ SG_ 2030 TRCM_a246_rightRearDoorPressureS "TRCM ECU: a246 right rear door pressure sensor defect";
CM_ SG_ 2030 TRCM_a247_rightRearDoorPressureS "TRCM ECU: a247 right rear door pressure signal monitor";
CM_ SG_ 2030 TRCM_a250_frontCenterAccelXInitF "TRCM ECU: a250 front center accel x init failure";
CM_ SG_ 2030 TRCM_a251_frontCenterAccelXShort "TRCM ECU: a251 front center accel x short to ground";
CM_ SG_ 2030 TRCM_a252_frontCenterAccelXShort "TRCM ECU: a252 front center accel x short to battery";
CM_ SG_ 2030 TRCM_a253_frontCenterAccelXConfi "TRCM ECU: a253 front center accel x config error";
CM_ SG_ 2030 TRCM_a254_frontCenterAccelXOpen "TRCM ECU: a254 front center accel x open";
CM_ SG_ 2030 TRCM_a255_frontCenterAccelXCommE "TRCM ECU: a255 front center accel x comm error";
CM_ SG_ 2030 TRCM_a256_frontCenterAccelXSenso "TRCM ECU: a256 front center accel x sensor defect";
CM_ SG_ 2030 TRCM_a257_frontCenterAccelXSigna "TRCM ECU: a257 front center accel x signal monitor";
CM_ SG_ 2030 TRCM_a260_frontCenterAccelYInitF "TRCM ECU: a260 front center accel y init failure";
CM_ SG_ 2030 TRCM_a261_frontCenterAccelYShort "TRCM ECU: a261 front center accel y short to ground";
CM_ SG_ 2030 TRCM_a262_frontCenterAccelYShort "TRCM ECU: a262 front center accel y short to battery";
CM_ SG_ 2030 TRCM_a263_frontCenterAccelYConfi "TRCM ECU: a263 front center accel y config error";
CM_ SG_ 2030 TRCM_a264_frontCenterAccelYOpen "TRCM ECU: a264 front center accel y open";
CM_ SG_ 2030 TRCM_a265_frontCenterAccelYCommE "TRCM ECU: a265 front center accel y comm error";
CM_ SG_ 2030 TRCM_a266_frontCenterAccelYSenso "TRCM ECU: a266 front center accel y sensor defect";
CM_ SG_ 2030 TRCM_a267_frontCenterAccelYSigna "TRCM ECU: a267 front center accel y signal monitor";
CM_ SG_ 2030 TRCM_a272_asm5ComStatusError "TRCM ECU: a272 asm5 com status error";
CM_ SG_ 2030 TRCM_a273_asm5ArsStatusXError "TRCM ECU: a273 asm5 ars status x error";
CM_ SG_ 2030 TRCM_a274_asm5ArsStatusZError "TRCM ECU: a274 asm5 ars status z error";
CM_ SG_ 2030 TRCM_a275_asm5AccStatusError "TRCM ECU: a275 asm5 acc status error";
CM_ SG_ 2030 TRCM_a276_watchdogStatus "TRCM ECU: a276 watchdog status";
CM_ SG_ 2030 TRCM_a278_safingEngine0Armed "TRCM ECU: a278 safing engine0 armed";
CM_ SG_ 2030 TRCM_a279_safingEngine1Armed "TRCM ECU: a279 safing engine1 armed";
CM_ SG_ 2030 TRCM_a280_safingEngine2Armed "TRCM ECU: a280 safing engine2 armed";
CM_ SG_ 2030 TRCM_a281_safingEngine3Armed "TRCM ECU: a281 safing engine3 armed";
CM_ SG_ 2030 TRCM_a282_safingEngine4Armed "TRCM ECU: a282 safing engine4 armed";
CM_ SG_ 2030 TRCM_a283_safingEngine5Armed "TRCM ECU: a283 safing engine5 armed";
CM_ SG_ 2030 TRCM_a284_safingEngine6Armed "TRCM ECU: a284 safing engine6 armed";
CM_ SG_ 2030 TRCM_a285_safingEngine7Armed "TRCM ECU: a285 safing engine7 armed";
CM_ SG_ 2030 TRCM_a286_safingEngine8Armed "TRCM ECU: a286 safing engine8 armed";
CM_ SG_ 2030 TRCM_a287_safingEngine9Armed "TRCM ECU: a287 safing engine9 armed";
CM_ SG_ 2030 TRCM_a288_safingEngine10Armed "TRCM ECU: a288 safing engine10 armed";
CM_ SG_ 2030 TRCM_a289_safingEngine11Armed "TRCM ECU: a289 safing engine11 armed";
CM_ SG_ 2030 TRCM_a290_safingEngine12Armed "TRCM ECU: a290 safing engine12 armed";
CM_ SG_ 2030 TRCM_a291_safingEngine13Armed "TRCM ECU: a291 safing engine13 armed";
CM_ SG_ 2030 TRCM_a292_safingEngine14Armed "TRCM ECU: a292 safing engine14 armed";
CM_ SG_ 2030 TRCM_a293_safingEngine15Armed "TRCM ECU: a293 safing engine15 armed";
CM_ SG_ 2030 TRCM_a294_safingEngine16Armed "TRCM ECU: a294 safing engine16 armed";
CM_ SG_ 2030 TRCM_a295_safingEngine17Armed "TRCM ECU: a295 safing engine17 armed";
CM_ SG_ 2030 TRCM_a296_safingEngine18Armed "TRCM ECU: a296 safing engine18 armed";
CM_ SG_ 2030 TRCM_a297_safingEngine19Armed "TRCM ECU: a297 safing engine19 armed";
CM_ SG_ 2030 TRCM_a298_safingEngine20Armed "TRCM ECU: a298 safing engine20 armed";
CM_ SG_ 2030 TRCM_a299_safingEngine21Armed "TRCM ECU: a299 safing engine21 armed";
CM_ SG_ 2030 TRCM_a300_unarmedAB1FPDeployComm "TRCM ECU: a300 unarmed AB1 FP deploy command";
CM_ SG_ 2030 TRCM_a301_unarmedAB1FDDeployComm "TRCM ECU: a301 unarmed AB1 FD deploy command";
CM_ SG_ 2030 TRCM_a302_unarmedAV1FPDeployComm "TRCM ECU: a302 unarmed AV1 FP deploy command";
CM_ SG_ 2030 TRCM_a303_unarmedFSABDeployComma "TRCM ECU: a303 unarmed FSAB deploy command";
CM_ SG_ 2030 TRCM_a304_unarmedAB2FPDeployComm "TRCM ECU: a304 unarmed AB2 FP deploy command";
CM_ SG_ 2030 TRCM_a305_unarmedAB2FDDeployComm "TRCM ECU: a305 unarmed AB2 FD deploy command";
CM_ SG_ 2030 TRCM_a306_unarmedAV1FDDeployComm "TRCM ECU: a306 unarmed AV1 FD deploy command";
CM_ SG_ 2030 TRCM_a307_unarmedLoop7DeployComm "TRCM ECU: a307 unarmed loop7 deploy command";
CM_ SG_ 2030 TRCM_a308_unarmedKA1FPDeployComm "TRCM ECU: a308 unarmed KA1 FP deploy command";
CM_ SG_ 2030 TRCM_a309_unarmedKA1FDDeployComm "TRCM ECU: a309 unarmed KA1 FD deploy command";
CM_ SG_ 2030 TRCM_a310_unarmedALLFRDeployComm "TRCM ECU: a310 unarmed ALLFR deploy command";
CM_ SG_ 2030 TRCM_a311_unarmedALLFLDeployComm "TRCM ECU: a311 unarmed ALLFL deploy command";
CM_ SG_ 2030 TRCM_a312_unarmedBT2FRDeployComm "TRCM ECU: a312 unarmed BT2 FR deploy command";
CM_ SG_ 2030 TRCM_a313_unarmedBT2FLDeployComm "TRCM ECU: a313 unarmed BT2 FL deploy command";
CM_ SG_ 2030 TRCM_a314_unarmedSA1FLDeployComm "TRCM ECU: a314 unarmed SA1 FL deploy command";
CM_ SG_ 2030 TRCM_a315_unarmedSA1FRDeployComm "TRCM ECU: a315 unarmed SA1 FR deploy command";
CM_ SG_ 2030 TRCM_a316_unarmedBT1RRDeployComm "TRCM ECU: a316 unarmed BT1 RR deploy command";
CM_ SG_ 2030 TRCM_a317_unarmedBT1RLDeployComm "TRCM ECU: a317 unarmed BT1 RL deploy command";
CM_ SG_ 2030 TRCM_a318_unarmedBT1FRDeployComm "TRCM ECU: a318 unarmed BT1 FR deploy command";
CM_ SG_ 2030 TRCM_a319_unarmedBT1FLDeployComm "TRCM ECU: a319 unarmed BT1 FL deploy command";
CM_ SG_ 2030 TRCM_a320_unarmedLoop20DeployCom "TRCM ECU: a320 unarmed loop20 deploy command";
CM_ SG_ 2030 TRCM_a321_unarmedLoop21DeployCom "TRCM ECU: a321 unarmed loop21 deploy command";
CM_ SG_ 2030 TRCM_a322_unarmedIC1FRDeployComm "TRCM ECU: a322 unarmed IC1 FR deploy command";
CM_ SG_ 2030 TRCM_a323_unarmedIC1FLDeployComm "TRCM ECU: a323 unarmed IC1 FL deploy command";
CM_ SG_ 2030 TRCM_a324_unarmedLoop24DeployCom "TRCM ECU: a324 unarmed loop24 deploy command";
CM_ SG_ 2030 TRCM_a325_unarmedLoop25DeployCom "TRCM ECU: a325 unarmed loop25 deploy command";
CM_ SG_ 2030 TRCM_a326_unarmedLoop26DeployCom "TRCM ECU: a326 unarmed loop26 deploy command";
CM_ SG_ 2030 TRCM_a327_unarmedLoop27DeployCom "TRCM ECU: a327 unarmed loop27 deploy command";
CM_ SG_ 2030 TRCM_a328_unarmedLoop28DeployCom "TRCM ECU: a328 unarmed loop28 deploy command";
CM_ SG_ 2030 TRCM_a329_unarmedLoop29DeployCom "TRCM ECU: a329 unarmed loop29 deploy command";
CM_ SG_ 2030 TRCM_a330_unarmedLoop30DeployCom "TRCM ECU: a330 unarmed loop30 deploy command";
CM_ SG_ 2030 TRCM_a331_unarmedLoop31DeployCom "TRCM ECU: a331 unarmed loop31 deploy command";
CM_ SG_ 2030 TRCM_a332_AB1FPDeployment "TRCM ECU: a332 AB1 FP deployment";
CM_ SG_ 2030 TRCM_a333_AB1FDDeployment "TRCM ECU: a333 AB1 FD deployment";
CM_ SG_ 2030 TRCM_a334_AV1FPDeployment "TRCM ECU: a334 AV1 FP deployment";
CM_ SG_ 2030 TRCM_a335_Loop3Deployment "TRCM ECU: a335 loop3 deployment";
CM_ SG_ 2030 TRCM_a336_AB2FPDeployment "TRCM ECU: a336 AB2 FP deployment";
CM_ SG_ 2030 TRCM_a337_AB2FDDeployment "TRCM ECU: a337 AB2 FD deployment";
CM_ SG_ 2030 TRCM_a338_AV1FDDeployment "TRCM ECU: a338 AV1 FD deployment";
CM_ SG_ 2030 TRCM_a339_Loop7Deployment "TRCM ECU: a339 loop7 deployment";
CM_ SG_ 2030 TRCM_a340_KA1FPDeployment "TRCM ECU: a340 KA1 FP deployment";
CM_ SG_ 2030 TRCM_a341_KA1FDDeployment "TRCM ECU: a341 KA1 FD deployment";
CM_ SG_ 2030 TRCM_a342_ALLFRDeployment "TRCM ECU: a342 ALLFR deployment";
CM_ SG_ 2030 TRCM_a343_ALLFLDeployment "TRCM ECU: a343 ALLFL deployment";
CM_ SG_ 2030 TRCM_a344_BT2FRDeployment "TRCM ECU: a344 BT2 FR deployment";
CM_ SG_ 2030 TRCM_a345_BT2FLDeployment "TRCM ECU: a345 BT2 FL deployment";
CM_ SG_ 2030 TRCM_a346_SA1FLDeployment "TRCM ECU: a346 SA1 FL deployment";
CM_ SG_ 2030 TRCM_a347_SA1FRDeployment "TRCM ECU: a347 SA1 FR deployment";
CM_ SG_ 2030 TRCM_a348_BT1RRDeployment "TRCM ECU: a348 BT1 RR deployment";
CM_ SG_ 2030 TRCM_a349_BT1RLDeployment "TRCM ECU: a349 BT1 RL deployment";
CM_ SG_ 2030 TRCM_a350_BT1FRDeployment "TRCM ECU: a350 BT1 FR deployment";
CM_ SG_ 2030 TRCM_a351_BT1FLDeployment "TRCM ECU: a351 BT1 FL deployment";
CM_ SG_ 2030 TRCM_a352_Loop20Deployment "TRCM ECU: a352 loop20 deployment";
CM_ SG_ 2030 TRCM_a353_Loop21Deployment "TRCM ECU: a353 loop21 deployment";
CM_ SG_ 2030 TRCM_a354_IC1FRDeployment "TRCM ECU: a354 IC1 FR deployment";
CM_ SG_ 2030 TRCM_a355_IC1FLDeployment "TRCM ECU: a355 IC1 FL deployment";
CM_ SG_ 2030 TRCM_a356_Loop24Deployment "TRCM ECU: a356 loop24 deployment";
CM_ SG_ 2030 TRCM_a357_Loop25Deployment "TRCM ECU: a357 loop25 deployment";
CM_ SG_ 2030 TRCM_a358_Loop26Deployment "TRCM ECU: a358 loop26 deployment";
CM_ SG_ 2030 TRCM_a359_Loop27Deployment "TRCM ECU: a359 loop27 deployment";
CM_ SG_ 2030 TRCM_a360_Loop28Deployment "TRCM ECU: a360 loop28 deployment";
CM_ SG_ 2030 TRCM_a361_Loop29Deployment "TRCM ECU: a361 loop29 deployment";
CM_ SG_ 2030 TRCM_a362_Loop30Deployment "TRCM ECU: a362 loop30 deployment";
CM_ SG_ 2030 TRCM_a363_Loop31Deployment "TRCM ECU: a363 loop31 deployment";
CM_ SG_ 2030 TRCM_a364_safingEngine0NoValidDa "TRCM ECU: a364 safing engine0 no valid data";
CM_ SG_ 2030 TRCM_a365_safingEngine1NoValidDa "TRCM ECU: a365 safing engine1 no valid data";
CM_ SG_ 2030 TRCM_a366_safingEngine2NoValidDa "TRCM ECU: a366 safing engine2 no valid data";
CM_ SG_ 2030 TRCM_a367_safingEngine3NoValidDa "TRCM ECU: a367 safing engine3 no valid data";
CM_ SG_ 2030 TRCM_a368_safingEngine4NoValidDa "TRCM ECU: a368 safing engine4 no valid data";
CM_ SG_ 2030 TRCM_a369_safingEngine5NoValidDa "TRCM ECU: a369 safing engine5 no valid data";
CM_ SG_ 2030 TRCM_a370_safingEngine6NoValidDa "TRCM ECU: a370 safing engine6 no valid data";
CM_ SG_ 2030 TRCM_a371_safingEngine7NoValidDa "TRCM ECU: a371 safing engine7 no valid data";
CM_ SG_ 2030 TRCM_a372_safingEngine8NoValidDa "TRCM ECU: a372 safing engine8 no valid data";
CM_ SG_ 2030 TRCM_a373_safingEngine9NoValidDa "TRCM ECU: a373 safing engine9 no valid data";
CM_ SG_ 2030 TRCM_a374_safingEngine10NoValidD "TRCM ECU: a374 safing engine10 no valid data";
CM_ SG_ 2030 TRCM_a375_safingEngine11NoValidD "TRCM ECU: a375 safing engine11 no valid data";
CM_ SG_ 2030 TRCM_a376_safingEngine12NoValidD "TRCM ECU: a376 safing engine12 no valid data";
CM_ SG_ 2030 TRCM_a377_safingEngine13NoValidD "TRCM ECU: a377 safing engine13 no valid data";
CM_ SG_ 2030 TRCM_a378_safingEngine14NoValidD "TRCM ECU: a378 safing engine14 no valid data";
CM_ SG_ 2030 TRCM_a379_safingEngine15NoValidD "TRCM ECU: a379 safing engine15 no valid data";
CM_ SG_ 2030 TRCM_a380_safingEngine16NoValidD "TRCM ECU: a380 safing engine16 no valid data";
CM_ SG_ 2030 TRCM_a381_safingEngine17NoValidD "TRCM ECU: a381 safing engine17 no valid data";
CM_ SG_ 2030 TRCM_a382_safingEngine18NoValidD "TRCM ECU: a382 safing engine18 no valid data";
CM_ SG_ 2030 TRCM_a383_safingEngine19NoValidD "TRCM ECU: a383 safing engine19 no valid data";
CM_ SG_ 2030 TRCM_a384_safingEngine20NoValidD "TRCM ECU: a384 safing engine20 no valid data";
CM_ SG_ 2030 TRCM_a385_safingEngine21NoValidD "TRCM ECU: a385 safing engine21 no valid data";
CM_ SG_ 2030 TRCM_a387_primaryAsicResetSource "TRCM ECU: a387 primary asic reset source";
CM_ SG_ 2030 TRCM_a388_cpuLoadHigh "TRCM ECU: a388 cpu load high";
CM_ SG_ 2030 TRCM_a389_asicPwrStatusError "TRCM ECU: a389 asic pwr status error";
CM_ SG_ 2030 TRCM_a390_systemAsicClockOrOpera "TRCM ECU: a390 system asic clock or operating state error";
CM_ SG_ 2030 TRCM_a391_extAsic1ClockOrOperati "TRCM ECU: a391 ext asic1 clock or operating state error";
CM_ SG_ 2030 TRCM_a392_extAsic2ClockOrOperati "TRCM ECU: a392 ext asic2 clock or operating state error";
CM_ SG_ 2030 TRCM_a393_depAdcConvertRatioErro "TRCM ECU: a393 dep adc convert ratio error";
CM_ SG_ 2030 TRCM_a394_gspiGlobalStatusWordEr "TRCM ECU: a394 gspi global status word error";
CM_ SG_ 2030 TRCM_a395_imuCalibrationNotDone "TRCM ECU: a395 imu calibration not done";
CM_ SG_ 2030 TRCM_a396_spiCommunicationProgra "TRCM ECU: a396 spi communication program error";
CM_ SG_ 2030 TRCM_a397_safingMonitorError "TRCM ECU: a397 safing monitor error";
CM_ SG_ 2030 TRCM_a398_asicNvmReprogrammed "TRCM ECU: a398 asic nvm reprogrammed";
CM_ SG_ 2030 TRCM_a400_AB1FPShortToGround "TRCM ECU: a400 AB1 FP short to ground";
CM_ SG_ 2030 TRCM_a401_AB1FPShortToBattery "TRCM ECU: a401 AB1 FP short to battery";
CM_ SG_ 2030 TRCM_a402_AB1FPOpen "TRCM ECU: a402 AB1 FP open";
CM_ SG_ 2030 TRCM_a403_AB1FPShortToSelf "TRCM ECU: a403 AB1 FP short to self";
CM_ SG_ 2030 TRCM_a404_AB1FPCrossCoupled "TRCM ECU: a404 AB1 FP cross coupled";
CM_ SG_ 2030 TRCM_a405_AB1FPConfigError "TRCM ECU: a405 AB1 FP config error";
CM_ SG_ 2030 TRCM_a406_AB1FDShortToGround "TRCM ECU: a406 AB1 FD short to ground";
CM_ SG_ 2030 TRCM_a407_AB1FDShortToBattery "TRCM ECU: a407 AB1 FD short to battery";
CM_ SG_ 2030 TRCM_a408_AB1FDOpen "TRCM ECU: a408 AB1 FD open";
CM_ SG_ 2030 TRCM_a409_AB1FDShortToSelf "TRCM ECU: a409 AB1 FD short to self";
CM_ SG_ 2030 TRCM_a410_AB1FDCrossCoupled "TRCM ECU: a410 AB1 FD cross coupled";
CM_ SG_ 2030 TRCM_a411_AB1FDConfigError "TRCM ECU: a411 AB1 FD config error";
CM_ SG_ 2030 TRCM_a412_PAVShortToGround "TRCM ECU: a412 PAV short to ground";
CM_ SG_ 2030 TRCM_a413_PAVShortToBattery "TRCM ECU: a413 PAV short to battery";
CM_ SG_ 2030 TRCM_a414_PAVOpen "TRCM ECU: a414 PAV open";
CM_ SG_ 2030 TRCM_a415_PAVShortToSelf "TRCM ECU: a415 PAV short to self";
CM_ SG_ 2030 TRCM_a416_PAVCrossCoupled "TRCM ECU: a416 PAV cross coupled";
CM_ SG_ 2030 TRCM_a417_PAVConfigError "TRCM ECU: a417 PAV config error";
CM_ SG_ 2030 TRCM_a418_AB2FPShortToGround "TRCM ECU: a418 AB2 FP short to ground";
CM_ SG_ 2030 TRCM_a419_AB2FPShortToBattery "TRCM ECU: a419 AB2 FP short to battery";
CM_ SG_ 2030 TRCM_a420_AB2FPOpen "TRCM ECU: a420 AB2 FP open";
CM_ SG_ 2030 TRCM_a421_AB2FPShortToSelf "TRCM ECU: a421 AB2 FP short to self";
CM_ SG_ 2030 TRCM_a422_AB2FPCrossCoupled "TRCM ECU: a422 AB2 FP cross coupled";
CM_ SG_ 2030 TRCM_a423_AB2FPConfigError "TRCM ECU: a423 AB2 FP config error";
CM_ SG_ 2030 TRCM_a424_AB2FDShortToGround "TRCM ECU: a424 AB2 FD short to ground";
CM_ SG_ 2030 TRCM_a425_AB2FDShortToBattery "TRCM ECU: a425 AB2 FD short to battery";
CM_ SG_ 2030 TRCM_a426_AB2FDOpen "TRCM ECU: a426 AB2 FD open";
CM_ SG_ 2030 TRCM_a427_AB2FDShortToSelf "TRCM ECU: a427 AB2 FD short to self";
CM_ SG_ 2030 TRCM_a428_AB2FDCrossCoupled "TRCM ECU: a428 AB2 FD cross coupled";
CM_ SG_ 2030 TRCM_a429_AB2FDConfigError "TRCM ECU: a429 AB2 FD config error";
CM_ SG_ 2030 TRCM_a430_DAVShortToGround "TRCM ECU: a430 DAV short to ground";
CM_ SG_ 2030 TRCM_a431_DAVShortToBattery "TRCM ECU: a431 DAV short to battery";
CM_ SG_ 2030 TRCM_a432_DAVOpen "TRCM ECU: a432 DAV open";
CM_ SG_ 2030 TRCM_a433_DAVShortToSelf "TRCM ECU: a433 DAV short to self";
CM_ SG_ 2030 TRCM_a434_DAVCrossCoupled "TRCM ECU: a434 DAV cross coupled";
CM_ SG_ 2030 TRCM_a435_DAVConfigError "TRCM ECU: a435 DAV config error";
CM_ SG_ 2030 TRCM_a436_IKBFPShortToGround "TRCM ECU: a436 IKBFP short to ground";
CM_ SG_ 2030 TRCM_a437_IKBFPShortToBattery "TRCM ECU: a437 IKBFP short to battery";
CM_ SG_ 2030 TRCM_a438_IKBFPOpen "TRCM ECU: a438 IKBFP open";
CM_ SG_ 2030 TRCM_a439_IKBFPShortToSelf "TRCM ECU: a439 IKBFP short to self";
CM_ SG_ 2030 TRCM_a440_IKBFPCrossCoupled "TRCM ECU: a440 IKBFP cross coupled";
CM_ SG_ 2030 TRCM_a441_IKBFPConfigError "TRCM ECU: a441 IKBFP config error";
CM_ SG_ 2030 TRCM_a442_IKBFDShortToGround "TRCM ECU: a442 IKBFD short to ground";
CM_ SG_ 2030 TRCM_a443_IKBFDShortToBattery "TRCM ECU: a443 IKBFD short to battery";
CM_ SG_ 2030 TRCM_a444_IKBFDOpen "TRCM ECU: a444 IKBFD open";
CM_ SG_ 2030 TRCM_a445_IKBFDShortToSelf "TRCM ECU: a445 IKBFD short to self";
CM_ SG_ 2030 TRCM_a446_IKBFDCrossCoupled "TRCM ECU: a446 IKBFD cross coupled";
CM_ SG_ 2030 TRCM_a447_IKBFDConfigError "TRCM ECU: a447 IKBFD config error";
CM_ SG_ 2030 TRCM_a448_PLLShortToGround "TRCM ECU: a448 PLL short to ground";
CM_ SG_ 2030 TRCM_a449_PLLShortToBattery "TRCM ECU: a449 PLL short to battery";
CM_ SG_ 2030 TRCM_a450_PLLOpen "TRCM ECU: a450 PLL open";
CM_ SG_ 2030 TRCM_a451_PLLShortToSelf "TRCM ECU: a451 PLL short to self";
CM_ SG_ 2030 TRCM_a452_PLLCrossCoupled "TRCM ECU: a452 PLL cross coupled";
CM_ SG_ 2030 TRCM_a453_PLLConfigError "TRCM ECU: a453 PLL config error";
CM_ SG_ 2030 TRCM_a454_DLLShortToGround "TRCM ECU: a454 DLL short to ground";
CM_ SG_ 2030 TRCM_a455_DLLShortToBattery "TRCM ECU: a455 DLL short to battery";
CM_ SG_ 2030 TRCM_a456_DLLOpen "TRCM ECU: a456 DLL open";
CM_ SG_ 2030 TRCM_a457_DLLShortToSelf "TRCM ECU: a457 DLL short to self";
CM_ SG_ 2030 TRCM_a458_DLLCrossCoupled "TRCM ECU: a458 DLL cross coupled";
CM_ SG_ 2030 TRCM_a459_DLLConfigError "TRCM ECU: a459 DLL config error";
CM_ SG_ 2030 TRCM_a460_BTRP_RetractorShortToG "TRCM ECU: a460 BTRP retractor short to ground";
CM_ SG_ 2030 TRCM_a461_BTRP_RetractorShortToB "TRCM ECU: a461 BTRP retractor short to battery";
CM_ SG_ 2030 TRCM_a462_BTRP_RetractorOpen "TRCM ECU: a462 BTRP retractor open";
CM_ SG_ 2030 TRCM_a463_BTRP_RetractorShortToS "TRCM ECU: a463 BTRP retractor short to self";
CM_ SG_ 2030 TRCM_a464_BTRP_RetractorCrossCou "TRCM ECU: a464 BTRP retractor cross coupled";
CM_ SG_ 2030 TRCM_a465_BTRP_RetractorConfigEr "TRCM ECU: a465 BTRP retractor config error";
CM_ SG_ 2030 TRCM_a466_BTRD_RetractorShortToG "TRCM ECU: a466 BTRD retractor short to ground";
CM_ SG_ 2030 TRCM_a467_BTRD_RetractorShortToB "TRCM ECU: a467 BTRD retractor short to battery";
CM_ SG_ 2030 TRCM_a468_BTRD_RetractorOpen "TRCM ECU: a468 BTRD retractor open";
CM_ SG_ 2030 TRCM_a469_BTRD_RetractorShortToS "TRCM ECU: a469 BTRD retractor short to self";
CM_ SG_ 2030 TRCM_a470_BTRD_RetractorCrossCou "TRCM ECU: a470 BTRD retractor cross coupled";
CM_ SG_ 2030 TRCM_a471_BTRD_RetractorConfigEr "TRCM ECU: a471 BTRD retractor config error";
CM_ SG_ 2030 TRCM_a472_SA1FLShortToGround "TRCM ECU: a472 SA1 FL short to ground";
CM_ SG_ 2030 TRCM_a473_SA1FLShortToBattery "TRCM ECU: a473 SA1 FL short to battery";
CM_ SG_ 2030 TRCM_a474_SA1FLOpen "TRCM ECU: a474 SA1 FL open";
CM_ SG_ 2030 TRCM_a475_SA1FLShortToSelf "TRCM ECU: a475 SA1 FL short to self";
CM_ SG_ 2030 TRCM_a476_SA1FLCrossCoupled "TRCM ECU: a476 SA1 FL cross coupled";
CM_ SG_ 2030 TRCM_a477_SA1FLConfigError "TRCM ECU: a477 SA1 FL config error";
CM_ SG_ 2030 TRCM_a478_SA1FRShortToGround "TRCM ECU: a478 SA1 FR short to ground";
CM_ SG_ 2030 TRCM_a479_SA1FRShortToBattery "TRCM ECU: a479 SA1 FR short to battery";
CM_ SG_ 2030 TRCM_a480_SA1FROpen "TRCM ECU: a480 SA1 FR open";
CM_ SG_ 2030 TRCM_a481_SA1FRShortToSelf "TRCM ECU: a481 SA1 FR short to self";
CM_ SG_ 2030 TRCM_a482_SA1FRCrossCoupled "TRCM ECU: a482 SA1 FR cross coupled";
CM_ SG_ 2030 TRCM_a483_SA1FRConfigError "TRCM ECU: a483 SA1 FR config error";
CM_ SG_ 2030 TRCM_a484_BTRRShortToGround "TRCM ECU: a484 BTRR short to ground";
CM_ SG_ 2030 TRCM_a485_BTRRShortToBattery "TRCM ECU: a485 BTRR short to battery";
CM_ SG_ 2030 TRCM_a486_BTRROpen "TRCM ECU: a486 BTRR open";
CM_ SG_ 2030 TRCM_a487_BTRRShortToSelf "TRCM ECU: a487 BTRR short to self";
CM_ SG_ 2030 TRCM_a488_BTRRCrossCoupled "TRCM ECU: a488 BTRR cross coupled";
CM_ SG_ 2030 TRCM_a489_BTRRConfigError "TRCM ECU: a489 BTRR config error";
CM_ SG_ 2030 TRCM_a490_BTRLShortToGround "TRCM ECU: a490 BTRL short to ground";
CM_ SG_ 2030 TRCM_a491_BTRLShortToBattery "TRCM ECU: a491 BTRL short to battery";
CM_ SG_ 2030 TRCM_a492_BTRLOpen "TRCM ECU: a492 BTRL open";
CM_ SG_ 2030 TRCM_a493_BTRLShortToSelf "TRCM ECU: a493 BTRL short to self";
CM_ SG_ 2030 TRCM_a494_BTRLCrossCoupled "TRCM ECU: a494 BTRL cross coupled";
CM_ SG_ 2030 TRCM_a495_BTRLConfigError "TRCM ECU: a495 BTRL config error";
CM_ SG_ 2030 TRCM_a496_BTRP_AnchorShortToGrou "TRCM ECU: a496 BTRP anchor short to ground";
CM_ SG_ 2030 TRCM_a497_BTRP_AnchorShortToBatt "TRCM ECU: a497 BTRP anchor short to battery";
CM_ SG_ 2030 TRCM_a498_BTRP_AnchorOpen "TRCM ECU: a498 BTRP anchor open";
CM_ SG_ 2030 TRCM_a499_BTRP_AnchorShortToSelf "TRCM ECU: a499 BTRP anchor short to self";
CM_ SG_ 2030 TRCM_a500_BTRP_AnchorCrossCouple "TRCM ECU: a500 BTRP anchor cross coupled";
CM_ SG_ 2030 TRCM_a501_BTRP_AnchorConfigError "TRCM ECU: a501 BTRP anchor config error";
CM_ SG_ 2030 TRCM_a502_BTRD_AnchorShortToGrou "TRCM ECU: a502 BTRD anchor short to ground";
CM_ SG_ 2030 TRCM_a503_BTRD_AnchorShortToBatt "TRCM ECU: a503 BTRD anchor short to battery";
CM_ SG_ 2030 TRCM_a504_BTRD_AnchorOpen "TRCM ECU: a504 BTRD anchor open";
CM_ SG_ 2030 TRCM_a505_BTRD_AnchorShortToSelf "TRCM ECU: a505 BTRD anchor short to self";
CM_ SG_ 2030 TRCM_a506_BTRD_AnchorCrossCouple "TRCM ECU: a506 BTRD anchor cross coupled";
CM_ SG_ 2030 TRCM_a507_BTRD_AnchorConfigError "TRCM ECU: a507 BTRD anchor config error";
CM_ SG_ 2030 TRCM_a508_IC1FRShortToGround "TRCM ECU: a508 IC1 FR short to ground";
CM_ SG_ 2030 TRCM_a509_IC1FRShortToBattery "TRCM ECU: a509 IC1 FR short to battery";
CM_ SG_ 2030 TRCM_a510_IC1FROpen "TRCM ECU: a510 IC1 FR open";
CM_ SG_ 2030 TRCM_a511_IC1FRShortToSelf "TRCM ECU: a511 IC1 FR short to self";
CM_ SG_ 2030 TRCM_a512_IC1FRCrossCoupled "TRCM ECU: a512 IC1 FR cross coupled";
CM_ SG_ 2030 TRCM_a513_IC1FRConfigError "TRCM ECU: a513 IC1 FR config error";
CM_ SG_ 2030 TRCM_a514_IC1FLShortToGround "TRCM ECU: a514 IC1 FL short to ground";
CM_ SG_ 2030 TRCM_a515_IC1FLShortToBattery "TRCM ECU: a515 IC1 FL short to battery";
CM_ SG_ 2030 TRCM_a516_IC1FLOpen "TRCM ECU: a516 IC1 FL open";
CM_ SG_ 2030 TRCM_a517_IC1FLShortToSelf "TRCM ECU: a517 IC1 FL short to self";
CM_ SG_ 2030 TRCM_a518_IC1FLCrossCoupled "TRCM ECU: a518 IC1 FL cross coupled";
CM_ SG_ 2030 TRCM_a519_IC1FLConfigError "TRCM ECU: a519 IC1 FL config error";
CM_ SG_ 2030 TRCM_a520_FSABShortToGround "TRCM ECU: a520 FSAB short to ground";
CM_ SG_ 2030 TRCM_a521_FSABShortToBattery "TRCM ECU: a521 FSAB short to battery";
CM_ SG_ 2030 TRCM_a522_FSABOpen "TRCM ECU: a522 FSAB open";
CM_ SG_ 2030 TRCM_a523_FSABShortToSelf "TRCM ECU: a523 FSAB short to self";
CM_ SG_ 2030 TRCM_a524_FSABCrossCoupled "TRCM ECU: a524 FSAB cross coupled";
CM_ SG_ 2030 TRCM_a525_FSABConfigError "TRCM ECU: a525 FSAB config error";
CM_ SG_ 2030 TRCM_a544_erCapDiagnosticsFailed "TRCM ECU: a544 er cap diagnostics failed";
CM_ SG_ 2030 TRCM_a545_erCapBelowAutarkyThres "TRCM ECU: a545 er cap below autarky threshold";
CM_ SG_ 2030 TRCM_a546_sensorValuesFaultedByS "TRCM ECU: a546 sensor values faulted by smart";
CM_ SG_ 2030 TRCM_a550_AlgoWake_RCM_WAKE_FRON "TRCM ECU: a550 algo wake RCM WAKE FRONT";
CM_ SG_ 2030 TRCM_a551_AlgoWake_RCM_WAKE_REAR "TRCM ECU: a551 algo wake RCM WAKE REAR";
CM_ SG_ 2030 TRCM_a552_AlgoWake_RCM_WAKE_LEFT "TRCM ECU: a552 algo wake RCM WAKE LEFT";
CM_ SG_ 2030 TRCM_a553_AlgoWake_RCM_WAKE_RIGH "TRCM ECU: a553 algo wake RCM WAKE RIGHT";
CM_ SG_ 2030 TRCM_a554_AlgoWake_PAS_LH_PLAUSI "TRCM ECU: a554 algo wake PAS LH PLAUSI FRONT";
CM_ SG_ 2030 TRCM_a555_AlgoWake_PAS_LH_PLAUSI "TRCM ECU: a555 algo wake PAS LH PLAUSI REAR";
CM_ SG_ 2030 TRCM_a556_AlgoWake_PAS_LH_PLAUSI "TRCM ECU: a556 algo wake PAS LH PLAUSI";
CM_ SG_ 2030 TRCM_a557_AlgoWake_PAS_RH_PLAUSI "TRCM ECU: a557 algo wake PAS RH PLAUSI FRONT";
CM_ SG_ 2030 TRCM_a558_AlgoWake_PAS_RH_PLAUSI "TRCM ECU: a558 algo wake PAS RH PLAUSI REAR";
CM_ SG_ 2030 TRCM_a559_AlgoWake_PAS_RH_PLAUSI "TRCM ECU: a559 algo wake PAS RH PLAUSI";
CM_ SG_ 2030 TRCM_a560_AlgoWake_RCM_WAKE_ROLL "TRCM ECU: a560 algo wake RCM WAKE ROLL LEFT";
CM_ SG_ 2030 TRCM_a561_AlgoWake_RCM_WAKE_ROLL "TRCM ECU: a561 algo wake RCM WAKE ROLL RIGHT";
CM_ SG_ 2030 TRCM_a562_AlgoWake_RCM_AWAKE_FRO "TRCM ECU: a562 algo wake RCM AWAKE FRONT";
CM_ SG_ 2030 TRCM_a563_AlgoWake_RCM_AWAKE_REA "TRCM ECU: a563 algo wake RCM AWAKE REAR";
CM_ SG_ 2030 TRCM_a564_AlgoWake_RCM_AWAKE_LEF "TRCM ECU: a564 algo wake RCM AWAKE LEFT";
CM_ SG_ 2030 TRCM_a565_AlgoWake_RCM_AWAKE_RIG "TRCM ECU: a565 algo wake RCM AWAKE RIGHT";
CM_ SG_ 2030 TRCM_a566_AlgoWake_RCM_AWAKE_ROL "TRCM ECU: a566 algo wake RCM AWAKE ROLL";
CM_ SG_ 2030 TRCM_a567_AlgoWake_RCM_AWAKE_X "TRCM ECU: a567 algo wake RCM AWAKE x";
CM_ SG_ 2030 TRCM_a568_AlgoWake_RCM_AWAKE_Y "TRCM ECU: a568 algo wake RCM AWAKE y";
CM_ SG_ 2030 TRCM_a569_AlgoWake_IMPACT_FINISH "TRCM ECU: a569 algo wake IMPACT FINISH x FRONT";
CM_ SG_ 2030 TRCM_a570_AlgoWake_IMPACT_FINISH "TRCM ECU: a570 algo wake IMPACT FINISH x REAR";
CM_ SG_ 2030 TRCM_a571_AlgoWake_IMPACT_FINISH "TRCM ECU: a571 algo wake IMPACT FINISH y RCM POS";
CM_ SG_ 2030 TRCM_a572_AlgoWake_IMPACT_FINISH "TRCM ECU: a572 algo wake IMPACT FINISH y RCM NEG";
CM_ SG_ 2030 TRCM_a573_AlgoWake_IMPACT_FINISH "TRCM ECU: a573 algo wake IMPACT FINISH y RCM";
CM_ SG_ 2030 TRCM_a574_AlgoWake_IMPACT_FINISH "TRCM ECU: a574 algo wake IMPACT FINISH ROLL RIGHT";
CM_ SG_ 2030 TRCM_a575_AlgoWake_IMPACT_FINISH "TRCM ECU: a575 algo wake IMPACT FINISH ROLL LEFT";
CM_ SG_ 2030 TRCM_a576_AlgoWake_IMPACT_FINISH "TRCM ECU: a576 algo wake IMPACT FINISH x";
CM_ SG_ 2030 TRCM_a577_AlgoWake_IMPACT_FINISH "TRCM ECU: a577 algo wake IMPACT FINISH y";
CM_ SG_ 2030 TRCM_a578_AlgoWake_IMPACT_FINISH "TRCM ECU: a578 algo wake IMPACT FINISH ROLL";
CM_ SG_ 2030 TRCM_a579_AlgoWake_RCM_ENABLED_X "TRCM ECU: a579 algo wake RCM ENABLED x";
CM_ SG_ 2030 TRCM_a580_AlgoWake_RCM_ENABLED_Y "TRCM ECU: a580 algo wake RCM ENABLED y";
CM_ SG_ 2030 TRCM_a581_AlgoWake_RCM_ENABLED_R "TRCM ECU: a581 algo wake RCM ENABLED ROLL";
CM_ SG_ 2030 TRCM_a582_AlgoWake_RCM_AWAKE "TRCM ECU: a582 algo wake RCM AWAKE";
CM_ SG_ 2030 TRCM_a588_yawRateOffsetPosLimit "TRCM ECU: a588 yaw rate offset pos limit";
CM_ SG_ 2030 TRCM_a589_yawRateOffsetNegLimit "TRCM ECU: a589 yaw rate offset neg limit";
CM_ SG_ 2030 TRCM_a590_pitchRateOffsetPosLimi "TRCM ECU: a590 pitch rate offset pos limit";
CM_ SG_ 2030 TRCM_a591_pitchRateOffsetNegLimi "TRCM ECU: a591 pitch rate offset neg limit";
CM_ SG_ 2030 TRCM_a592_rollRateOffsetPosLimit "TRCM ECU: a592 roll rate offset pos limit";
CM_ SG_ 2030 TRCM_a593_rollRateOffsetNegLimit "TRCM ECU: a593 roll rate offset neg limit";
CM_ SG_ 2030 TRCM_a594_longitudinalAccelOffse "TRCM ECU: a594 longitudinal accel offset pos limit";
CM_ SG_ 2030 TRCM_a595_longitudinalAccelOffse "TRCM ECU: a595 longitudinal accel offset neg limit";
CM_ SG_ 2030 TRCM_a596_lateralAccelOffsetPosL "TRCM ECU: a596 lateral accel offset pos limit";
CM_ SG_ 2030 TRCM_a597_lateralAccelOffsetNegL "TRCM ECU: a597 lateral accel offset neg limit";
CM_ SG_ 2030 TRCM_a598_verticalAccelOffsetPos "TRCM ECU: a598 vertical accel offset pos limit";
CM_ SG_ 2030 TRCM_a599_verticalAccelOffsetNeg "TRCM ECU: a599 vertical accel offset neg limit";
CM_ SG_ 2030 TRCM_a600_airbagAsicStartupFailu "TRCM ECU: a600 airbag asic startup failure";
CM_ SG_ 2030 TRCM_a601_loop0AsicStartupDiagno "TRCM ECU: a601 loop0 asic startup diagnostic failure";
CM_ SG_ 2030 TRCM_a602_loop1AsicStartupDiagno "TRCM ECU: a602 loop1 asic startup diagnostic failure";
CM_ SG_ 2030 TRCM_a603_loop2AsicStartupDiagno "TRCM ECU: a603 loop2 asic startup diagnostic failure";
CM_ SG_ 2030 TRCM_a604_loop3AsicStartupDiagno "TRCM ECU: a604 loop3 asic startup diagnostic failure";
CM_ SG_ 2030 TRCM_a605_loop4AsicStartupDiagno "TRCM ECU: a605 loop4 asic startup diagnostic failure";
CM_ SG_ 2030 TRCM_a606_loop5AsicStartupDiagno "TRCM ECU: a606 loop5 asic startup diagnostic failure";
CM_ SG_ 2030 TRCM_a607_loop6AsicStartupDiagno "TRCM ECU: a607 loop6 asic startup diagnostic failure";
CM_ SG_ 2030 TRCM_a608_loop7AsicStartupDiagno "TRCM ECU: a608 loop7 asic startup diagnostic failure";
CM_ SG_ 2030 TRCM_a609_loop8AsicStartupDiagno "TRCM ECU: a609 loop8 asic startup diagnostic failure";
CM_ SG_ 2030 TRCM_a610_loop9AsicStartupDiagno "TRCM ECU: a610 loop9 asic startup diagnostic failure";
CM_ SG_ 2030 TRCM_a611_loop10AsicStartupDiagn "TRCM ECU: a611 loop10 asic startup diagnostic failure";
CM_ SG_ 2030 TRCM_a612_loop11AsicStartupDiagn "TRCM ECU: a612 loop11 asic startup diagnostic failure";
CM_ SG_ 2030 TRCM_a613_loop12AsicStartupDiagn "TRCM ECU: a613 loop12 asic startup diagnostic failure";
CM_ SG_ 2030 TRCM_a614_loop13AsicStartupDiagn "TRCM ECU: a614 loop13 asic startup diagnostic failure";
CM_ SG_ 2030 TRCM_a615_loop14AsicStartupDiagn "TRCM ECU: a615 loop14 asic startup diagnostic failure";
CM_ SG_ 2030 TRCM_a616_loop15AsicStartupDiagn "TRCM ECU: a616 loop15 asic startup diagnostic failure";
CM_ SG_ 2030 TRCM_a617_loop16AsicStartupDiagn "TRCM ECU: a617 loop16 asic startup diagnostic failure";
CM_ SG_ 2030 TRCM_a618_loop17AsicStartupDiagn "TRCM ECU: a618 loop17 asic startup diagnostic failure";
CM_ SG_ 2030 TRCM_a619_loop18AsicStartupDiagn "TRCM ECU: a619 loop18 asic startup diagnostic failure";
CM_ SG_ 2030 TRCM_a620_loop19AsicStartupDiagn "TRCM ECU: a620 loop19 asic startup diagnostic failure";
CM_ SG_ 2030 TRCM_a621_loop20AsicStartupDiagn "TRCM ECU: a621 loop20 asic startup diagnostic failure";
CM_ SG_ 2030 TRCM_a622_loop21AsicStartupDiagn "TRCM ECU: a622 loop21 asic startup diagnostic failure";
CM_ SG_ 2030 TRCM_a623_loop22AsicStartupDiagn "TRCM ECU: a623 loop22 asic startup diagnostic failure";
CM_ SG_ 2030 TRCM_a624_loop23AsicStartupDiagn "TRCM ECU: a624 loop23 asic startup diagnostic failure";
CM_ SG_ 2030 TRCM_a625_loop24AsicStartupDiagn "TRCM ECU: a625 loop24 asic startup diagnostic failure";
CM_ SG_ 2030 TRCM_a626_loop25AsicStartupDiagn "TRCM ECU: a626 loop25 asic startup diagnostic failure";
CM_ SG_ 2030 TRCM_a627_loop26AsicStartupDiagn "TRCM ECU: a627 loop26 asic startup diagnostic failure";
CM_ SG_ 2030 TRCM_a628_loop27AsicStartupDiagn "TRCM ECU: a628 loop27 asic startup diagnostic failure";
CM_ SG_ 2030 TRCM_a629_loop28AsicStartupDiagn "TRCM ECU: a629 loop28 asic startup diagnostic failure";
CM_ SG_ 2030 TRCM_a630_loop29AsicStartupDiagn "TRCM ECU: a630 loop29 asic startup diagnostic failure";
CM_ SG_ 2030 TRCM_a631_loop30AsicStartupDiagn "TRCM ECU: a631 loop30 asic startup diagnostic failure";
CM_ SG_ 2030 TRCM_a632_loop31AsicStartupDiagn "TRCM ECU: a632 loop31 asic startup diagnostic failure";
CM_ BO_ 1641 "UDS ECU message: KOSTI asccm request";
CM_ SG_ 1641 UDS_KOSTIAsccmRequestData "UDS ECU: KOSTI asccm request data";
CM_ BO_ 1538 "UDS ECU message: bms request";
CM_ SG_ 1538 UDS_bmsRequestData "UDS ECU: bms request data";
CM_ BO_ 1579 "UDS ECU message: cc request";
CM_ SG_ 1579 UDS_ccRequestData "UDS ECU: cc request data";
CM_ BO_ 1539 "UDS ECU message: cmp request";
CM_ SG_ 1539 UDS_cmpRequestData "UDS ECU: cmp request data";
CM_ BO_ 1543 "UDS ECU message: cmpd request";
CM_ SG_ 1543 UDS_cmpdRequestData "UDS ECU: cmpd request data";
CM_ BO_ 1550 "UDS ECU message: cp request";
CM_ SG_ 1550 UDS_cpRequestData "UDS ECU: cp request data";
CM_ BO_ 1609 "UDS ECU message: das request";
CM_ SG_ 1609 UDS_dasRequestData "UDS ECU: das request data";
CM_ BO_ 1589 "UDS ECU message: di request";
CM_ SG_ 1589 UDS_diRequestData "UDS ECU: di request data";
CM_ BO_ 1541 "UDS ECU message: dif request";
CM_ SG_ 1541 UDS_difRequestData "UDS ECU: dif request data";
CM_ BO_ 1542 "UDS ECU message: dir request";
CM_ SG_ 1542 UDS_dirRequestData "UDS ECU: dir request data";
CM_ BO_ 1584 "UDS ECU message: epas3p request";
CM_ SG_ 1584 UDS_epas3pRequestData "UDS ECU: epas3p request data";
CM_ BO_ 1840 "UDS ECU message: epas3s request";
CM_ SG_ 1840 UDS_epas3sRequestData "UDS ECU: epas3s request data";
CM_ BO_ 1572 "UDS ECU message: epbl request";
CM_ SG_ 1572 UDS_epblRequestData_H "UDS ECU: epbl request data h";
CM_ SG_ 1572 UDS_epblRequestData_L "UDS ECU: epbl request data l";
CM_ BO_ 1574 "UDS ECU message: epbr request";
CM_ SG_ 1574 UDS_epbrRequestData_H "UDS ECU: epbr request data h";
CM_ SG_ 1574 UDS_epbrRequestData_L "UDS ECU: epbr request data l";
CM_ BO_ 1605 "UDS ECU message: esp request";
CM_ SG_ 1605 UDS_espRequestData "UDS ECU: esp request data";
CM_ BO_ 2015 "UDS ECU message: functional request";
CM_ SG_ 2015 UDS_functionalRequestData_0 "UDS ECU: functional request data 0";
CM_ SG_ 2015 UDS_functionalRequestData_1 "UDS ECU: functional request data 1";
CM_ SG_ 2015 UDS_functionalRequestData_2 "UDS ECU: functional request data 2";
CM_ SG_ 2015 UDS_functionalRequestData_3 "UDS ECU: functional request data 3";
CM_ SG_ 2015 UDS_functionalRequestData_4 "UDS ECU: functional request data 4";
CM_ SG_ 2015 UDS_functionalRequestData_5 "UDS ECU: functional request data 5";
CM_ SG_ 2015 UDS_functionalRequestData_6 "UDS ECU: functional request data 6";
CM_ SG_ 2015 UDS_functionalRequestData_7 "UDS ECU: functional request data 7";
CM_ BO_ 2014 "UDS ECU message: functional request CH";
CM_ SG_ 2014 UDS_functionalRequestDataCH "UDS ECU: functional request data CH";
CM_ BO_ 1552 "UDS ECU message: hvp request";
CM_ SG_ 1552 UDS_hvpRequestData "UDS ECU: hvp request data";
CM_ BO_ 1613 "UDS ECU message: ibst request";
CM_ SG_ 1613 UDS_ibstRequestData "UDS ECU: ibst request data";
CM_ BO_ 1560 "UDS ECU message: icr request";
CM_ SG_ 1560 UDS_icrRequestData "UDS ECU: icr request data";
CM_ BO_ 1603 "UDS ECU message: ocs1p request";
CM_ SG_ 1603 UDS_ocs1pRequestData "UDS ECU: ocs1p request data";
CM_ BO_ 1614 "UDS ECU message: park request";
CM_ SG_ 1614 UDS_parkRequestData "UDS ECU: park request data";
CM_ BO_ 1576 "UDS ECU message: pcs request";
CM_ SG_ 1576 UDS_pcsRequestData "UDS ECU: pcs request data";
CM_ BO_ 1634 "UDS ECU message: plg request";
CM_ SG_ 1634 UDS_plgRequestData "UDS ECU: plg request data";
CM_ BO_ 1568 "UDS ECU message: pm request";
CM_ SG_ 1568 UDS_pmRequestData "UDS ECU: pm request data";
CM_ BO_ 1604 "UDS ECU message: pmf request";
CM_ SG_ 1604 UDS_pmfRequestData "UDS ECU: pmf request data";
CM_ BO_ 1540 "UDS ECU message: pmr request";
CM_ SG_ 1540 UDS_pmrRequestData "UDS ECU: pmr request data";
CM_ BO_ 1734 "UDS ECU message: ptc request";
CM_ SG_ 1734 UDS_ptcRequestData "UDS ECU: ptc request data";
CM_ BO_ 1649 "UDS ECU message: radc request";
CM_ SG_ 1649 UDS_radcRequestData "UDS ECU: radc request data";
CM_ BO_ 1601 "UDS ECU message: rcm request";
CM_ SG_ 1601 UDS_rcmRequestData "UDS ECU: rcm request data";
CM_ BO_ 1664 "UDS ECU message: sccm request";
CM_ SG_ 1664 UDS_sccmRequestData "UDS ECU: sccm request data";
CM_ BO_ 1723 "UDS ECU message: sdcr request";
CM_ SG_ 1723 UDS_sdcrRequestData "UDS ECU: sdcr request data";
CM_ BO_ 1611 "UDS ECU message: tas request";
CM_ SG_ 1611 UDS_tasRequestData "UDS ECU: tas request data";
CM_ BO_ 1551 "UDS ECU message: thc request";
CM_ SG_ 1551 UDS_thcRequestData_H "UDS ECU: thc request data h";
CM_ SG_ 1551 UDS_thcRequestData_L "UDS ECU: thc request data l";
CM_ BO_ 1615 "UDS ECU message: tpms request";
CM_ SG_ 1615 UDS_tpmsRequestData "UDS ECU: tpms request data";
CM_ BO_ 1578 "UDS ECU message: vcbatt1 request";
CM_ SG_ 1578 UDS_vcbatt1RequestData "UDS ECU: vcbatt1 request data";
CM_ BO_ 1588 "UDS ECU message: vcbatt2 request";
CM_ SG_ 1588 UDS_vcbatt2RequestData "UDS ECU: vcbatt2 request data";
CM_ BO_ 1636 "UDS ECU message: vcbatt request";
CM_ SG_ 1636 UDS_vcbattRequestData "UDS ECU: vcbatt request data";
CM_ BO_ 1580 "UDS ECU message: vcfront1 request";
CM_ SG_ 1580 UDS_vcfront1RequestData "UDS ECU: vcfront1 request data";
CM_ BO_ 1582 "UDS ECU message: vcfront2 request";
CM_ SG_ 1582 UDS_vcfront2RequestData "UDS ECU: vcfront2 request data";
CM_ BO_ 1536 "UDS ECU message: vcfront request";
CM_ SG_ 1536 UDS_vcfrontRequestData "UDS ECU: vcfront request data";
CM_ BO_ 1570 "UDS ECU message: vcleft request";
CM_ SG_ 1570 UDS_vcleftRequestData_H "UDS ECU: vcleft request data h";
CM_ SG_ 1570 UDS_vcleftRequestData_L "UDS ECU: vcleft request data l";
CM_ BO_ 1544 "UDS ECU message: vcright request";
CM_ SG_ 1544 UDS_vcrightRequestData_H "UDS ECU: vcright request data h";
CM_ SG_ 1544 UDS_vcrightRequestData_L "UDS ECU: vcright request data l";
CM_ BO_ 1546 "UDS ECU message: vcsec request";
CM_ SG_ 1546 UDS_vcsecRequestData "UDS ECU: vcsec request data";
BA_DEF_ BO_ "GenMsgCycleTime" INT 0 3600000;
BA_DEF_ BO_ "GenMsgSendType" ENUM "Cyclic","NotUsed","NotUsed","NotUsed","NotUsed","NotUsed","NotUsed","IfActive","NoMsgSendType","NotUsed";
BA_DEF_ BO_ "VFrameFormat" ENUM "StandardCAN","ExtendedCAN","reserved","J1939PG","reserved","reserved","reserved","reserved","reserved","reserved","reserved","reserved","reserved","reserved","StandardCAN_FD","ExtendedCAN_FD";
BA_DEF_ BO_ "CANFD_BRS" ENUM "0","1";
BA_DEF_ SG_ "GenSigSNA" STRING;
BA_DEF_ SG_ "SystemSignalLongSymbol" STRING;
BA_DEF_ SG_ "Confidence" ENUM "validated","plausible","layout-only","contradicted";
BA_DEF_DEF_ "GenMsgCycleTime" 0;
BA_DEF_DEF_ "GenMsgSendType" "NoMsgSendType";
BA_DEF_DEF_ "VFrameFormat" "StandardCAN";
BA_DEF_DEF_ "CANFD_BRS" "1";
BA_DEF_DEF_ "GenSigSNA" "";
BA_DEF_DEF_ "SystemSignalLongSymbol" "";
BA_DEF_DEF_ "Confidence" "layout-only";
BA_ "GenMsgCycleTime" BO_ 2030 100;
BA_ "GenMsgSendType" BO_ 2030 0;
BA_ "Confidence" SG_ 2030 TRCM_matrixIndex 1;
BA_ "SystemSignalLongSymbol" SG_ 2030 TRCM_a012_asm5TemperatureOutside "TRCM_a012_asm5TemperatureOutsideSignalRange";
BA_ "SystemSignalLongSymbol" SG_ 2030 TRCM_a014_asm3TemperatureOutside "TRCM_a014_asm3TemperatureOutsideSignalRange";
BA_ "SystemSignalLongSymbol" SG_ 2030 TRCM_a017_asm5TemperatureOutside "TRCM_a017_asm5TemperatureOutsideOperatingRange";
BA_ "SystemSignalLongSymbol" SG_ 2030 TRCM_a018_asm3TemperatureOutside "TRCM_a018_asm3TemperatureOutsideOperatingRange";
BA_ "SystemSignalLongSymbol" SG_ 2030 TRCM_a026_airbagAsicDiagnosticFa "TRCM_a026_airbagAsicDiagnosticFault";
BA_ "SystemSignalLongSymbol" SG_ 2030 TRCM_a027_airbagAsicDeploymentDi "TRCM_a027_airbagAsicDeploymentDiagnosticFault";
BA_ "SystemSignalLongSymbol" SG_ 2030 TRCM_a074_ais2120SelfTestXPositi "TRCM_a074_ais2120SelfTestXPositiveFailed";
BA_ "SystemSignalLongSymbol" SG_ 2030 TRCM_a075_ais2120SelfTestXNegati "TRCM_a075_ais2120SelfTestXNegativeFailed";
BA_ "SystemSignalLongSymbol" SG_ 2030 TRCM_a076_ais2120SelfTestYPositi "TRCM_a076_ais2120SelfTestYPositiveFailed";
BA_ "SystemSignalLongSymbol" SG_ 2030 TRCM_a077_ais2120SelfTestYNegati "TRCM_a077_ais2120SelfTestYNegativeFailed";
BA_ "SystemSignalLongSymbol" SG_ 2030 TRCM_a121_glacierInitialStatusFa "TRCM_a121_glacierInitialStatusFailure";
BA_ "SystemSignalLongSymbol" SG_ 2030 TRCM_a122_glacierTraceabilityRea "TRCM_a122_glacierTraceabilityReadoutA0A0Failure";
BA_ "SystemSignalLongSymbol" SG_ 2030 TRCM_a123_glacierTraceabilityRea "TRCM_a123_glacierTraceabilityReadoutB0B0Failure";
BA_ "SystemSignalLongSymbol" SG_ 2030 TRCM_a124_glacierRegisterPattern "TRCM_a124_glacierRegisterPatternWriteFailure";
BA_ "SystemSignalLongSymbol" SG_ 2030 TRCM_a125_glacierFixedPatternSel "TRCM_a125_glacierFixedPatternSelfTestFailure";
BA_ "SystemSignalLongSymbol" SG_ 2030 TRCM_a126_glacierSelfTestEFailur "TRCM_a126_glacierSelfTestEFailure";
BA_ "SystemSignalLongSymbol" SG_ 2030 TRCM_a127_glacierSelfTestFFailur "TRCM_a127_glacierSelfTestFFailure";
BA_ "SystemSignalLongSymbol" SG_ 2030 TRCM_a128_glacierAnalogSelfTestF "TRCM_a128_glacierAnalogSelfTestFailure";
BA_ "SystemSignalLongSymbol" SG_ 2030 TRCM_a129_glacierOscillatorVerif "TRCM_a129_glacierOscillatorVerificationFailure";
BA_ "SystemSignalLongSymbol" SG_ 2030 TRCM_a130_glacierFinalStatusFail "TRCM_a130_glacierFinalStatusFailure";
BA_ "SystemSignalLongSymbol" SG_ 2030 TRCM_a131_glacierOffsetVerificat "TRCM_a131_glacierOffsetVerificationFailure";
BA_ "SystemSignalLongSymbol" SG_ 2030 TRCM_a132_glacierNormalOperation "TRCM_a132_glacierNormalOperationFailure";
BA_ "SystemSignalLongSymbol" SG_ 2030 TRCM_a137_ext1AsicSnoopTestFaile "TRCM_a137_ext1AsicSnoopTestFailed";
BA_ "SystemSignalLongSymbol" SG_ 2030 TRCM_a138_ext2AsicSnoopTestFaile "TRCM_a138_ext2AsicSnoopTestFailed";
BA_ "SystemSignalLongSymbol" SG_ 2030 TRCM_a140_frontRightAccelInitFai "TRCM_a140_frontRightAccelInitFailure";
BA_ "SystemSignalLongSymbol" SG_ 2030 TRCM_a141_frontRightAccelShortTo "TRCM_a141_frontRightAccelShortToGround";
BA_ "SystemSignalLongSymbol" SG_ 2030 TRCM_a142_frontRightAccelShortTo "TRCM_a142_frontRightAccelShortToBattery";
BA_ "SystemSignalLongSymbol" SG_ 2030 TRCM_a143_frontRightAccelConfigE "TRCM_a143_frontRightAccelConfigError";
BA_ "SystemSignalLongSymbol" SG_ 2030 TRCM_a145_frontRightAccelCommErr "TRCM_a145_frontRightAccelCommError";
BA_ "SystemSignalLongSymbol" SG_ 2030 TRCM_a146_frontRightAccelSensorD "TRCM_a146_frontRightAccelSensorDefect";
BA_ "SystemSignalLongSymbol" SG_ 2030 TRCM_a147_frontRightAccelSignalM "TRCM_a147_frontRightAccelSignalMonitor";
BA_ "SystemSignalLongSymbol" SG_ 2030 TRCM_a150_rightFrontDoorPressure "TRCM_a150_rightFrontDoorPressureInitFailure";
BA_ "SystemSignalLongSymbol" SG_ 2030 TRCM_a151_rightFrontDoorPressure "TRCM_a151_rightFrontDoorPressureShortToGround";
BA_ "SystemSignalLongSymbol" SG_ 2030 TRCM_a152_rightFrontDoorPressure "TRCM_a152_rightFrontDoorPressureShortToBattery";
BA_ "SystemSignalLongSymbol" SG_ 2030 TRCM_a153_rightFrontDoorPressure "TRCM_a153_rightFrontDoorPressureConfigError";
BA_ "SystemSignalLongSymbol" SG_ 2030 TRCM_a154_rightFrontDoorPressure "TRCM_a154_rightFrontDoorPressureOpen";
BA_ "SystemSignalLongSymbol" SG_ 2030 TRCM_a155_rightFrontDoorPressure "TRCM_a155_rightFrontDoorPressureCommError";
BA_ "SystemSignalLongSymbol" SG_ 2030 TRCM_a156_rightFrontDoorPressure "TRCM_a156_rightFrontDoorPressureSensorDefect";
BA_ "SystemSignalLongSymbol" SG_ 2030 TRCM_a157_rightFrontDoorPressure "TRCM_a157_rightFrontDoorPressureSignalMonitor";
BA_ "SystemSignalLongSymbol" SG_ 2030 TRCM_a160_frontLeftAccelInitFail "TRCM_a160_frontLeftAccelInitFailure";
BA_ "SystemSignalLongSymbol" SG_ 2030 TRCM_a161_frontLeftAccelShortToG "TRCM_a161_frontLeftAccelShortToGround";
BA_ "SystemSignalLongSymbol" SG_ 2030 TRCM_a162_frontLeftAccelShortToB "TRCM_a162_frontLeftAccelShortToBattery";
BA_ "SystemSignalLongSymbol" SG_ 2030 TRCM_a163_frontLeftAccelConfigEr "TRCM_a163_frontLeftAccelConfigError";
BA_ "SystemSignalLongSymbol" SG_ 2030 TRCM_a165_frontLeftAccelCommErro "TRCM_a165_frontLeftAccelCommError";
BA_ "SystemSignalLongSymbol" SG_ 2030 TRCM_a166_frontLeftAccelSensorDe "TRCM_a166_frontLeftAccelSensorDefect";
BA_ "SystemSignalLongSymbol" SG_ 2030 TRCM_a167_frontLeftAccelSignalMo "TRCM_a167_frontLeftAccelSignalMonitor";
BA_ "SystemSignalLongSymbol" SG_ 2030 TRCM_a170_leftFrontDoorPressureI "TRCM_a170_leftFrontDoorPressureInitFailure";
BA_ "SystemSignalLongSymbol" SG_ 2030 TRCM_a171_leftFrontDoorPressureS "TRCM_a171_leftFrontDoorPressureShortToGround";
BA_ "SystemSignalLongSymbol" SG_ 2030 TRCM_a172_leftFrontDoorPressureS "TRCM_a172_leftFrontDoorPressureShortToBattery";
BA_ "SystemSignalLongSymbol" SG_ 2030 TRCM_a173_leftFrontDoorPressureC "TRCM_a173_leftFrontDoorPressureConfigError";
BA_ "SystemSignalLongSymbol" SG_ 2030 TRCM_a174_leftFrontDoorPressureO "TRCM_a174_leftFrontDoorPressureOpen";
BA_ "SystemSignalLongSymbol" SG_ 2030 TRCM_a175_leftFrontDoorPressureC "TRCM_a175_leftFrontDoorPressureCommError";
BA_ "SystemSignalLongSymbol" SG_ 2030 TRCM_a176_leftFrontDoorPressureS "TRCM_a176_leftFrontDoorPressureSensorDefect";
BA_ "SystemSignalLongSymbol" SG_ 2030 TRCM_a177_leftFrontDoorPressureS "TRCM_a177_leftFrontDoorPressureSignalMonitor";
BA_ "SystemSignalLongSymbol" SG_ 2030 TRCM_a180_rightBPillarAccelInitF "TRCM_a180_rightBPillarAccelInitFailure";
BA_ "SystemSignalLongSymbol" SG_ 2030 TRCM_a181_rightBPillarAccelShort "TRCM_a181_rightBPillarAccelShortToGround";
BA_ "SystemSignalLongSymbol" SG_ 2030 TRCM_a182_rightBPillarAccelShort "TRCM_a182_rightBPillarAccelShortToBattery";
BA_ "SystemSignalLongSymbol" SG_ 2030 TRCM_a183_rightBPillarAccelConfi "TRCM_a183_rightBPillarAccelConfigError";
BA_ "SystemSignalLongSymbol" SG_ 2030 TRCM_a185_rightBPillarAccelCommE "TRCM_a185_rightBPillarAccelCommError";
BA_ "SystemSignalLongSymbol" SG_ 2030 TRCM_a186_rightBPillarAccelSenso "TRCM_a186_rightBPillarAccelSensorDefect";
BA_ "SystemSignalLongSymbol" SG_ 2030 TRCM_a187_rightBPillarAccelSigna "TRCM_a187_rightBPillarAccelSignalMonitor";
BA_ "SystemSignalLongSymbol" SG_ 2030 TRCM_a190_leftBPillarAccelInitFa "TRCM_a190_leftBPillarAccelInitFailure";
BA_ "SystemSignalLongSymbol" SG_ 2030 TRCM_a191_leftBPillarAccelShortT "TRCM_a191_leftBPillarAccelShortToGround";
BA_ "SystemSignalLongSymbol" SG_ 2030 TRCM_a192_leftBPillarAccelShortT "TRCM_a192_leftBPillarAccelShortToBattery";
BA_ "SystemSignalLongSymbol" SG_ 2030 TRCM_a193_leftBPillarAccelConfig "TRCM_a193_leftBPillarAccelConfigError";
BA_ "SystemSignalLongSymbol" SG_ 2030 TRCM_a195_leftBPillarAccelCommEr "TRCM_a195_leftBPillarAccelCommError";
BA_ "SystemSignalLongSymbol" SG_ 2030 TRCM_a196_leftBPillarAccelSensor "TRCM_a196_leftBPillarAccelSensorDefect";
BA_ "SystemSignalLongSymbol" SG_ 2030 TRCM_a197_leftBPillarAccelSignal "TRCM_a197_leftBPillarAccelSignalMonitor";
BA_ "SystemSignalLongSymbol" SG_ 2030 TRCM_a200_frontCenterAccelInitFa "TRCM_a200_frontCenterAccelInitFailure";
BA_ "SystemSignalLongSymbol" SG_ 2030 TRCM_a201_frontCenterAccelShortT "TRCM_a201_frontCenterAccelShortToGround";
BA_ "SystemSignalLongSymbol" SG_ 2030 TRCM_a202_frontCenterAccelShortT "TRCM_a202_frontCenterAccelShortToBattery";
BA_ "SystemSignalLongSymbol" SG_ 2030 TRCM_a203_frontCenterAccelConfig "TRCM_a203_frontCenterAccelConfigError";
BA_ "SystemSignalLongSymbol" SG_ 2030 TRCM_a205_frontCenterAccelCommEr "TRCM_a205_frontCenterAccelCommError";
BA_ "SystemSignalLongSymbol" SG_ 2030 TRCM_a206_frontCenterAccelSensor "TRCM_a206_frontCenterAccelSensorDefect";
BA_ "SystemSignalLongSymbol" SG_ 2030 TRCM_a207_frontCenterAccelSignal "TRCM_a207_frontCenterAccelSignalMonitor";
BA_ "SystemSignalLongSymbol" SG_ 2030 TRCM_a210_leftCPillarAccelInitFa "TRCM_a210_leftCPillarAccelInitFailure";
BA_ "SystemSignalLongSymbol" SG_ 2030 TRCM_a211_leftCPillarAccelShortT "TRCM_a211_leftCPillarAccelShortToGround";
BA_ "SystemSignalLongSymbol" SG_ 2030 TRCM_a212_leftCPillarAccelShortT "TRCM_a212_leftCPillarAccelShortToBattery";
BA_ "SystemSignalLongSymbol" SG_ 2030 TRCM_a213_leftCPillarAccelConfig "TRCM_a213_leftCPillarAccelConfigError";
BA_ "SystemSignalLongSymbol" SG_ 2030 TRCM_a215_leftCPillarAccelCommEr "TRCM_a215_leftCPillarAccelCommError";
BA_ "SystemSignalLongSymbol" SG_ 2030 TRCM_a216_leftCPillarAccelSensor "TRCM_a216_leftCPillarAccelSensorDefect";
BA_ "SystemSignalLongSymbol" SG_ 2030 TRCM_a217_leftCPillarAccelSignal "TRCM_a217_leftCPillarAccelSignalMonitor";
BA_ "SystemSignalLongSymbol" SG_ 2030 TRCM_a220_rightCPillarAccelInitF "TRCM_a220_rightCPillarAccelInitFailure";
BA_ "SystemSignalLongSymbol" SG_ 2030 TRCM_a221_rightCPillarAccelShort "TRCM_a221_rightCPillarAccelShortToGround";
BA_ "SystemSignalLongSymbol" SG_ 2030 TRCM_a222_rightCPillarAccelShort "TRCM_a222_rightCPillarAccelShortToBattery";
BA_ "SystemSignalLongSymbol" SG_ 2030 TRCM_a223_rightCPillarAccelConfi "TRCM_a223_rightCPillarAccelConfigError";
BA_ "SystemSignalLongSymbol" SG_ 2030 TRCM_a225_rightCPillarAccelCommE "TRCM_a225_rightCPillarAccelCommError";
BA_ "SystemSignalLongSymbol" SG_ 2030 TRCM_a226_rightCPillarAccelSenso "TRCM_a226_rightCPillarAccelSensorDefect";
BA_ "SystemSignalLongSymbol" SG_ 2030 TRCM_a227_rightCPillarAccelSigna "TRCM_a227_rightCPillarAccelSignalMonitor";
BA_ "SystemSignalLongSymbol" SG_ 2030 TRCM_a230_leftRearDoorPressureIn "TRCM_a230_leftRearDoorPressureInitFailure";
BA_ "SystemSignalLongSymbol" SG_ 2030 TRCM_a231_leftRearDoorPressureSh "TRCM_a231_leftRearDoorPressureShortToGround";
BA_ "SystemSignalLongSymbol" SG_ 2030 TRCM_a232_leftRearDoorPressureSh "TRCM_a232_leftRearDoorPressureShortToBattery";
BA_ "SystemSignalLongSymbol" SG_ 2030 TRCM_a233_leftRearDoorPressureCo "TRCM_a233_leftRearDoorPressureConfigError";
BA_ "SystemSignalLongSymbol" SG_ 2030 TRCM_a234_leftRearDoorPressureOp "TRCM_a234_leftRearDoorPressureOpen";
BA_ "SystemSignalLongSymbol" SG_ 2030 TRCM_a235_leftRearDoorPressureCo "TRCM_a235_leftRearDoorPressureCommError";
BA_ "SystemSignalLongSymbol" SG_ 2030 TRCM_a236_leftRearDoorPressureSe "TRCM_a236_leftRearDoorPressureSensorDefect";
BA_ "SystemSignalLongSymbol" SG_ 2030 TRCM_a237_leftRearDoorPressureSi "TRCM_a237_leftRearDoorPressureSignalMonitor";
BA_ "SystemSignalLongSymbol" SG_ 2030 TRCM_a240_rightRearDoorPressureI "TRCM_a240_rightRearDoorPressureInitFailure";
BA_ "SystemSignalLongSymbol" SG_ 2030 TRCM_a241_rightRearDoorPressureS "TRCM_a241_rightRearDoorPressureShortToGround";
BA_ "SystemSignalLongSymbol" SG_ 2030 TRCM_a242_rightRearDoorPressureS "TRCM_a242_rightRearDoorPressureShortToBattery";
BA_ "SystemSignalLongSymbol" SG_ 2030 TRCM_a243_rightRearDoorPressureC "TRCM_a243_rightRearDoorPressureConfigError";
BA_ "SystemSignalLongSymbol" SG_ 2030 TRCM_a244_rightRearDoorPressureO "TRCM_a244_rightRearDoorPressureOpen";
BA_ "SystemSignalLongSymbol" SG_ 2030 TRCM_a245_rightRearDoorPressureC "TRCM_a245_rightRearDoorPressureCommError";
BA_ "SystemSignalLongSymbol" SG_ 2030 TRCM_a246_rightRearDoorPressureS "TRCM_a246_rightRearDoorPressureSensorDefect";
BA_ "SystemSignalLongSymbol" SG_ 2030 TRCM_a247_rightRearDoorPressureS "TRCM_a247_rightRearDoorPressureSignalMonitor";
BA_ "SystemSignalLongSymbol" SG_ 2030 TRCM_a250_frontCenterAccelXInitF "TRCM_a250_frontCenterAccelXInitFailure";
BA_ "SystemSignalLongSymbol" SG_ 2030 TRCM_a251_frontCenterAccelXShort "TRCM_a251_frontCenterAccelXShortToGround";
BA_ "SystemSignalLongSymbol" SG_ 2030 TRCM_a252_frontCenterAccelXShort "TRCM_a252_frontCenterAccelXShortToBattery";
BA_ "SystemSignalLongSymbol" SG_ 2030 TRCM_a253_frontCenterAccelXConfi "TRCM_a253_frontCenterAccelXConfigError";
BA_ "SystemSignalLongSymbol" SG_ 2030 TRCM_a255_frontCenterAccelXCommE "TRCM_a255_frontCenterAccelXCommError";
BA_ "SystemSignalLongSymbol" SG_ 2030 TRCM_a256_frontCenterAccelXSenso "TRCM_a256_frontCenterAccelXSensorDefect";
BA_ "SystemSignalLongSymbol" SG_ 2030 TRCM_a257_frontCenterAccelXSigna "TRCM_a257_frontCenterAccelXSignalMonitor";
BA_ "SystemSignalLongSymbol" SG_ 2030 TRCM_a260_frontCenterAccelYInitF "TRCM_a260_frontCenterAccelYInitFailure";
BA_ "SystemSignalLongSymbol" SG_ 2030 TRCM_a261_frontCenterAccelYShort "TRCM_a261_frontCenterAccelYShortToGround";
BA_ "SystemSignalLongSymbol" SG_ 2030 TRCM_a262_frontCenterAccelYShort "TRCM_a262_frontCenterAccelYShortToBattery";
BA_ "SystemSignalLongSymbol" SG_ 2030 TRCM_a263_frontCenterAccelYConfi "TRCM_a263_frontCenterAccelYConfigError";
BA_ "SystemSignalLongSymbol" SG_ 2030 TRCM_a265_frontCenterAccelYCommE "TRCM_a265_frontCenterAccelYCommError";
BA_ "SystemSignalLongSymbol" SG_ 2030 TRCM_a266_frontCenterAccelYSenso "TRCM_a266_frontCenterAccelYSensorDefect";
BA_ "SystemSignalLongSymbol" SG_ 2030 TRCM_a267_frontCenterAccelYSigna "TRCM_a267_frontCenterAccelYSignalMonitor";
BA_ "SystemSignalLongSymbol" SG_ 2030 TRCM_a300_unarmedAB1FPDeployComm "TRCM_a300_unarmedAB1FPDeployCommand";
BA_ "SystemSignalLongSymbol" SG_ 2030 TRCM_a301_unarmedAB1FDDeployComm "TRCM_a301_unarmedAB1FDDeployCommand";
BA_ "SystemSignalLongSymbol" SG_ 2030 TRCM_a302_unarmedAV1FPDeployComm "TRCM_a302_unarmedAV1FPDeployCommand";
BA_ "SystemSignalLongSymbol" SG_ 2030 TRCM_a303_unarmedFSABDeployComma "TRCM_a303_unarmedFSABDeployCommand";
BA_ "SystemSignalLongSymbol" SG_ 2030 TRCM_a304_unarmedAB2FPDeployComm "TRCM_a304_unarmedAB2FPDeployCommand";
BA_ "SystemSignalLongSymbol" SG_ 2030 TRCM_a305_unarmedAB2FDDeployComm "TRCM_a305_unarmedAB2FDDeployCommand";
BA_ "SystemSignalLongSymbol" SG_ 2030 TRCM_a306_unarmedAV1FDDeployComm "TRCM_a306_unarmedAV1FDDeployCommand";
BA_ "SystemSignalLongSymbol" SG_ 2030 TRCM_a307_unarmedLoop7DeployComm "TRCM_a307_unarmedLoop7DeployCommand";
BA_ "SystemSignalLongSymbol" SG_ 2030 TRCM_a308_unarmedKA1FPDeployComm "TRCM_a308_unarmedKA1FPDeployCommand";
BA_ "SystemSignalLongSymbol" SG_ 2030 TRCM_a309_unarmedKA1FDDeployComm "TRCM_a309_unarmedKA1FDDeployCommand";
BA_ "SystemSignalLongSymbol" SG_ 2030 TRCM_a310_unarmedALLFRDeployComm "TRCM_a310_unarmedALLFRDeployCommand";
BA_ "SystemSignalLongSymbol" SG_ 2030 TRCM_a311_unarmedALLFLDeployComm "TRCM_a311_unarmedALLFLDeployCommand";
BA_ "SystemSignalLongSymbol" SG_ 2030 TRCM_a312_unarmedBT2FRDeployComm "TRCM_a312_unarmedBT2FRDeployCommand";
BA_ "SystemSignalLongSymbol" SG_ 2030 TRCM_a313_unarmedBT2FLDeployComm "TRCM_a313_unarmedBT2FLDeployCommand";
BA_ "SystemSignalLongSymbol" SG_ 2030 TRCM_a314_unarmedSA1FLDeployComm "TRCM_a314_unarmedSA1FLDeployCommand";
BA_ "SystemSignalLongSymbol" SG_ 2030 TRCM_a315_unarmedSA1FRDeployComm "TRCM_a315_unarmedSA1FRDeployCommand";
BA_ "SystemSignalLongSymbol" SG_ 2030 TRCM_a316_unarmedBT1RRDeployComm "TRCM_a316_unarmedBT1RRDeployCommand";
BA_ "SystemSignalLongSymbol" SG_ 2030 TRCM_a317_unarmedBT1RLDeployComm "TRCM_a317_unarmedBT1RLDeployCommand";
BA_ "SystemSignalLongSymbol" SG_ 2030 TRCM_a318_unarmedBT1FRDeployComm "TRCM_a318_unarmedBT1FRDeployCommand";
BA_ "SystemSignalLongSymbol" SG_ 2030 TRCM_a319_unarmedBT1FLDeployComm "TRCM_a319_unarmedBT1FLDeployCommand";
BA_ "SystemSignalLongSymbol" SG_ 2030 TRCM_a320_unarmedLoop20DeployCom "TRCM_a320_unarmedLoop20DeployCommand";
BA_ "SystemSignalLongSymbol" SG_ 2030 TRCM_a321_unarmedLoop21DeployCom "TRCM_a321_unarmedLoop21DeployCommand";
BA_ "SystemSignalLongSymbol" SG_ 2030 TRCM_a322_unarmedIC1FRDeployComm "TRCM_a322_unarmedIC1FRDeployCommand";
BA_ "SystemSignalLongSymbol" SG_ 2030 TRCM_a323_unarmedIC1FLDeployComm "TRCM_a323_unarmedIC1FLDeployCommand";
BA_ "SystemSignalLongSymbol" SG_ 2030 TRCM_a324_unarmedLoop24DeployCom "TRCM_a324_unarmedLoop24DeployCommand";
BA_ "SystemSignalLongSymbol" SG_ 2030 TRCM_a325_unarmedLoop25DeployCom "TRCM_a325_unarmedLoop25DeployCommand";
BA_ "SystemSignalLongSymbol" SG_ 2030 TRCM_a326_unarmedLoop26DeployCom "TRCM_a326_unarmedLoop26DeployCommand";
BA_ "SystemSignalLongSymbol" SG_ 2030 TRCM_a327_unarmedLoop27DeployCom "TRCM_a327_unarmedLoop27DeployCommand";
BA_ "SystemSignalLongSymbol" SG_ 2030 TRCM_a328_unarmedLoop28DeployCom "TRCM_a328_unarmedLoop28DeployCommand";
BA_ "SystemSignalLongSymbol" SG_ 2030 TRCM_a329_unarmedLoop29DeployCom "TRCM_a329_unarmedLoop29DeployCommand";
BA_ "SystemSignalLongSymbol" SG_ 2030 TRCM_a330_unarmedLoop30DeployCom "TRCM_a330_unarmedLoop30DeployCommand";
BA_ "SystemSignalLongSymbol" SG_ 2030 TRCM_a331_unarmedLoop31DeployCom "TRCM_a331_unarmedLoop31DeployCommand";
BA_ "SystemSignalLongSymbol" SG_ 2030 TRCM_a364_safingEngine0NoValidDa "TRCM_a364_safingEngine0NoValidData";
BA_ "SystemSignalLongSymbol" SG_ 2030 TRCM_a365_safingEngine1NoValidDa "TRCM_a365_safingEngine1NoValidData";
BA_ "SystemSignalLongSymbol" SG_ 2030 TRCM_a366_safingEngine2NoValidDa "TRCM_a366_safingEngine2NoValidData";
BA_ "SystemSignalLongSymbol" SG_ 2030 TRCM_a367_safingEngine3NoValidDa "TRCM_a367_safingEngine3NoValidData";
BA_ "SystemSignalLongSymbol" SG_ 2030 TRCM_a368_safingEngine4NoValidDa "TRCM_a368_safingEngine4NoValidData";
BA_ "SystemSignalLongSymbol" SG_ 2030 TRCM_a369_safingEngine5NoValidDa "TRCM_a369_safingEngine5NoValidData";
BA_ "SystemSignalLongSymbol" SG_ 2030 TRCM_a370_safingEngine6NoValidDa "TRCM_a370_safingEngine6NoValidData";
BA_ "SystemSignalLongSymbol" SG_ 2030 TRCM_a371_safingEngine7NoValidDa "TRCM_a371_safingEngine7NoValidData";
BA_ "SystemSignalLongSymbol" SG_ 2030 TRCM_a372_safingEngine8NoValidDa "TRCM_a372_safingEngine8NoValidData";
BA_ "SystemSignalLongSymbol" SG_ 2030 TRCM_a373_safingEngine9NoValidDa "TRCM_a373_safingEngine9NoValidData";
BA_ "SystemSignalLongSymbol" SG_ 2030 TRCM_a374_safingEngine10NoValidD "TRCM_a374_safingEngine10NoValidData";
BA_ "SystemSignalLongSymbol" SG_ 2030 TRCM_a375_safingEngine11NoValidD "TRCM_a375_safingEngine11NoValidData";
BA_ "SystemSignalLongSymbol" SG_ 2030 TRCM_a376_safingEngine12NoValidD "TRCM_a376_safingEngine12NoValidData";
BA_ "SystemSignalLongSymbol" SG_ 2030 TRCM_a377_safingEngine13NoValidD "TRCM_a377_safingEngine13NoValidData";
BA_ "SystemSignalLongSymbol" SG_ 2030 TRCM_a378_safingEngine14NoValidD "TRCM_a378_safingEngine14NoValidData";
BA_ "SystemSignalLongSymbol" SG_ 2030 TRCM_a379_safingEngine15NoValidD "TRCM_a379_safingEngine15NoValidData";
BA_ "SystemSignalLongSymbol" SG_ 2030 TRCM_a380_safingEngine16NoValidD "TRCM_a380_safingEngine16NoValidData";
BA_ "SystemSignalLongSymbol" SG_ 2030 TRCM_a381_safingEngine17NoValidD "TRCM_a381_safingEngine17NoValidData";
BA_ "SystemSignalLongSymbol" SG_ 2030 TRCM_a382_safingEngine18NoValidD "TRCM_a382_safingEngine18NoValidData";
BA_ "SystemSignalLongSymbol" SG_ 2030 TRCM_a383_safingEngine19NoValidD "TRCM_a383_safingEngine19NoValidData";
BA_ "SystemSignalLongSymbol" SG_ 2030 TRCM_a384_safingEngine20NoValidD "TRCM_a384_safingEngine20NoValidData";
BA_ "SystemSignalLongSymbol" SG_ 2030 TRCM_a385_safingEngine21NoValidD "TRCM_a385_safingEngine21NoValidData";
BA_ "SystemSignalLongSymbol" SG_ 2030 TRCM_a390_systemAsicClockOrOpera "TRCM_a390_systemAsicClockOrOperatingStateError";
BA_ "SystemSignalLongSymbol" SG_ 2030 TRCM_a391_extAsic1ClockOrOperati "TRCM_a391_extAsic1ClockOrOperatingStateError";
BA_ "SystemSignalLongSymbol" SG_ 2030 TRCM_a392_extAsic2ClockOrOperati "TRCM_a392_extAsic2ClockOrOperatingStateError";
BA_ "SystemSignalLongSymbol" SG_ 2030 TRCM_a393_depAdcConvertRatioErro "TRCM_a393_depAdcConvertRatioError";
BA_ "SystemSignalLongSymbol" SG_ 2030 TRCM_a394_gspiGlobalStatusWordEr "TRCM_a394_gspiGlobalStatusWordError";
BA_ "SystemSignalLongSymbol" SG_ 2030 TRCM_a396_spiCommunicationProgra "TRCM_a396_spiCommunicationProgramError";
BA_ "SystemSignalLongSymbol" SG_ 2030 TRCM_a460_BTRP_RetractorShortToG "TRCM_a460_BTRP_RetractorShortToGround";
BA_ "SystemSignalLongSymbol" SG_ 2030 TRCM_a461_BTRP_RetractorShortToB "TRCM_a461_BTRP_RetractorShortToBattery";
BA_ "SystemSignalLongSymbol" SG_ 2030 TRCM_a463_BTRP_RetractorShortToS "TRCM_a463_BTRP_RetractorShortToSelf";
BA_ "SystemSignalLongSymbol" SG_ 2030 TRCM_a464_BTRP_RetractorCrossCou "TRCM_a464_BTRP_RetractorCrossCoupled";
BA_ "SystemSignalLongSymbol" SG_ 2030 TRCM_a465_BTRP_RetractorConfigEr "TRCM_a465_BTRP_RetractorConfigError";
BA_ "SystemSignalLongSymbol" SG_ 2030 TRCM_a466_BTRD_RetractorShortToG "TRCM_a466_BTRD_RetractorShortToGround";
BA_ "SystemSignalLongSymbol" SG_ 2030 TRCM_a467_BTRD_RetractorShortToB "TRCM_a467_BTRD_RetractorShortToBattery";
BA_ "SystemSignalLongSymbol" SG_ 2030 TRCM_a469_BTRD_RetractorShortToS "TRCM_a469_BTRD_RetractorShortToSelf";
BA_ "SystemSignalLongSymbol" SG_ 2030 TRCM_a470_BTRD_RetractorCrossCou "TRCM_a470_BTRD_RetractorCrossCoupled";
BA_ "SystemSignalLongSymbol" SG_ 2030 TRCM_a471_BTRD_RetractorConfigEr "TRCM_a471_BTRD_RetractorConfigError";
BA_ "SystemSignalLongSymbol" SG_ 2030 TRCM_a496_BTRP_AnchorShortToGrou "TRCM_a496_BTRP_AnchorShortToGround";
BA_ "SystemSignalLongSymbol" SG_ 2030 TRCM_a497_BTRP_AnchorShortToBatt "TRCM_a497_BTRP_AnchorShortToBattery";
BA_ "SystemSignalLongSymbol" SG_ 2030 TRCM_a500_BTRP_AnchorCrossCouple "TRCM_a500_BTRP_AnchorCrossCoupled";
BA_ "SystemSignalLongSymbol" SG_ 2030 TRCM_a502_BTRD_AnchorShortToGrou "TRCM_a502_BTRD_AnchorShortToGround";
BA_ "SystemSignalLongSymbol" SG_ 2030 TRCM_a503_BTRD_AnchorShortToBatt "TRCM_a503_BTRD_AnchorShortToBattery";
BA_ "SystemSignalLongSymbol" SG_ 2030 TRCM_a506_BTRD_AnchorCrossCouple "TRCM_a506_BTRD_AnchorCrossCoupled";
BA_ "SystemSignalLongSymbol" SG_ 2030 TRCM_a545_erCapBelowAutarkyThres "TRCM_a545_erCapBelowAutarkyThreshold";
BA_ "SystemSignalLongSymbol" SG_ 2030 TRCM_a546_sensorValuesFaultedByS "TRCM_a546_sensorValuesFaultedBySmart";
BA_ "SystemSignalLongSymbol" SG_ 2030 TRCM_a550_AlgoWake_RCM_WAKE_FRON "TRCM_a550_AlgoWake_RCM_WAKE_FRONT";
BA_ "SystemSignalLongSymbol" SG_ 2030 TRCM_a553_AlgoWake_RCM_WAKE_RIGH "TRCM_a553_AlgoWake_RCM_WAKE_RIGHT";
BA_ "SystemSignalLongSymbol" SG_ 2030 TRCM_a554_AlgoWake_PAS_LH_PLAUSI "TRCM_a554_AlgoWake_PAS_LH_PLAUSI_FRONT";
BA_ "SystemSignalLongSymbol" SG_ 2030 TRCM_a555_AlgoWake_PAS_LH_PLAUSI "TRCM_a555_AlgoWake_PAS_LH_PLAUSI_REAR";
BA_ "SystemSignalLongSymbol" SG_ 2030 TRCM_a557_AlgoWake_PAS_RH_PLAUSI "TRCM_a557_AlgoWake_PAS_RH_PLAUSI_FRONT";
BA_ "SystemSignalLongSymbol" SG_ 2030 TRCM_a558_AlgoWake_PAS_RH_PLAUSI "TRCM_a558_AlgoWake_PAS_RH_PLAUSI_REAR";
BA_ "SystemSignalLongSymbol" SG_ 2030 TRCM_a560_AlgoWake_RCM_WAKE_ROLL "TRCM_a560_AlgoWake_RCM_WAKE_ROLL_LEFT";
BA_ "SystemSignalLongSymbol" SG_ 2030 TRCM_a561_AlgoWake_RCM_WAKE_ROLL "TRCM_a561_AlgoWake_RCM_WAKE_ROLL_RIGHT";
BA_ "SystemSignalLongSymbol" SG_ 2030 TRCM_a562_AlgoWake_RCM_AWAKE_FRO "TRCM_a562_AlgoWake_RCM_AWAKE_FRONT";
BA_ "SystemSignalLongSymbol" SG_ 2030 TRCM_a563_AlgoWake_RCM_AWAKE_REA "TRCM_a563_AlgoWake_RCM_AWAKE_REAR";
BA_ "SystemSignalLongSymbol" SG_ 2030 TRCM_a564_AlgoWake_RCM_AWAKE_LEF "TRCM_a564_AlgoWake_RCM_AWAKE_LEFT";
BA_ "SystemSignalLongSymbol" SG_ 2030 TRCM_a565_AlgoWake_RCM_AWAKE_RIG "TRCM_a565_AlgoWake_RCM_AWAKE_RIGHT";
BA_ "SystemSignalLongSymbol" SG_ 2030 TRCM_a566_AlgoWake_RCM_AWAKE_ROL "TRCM_a566_AlgoWake_RCM_AWAKE_ROLL";
BA_ "SystemSignalLongSymbol" SG_ 2030 TRCM_a569_AlgoWake_IMPACT_FINISH "TRCM_a569_AlgoWake_IMPACT_FINISH_X_FRONT";
BA_ "SystemSignalLongSymbol" SG_ 2030 TRCM_a570_AlgoWake_IMPACT_FINISH "TRCM_a570_AlgoWake_IMPACT_FINISH_X_REAR";
BA_ "SystemSignalLongSymbol" SG_ 2030 TRCM_a571_AlgoWake_IMPACT_FINISH "TRCM_a571_AlgoWake_IMPACT_FINISH_Y_RCM_POS";
BA_ "SystemSignalLongSymbol" SG_ 2030 TRCM_a572_AlgoWake_IMPACT_FINISH "TRCM_a572_AlgoWake_IMPACT_FINISH_Y_RCM_NEG";
BA_ "SystemSignalLongSymbol" SG_ 2030 TRCM_a573_AlgoWake_IMPACT_FINISH "TRCM_a573_AlgoWake_IMPACT_FINISH_Y_RCM";
BA_ "SystemSignalLongSymbol" SG_ 2030 TRCM_a574_AlgoWake_IMPACT_FINISH "TRCM_a574_AlgoWake_IMPACT_FINISH_ROLL_RIGHT";
BA_ "SystemSignalLongSymbol" SG_ 2030 TRCM_a575_AlgoWake_IMPACT_FINISH "TRCM_a575_AlgoWake_IMPACT_FINISH_ROLL_LEFT";
BA_ "SystemSignalLongSymbol" SG_ 2030 TRCM_a576_AlgoWake_IMPACT_FINISH "TRCM_a576_AlgoWake_IMPACT_FINISH_X";
BA_ "SystemSignalLongSymbol" SG_ 2030 TRCM_a577_AlgoWake_IMPACT_FINISH "TRCM_a577_AlgoWake_IMPACT_FINISH_Y";
BA_ "SystemSignalLongSymbol" SG_ 2030 TRCM_a578_AlgoWake_IMPACT_FINISH "TRCM_a578_AlgoWake_IMPACT_FINISH_ROLL";
BA_ "SystemSignalLongSymbol" SG_ 2030 TRCM_a581_AlgoWake_RCM_ENABLED_R "TRCM_a581_AlgoWake_RCM_ENABLED_ROLL";
BA_ "SystemSignalLongSymbol" SG_ 2030 TRCM_a590_pitchRateOffsetPosLimi "TRCM_a590_pitchRateOffsetPosLimit";
BA_ "SystemSignalLongSymbol" SG_ 2030 TRCM_a591_pitchRateOffsetNegLimi "TRCM_a591_pitchRateOffsetNegLimit";
BA_ "SystemSignalLongSymbol" SG_ 2030 TRCM_a594_longitudinalAccelOffse "TRCM_a594_longitudinalAccelOffsetPosLimit";
BA_ "SystemSignalLongSymbol" SG_ 2030 TRCM_a595_longitudinalAccelOffse "TRCM_a595_longitudinalAccelOffsetNegLimit";
BA_ "SystemSignalLongSymbol" SG_ 2030 TRCM_a596_lateralAccelOffsetPosL "TRCM_a596_lateralAccelOffsetPosLimit";
BA_ "SystemSignalLongSymbol" SG_ 2030 TRCM_a597_lateralAccelOffsetNegL "TRCM_a597_lateralAccelOffsetNegLimit";
BA_ "SystemSignalLongSymbol" SG_ 2030 TRCM_a598_verticalAccelOffsetPos "TRCM_a598_verticalAccelOffsetPosLimit";
BA_ "SystemSignalLongSymbol" SG_ 2030 TRCM_a599_verticalAccelOffsetNeg "TRCM_a599_verticalAccelOffsetNegLimit";
BA_ "SystemSignalLongSymbol" SG_ 2030 TRCM_a600_airbagAsicStartupFailu "TRCM_a600_airbagAsicStartupFailure";
BA_ "SystemSignalLongSymbol" SG_ 2030 TRCM_a601_loop0AsicStartupDiagno "TRCM_a601_loop0AsicStartupDiagnosticFailure";
BA_ "SystemSignalLongSymbol" SG_ 2030 TRCM_a602_loop1AsicStartupDiagno "TRCM_a602_loop1AsicStartupDiagnosticFailure";
BA_ "SystemSignalLongSymbol" SG_ 2030 TRCM_a603_loop2AsicStartupDiagno "TRCM_a603_loop2AsicStartupDiagnosticFailure";
BA_ "SystemSignalLongSymbol" SG_ 2030 TRCM_a604_loop3AsicStartupDiagno "TRCM_a604_loop3AsicStartupDiagnosticFailure";
BA_ "SystemSignalLongSymbol" SG_ 2030 TRCM_a605_loop4AsicStartupDiagno "TRCM_a605_loop4AsicStartupDiagnosticFailure";
BA_ "SystemSignalLongSymbol" SG_ 2030 TRCM_a606_loop5AsicStartupDiagno "TRCM_a606_loop5AsicStartupDiagnosticFailure";
BA_ "SystemSignalLongSymbol" SG_ 2030 TRCM_a607_loop6AsicStartupDiagno "TRCM_a607_loop6AsicStartupDiagnosticFailure";
BA_ "SystemSignalLongSymbol" SG_ 2030 TRCM_a608_loop7AsicStartupDiagno "TRCM_a608_loop7AsicStartupDiagnosticFailure";
BA_ "SystemSignalLongSymbol" SG_ 2030 TRCM_a609_loop8AsicStartupDiagno "TRCM_a609_loop8AsicStartupDiagnosticFailure";
BA_ "SystemSignalLongSymbol" SG_ 2030 TRCM_a610_loop9AsicStartupDiagno "TRCM_a610_loop9AsicStartupDiagnosticFailure";
BA_ "SystemSignalLongSymbol" SG_ 2030 TRCM_a611_loop10AsicStartupDiagn "TRCM_a611_loop10AsicStartupDiagnosticFailure";
BA_ "SystemSignalLongSymbol" SG_ 2030 TRCM_a612_loop11AsicStartupDiagn "TRCM_a612_loop11AsicStartupDiagnosticFailure";
BA_ "SystemSignalLongSymbol" SG_ 2030 TRCM_a613_loop12AsicStartupDiagn "TRCM_a613_loop12AsicStartupDiagnosticFailure";
BA_ "SystemSignalLongSymbol" SG_ 2030 TRCM_a614_loop13AsicStartupDiagn "TRCM_a614_loop13AsicStartupDiagnosticFailure";
BA_ "SystemSignalLongSymbol" SG_ 2030 TRCM_a615_loop14AsicStartupDiagn "TRCM_a615_loop14AsicStartupDiagnosticFailure";
BA_ "SystemSignalLongSymbol" SG_ 2030 TRCM_a616_loop15AsicStartupDiagn "TRCM_a616_loop15AsicStartupDiagnosticFailure";
BA_ "SystemSignalLongSymbol" SG_ 2030 TRCM_a617_loop16AsicStartupDiagn "TRCM_a617_loop16AsicStartupDiagnosticFailure";
BA_ "SystemSignalLongSymbol" SG_ 2030 TRCM_a618_loop17AsicStartupDiagn "TRCM_a618_loop17AsicStartupDiagnosticFailure";
BA_ "SystemSignalLongSymbol" SG_ 2030 TRCM_a619_loop18AsicStartupDiagn "TRCM_a619_loop18AsicStartupDiagnosticFailure";
BA_ "SystemSignalLongSymbol" SG_ 2030 TRCM_a620_loop19AsicStartupDiagn "TRCM_a620_loop19AsicStartupDiagnosticFailure";
BA_ "SystemSignalLongSymbol" SG_ 2030 TRCM_a621_loop20AsicStartupDiagn "TRCM_a621_loop20AsicStartupDiagnosticFailure";
BA_ "SystemSignalLongSymbol" SG_ 2030 TRCM_a622_loop21AsicStartupDiagn "TRCM_a622_loop21AsicStartupDiagnosticFailure";
BA_ "SystemSignalLongSymbol" SG_ 2030 TRCM_a623_loop22AsicStartupDiagn "TRCM_a623_loop22AsicStartupDiagnosticFailure";
BA_ "SystemSignalLongSymbol" SG_ 2030 TRCM_a624_loop23AsicStartupDiagn "TRCM_a624_loop23AsicStartupDiagnosticFailure";
BA_ "SystemSignalLongSymbol" SG_ 2030 TRCM_a625_loop24AsicStartupDiagn "TRCM_a625_loop24AsicStartupDiagnosticFailure";
BA_ "SystemSignalLongSymbol" SG_ 2030 TRCM_a626_loop25AsicStartupDiagn "TRCM_a626_loop25AsicStartupDiagnosticFailure";
BA_ "SystemSignalLongSymbol" SG_ 2030 TRCM_a627_loop26AsicStartupDiagn "TRCM_a627_loop26AsicStartupDiagnosticFailure";
BA_ "SystemSignalLongSymbol" SG_ 2030 TRCM_a628_loop27AsicStartupDiagn "TRCM_a628_loop27AsicStartupDiagnosticFailure";
BA_ "SystemSignalLongSymbol" SG_ 2030 TRCM_a629_loop28AsicStartupDiagn "TRCM_a629_loop28AsicStartupDiagnosticFailure";
BA_ "SystemSignalLongSymbol" SG_ 2030 TRCM_a630_loop29AsicStartupDiagn "TRCM_a630_loop29AsicStartupDiagnosticFailure";
BA_ "SystemSignalLongSymbol" SG_ 2030 TRCM_a631_loop30AsicStartupDiagn "TRCM_a631_loop30AsicStartupDiagnosticFailure";
BA_ "SystemSignalLongSymbol" SG_ 2030 TRCM_a632_loop31AsicStartupDiagn "TRCM_a632_loop31AsicStartupDiagnosticFailure";
BA_ "Confidence" SG_ 1641 UDS_KOSTIAsccmRequestData 1;
BA_ "Confidence" SG_ 1538 UDS_bmsRequestData 1;
BA_ "Confidence" SG_ 1579 UDS_ccRequestData 1;
BA_ "Confidence" SG_ 1539 UDS_cmpRequestData 1;
BA_ "Confidence" SG_ 1543 UDS_cmpdRequestData 1;
BA_ "Confidence" SG_ 1550 UDS_cpRequestData 1;
BA_ "Confidence" SG_ 1609 UDS_dasRequestData 1;
BA_ "Confidence" SG_ 1589 UDS_diRequestData 1;
BA_ "Confidence" SG_ 1541 UDS_difRequestData 1;
BA_ "Confidence" SG_ 1542 UDS_dirRequestData 1;
BA_ "Confidence" SG_ 1584 UDS_epas3pRequestData 1;
BA_ "Confidence" SG_ 1840 UDS_epas3sRequestData 1;
BA_ "Confidence" SG_ 1572 UDS_epblRequestData_H 1;
BA_ "Confidence" SG_ 1572 UDS_epblRequestData_L 1;
BA_ "Confidence" SG_ 1574 UDS_epbrRequestData_H 1;
BA_ "Confidence" SG_ 1574 UDS_epbrRequestData_L 1;
BA_ "Confidence" SG_ 1605 UDS_espRequestData 1;
BA_ "Confidence" SG_ 2015 UDS_functionalRequestData_0 1;
BA_ "Confidence" SG_ 2015 UDS_functionalRequestData_1 1;
BA_ "Confidence" SG_ 2015 UDS_functionalRequestData_2 1;
BA_ "Confidence" SG_ 2015 UDS_functionalRequestData_3 1;
BA_ "Confidence" SG_ 2015 UDS_functionalRequestData_4 1;
BA_ "Confidence" SG_ 2015 UDS_functionalRequestData_5 1;
BA_ "Confidence" SG_ 2015 UDS_functionalRequestData_6 1;
BA_ "Confidence" SG_ 2015 UDS_functionalRequestData_7 1;
BA_ "Confidence" SG_ 2014 UDS_functionalRequestDataCH 1;
BA_ "Confidence" SG_ 1552 UDS_hvpRequestData 1;
BA_ "Confidence" SG_ 1613 UDS_ibstRequestData 1;
BA_ "Confidence" SG_ 1560 UDS_icrRequestData 1;
BA_ "Confidence" SG_ 1603 UDS_ocs1pRequestData 1;
BA_ "Confidence" SG_ 1614 UDS_parkRequestData 1;
BA_ "Confidence" SG_ 1576 UDS_pcsRequestData 1;
BA_ "Confidence" SG_ 1634 UDS_plgRequestData 1;
BA_ "Confidence" SG_ 1568 UDS_pmRequestData 1;
BA_ "Confidence" SG_ 1604 UDS_pmfRequestData 1;
BA_ "Confidence" SG_ 1540 UDS_pmrRequestData 1;
BA_ "Confidence" SG_ 1734 UDS_ptcRequestData 1;
BA_ "Confidence" SG_ 1649 UDS_radcRequestData 1;
BA_ "Confidence" SG_ 1601 UDS_rcmRequestData 1;
BA_ "Confidence" SG_ 1664 UDS_sccmRequestData 1;
BA_ "Confidence" SG_ 1723 UDS_sdcrRequestData 1;
BA_ "Confidence" SG_ 1611 UDS_tasRequestData 1;
BA_ "Confidence" SG_ 1551 UDS_thcRequestData_H 1;
BA_ "Confidence" SG_ 1551 UDS_thcRequestData_L 1;
BA_ "Confidence" SG_ 1615 UDS_tpmsRequestData 1;
BA_ "Confidence" SG_ 1578 UDS_vcbatt1RequestData 1;
BA_ "Confidence" SG_ 1588 UDS_vcbatt2RequestData 1;
BA_ "Confidence" SG_ 1636 UDS_vcbattRequestData 1;
BA_ "Confidence" SG_ 1580 UDS_vcfront1RequestData 1;
BA_ "Confidence" SG_ 1582 UDS_vcfront2RequestData 1;
BA_ "Confidence" SG_ 1536 UDS_vcfrontRequestData 1;
BA_ "Confidence" SG_ 1570 UDS_vcleftRequestData_H 1;
BA_ "Confidence" SG_ 1570 UDS_vcleftRequestData_L 1;
BA_ "Confidence" SG_ 1544 UDS_vcrightRequestData_H 1;
BA_ "Confidence" SG_ 1544 UDS_vcrightRequestData_L 1;
BA_ "Confidence" SG_ 1546 UDS_vcsecRequestData 1;
VAL_ 2030 TRCM_matrixIndex 10 "AlertMatrix10" 9 "AlertMatrix9" 8 "AlertMatrix8" 7 "AlertMatrix7" 6 "AlertMatrix6" 5 "AlertMatrix5" 4 "AlertMatrix4" 3 "AlertMatrix3" 2 "AlertMatrix2" 1 "AlertMatrix1" 0 "AlertMatrix0" ;
